VERSION "BodyCAN"

NS_ :

BS_:

BU_: CCM CEM DDM ETC ILCM PDM POT RLDM RRDM SMD SMP TRM Vector_XXX

BO_ 150 CEMBodyFr16: 8 CEM
 SG_ FirstRowLeDefdMassgProgCfg_UB : 5|1@0+ (1,0) [0|1] ""  SMD
 SG_ FirstRowLeDefdMassgProgCfgMassgB : 15|1@0+ (1,0) [0|1] ""  SMD
 SG_ FirstRowLeDefdMassgProgCfgM_0000 : 14|1@0+ (1,0) [0|1] ""  SMD
 SG_ FirstRowLeDefdMassgProgCfgM_0001 : 13|1@0+ (1,0) [0|1] ""  SMD
 SG_ FirstRowLeDefdMassgProgCfgM_0002 : 12|1@0+ (1,0) [0|1] ""  SMD
 SG_ FirstRowLeDefdMassgProgCfgM_0003 : 11|1@0+ (1,0) [0|1] ""  SMD
 SG_ FirstRowLeDefdMassgProgCfgM_0004 : 10|1@0+ (1,0) [0|1] ""  SMD
 SG_ FirstRowLeDefdMassgProgCfgM_0005 : 9|1@0+ (1,0) [0|1] ""  SMD
 SG_ FirstRowLeDefdMassgProgCfgM_0006 : 8|1@0+ (1,0) [0|1] ""  SMD
 SG_ FirstRowLeDefdMassgProgCfgM_0007 : 23|1@0+ (1,0) [0|1] ""  SMD
 SG_ FirstRowLeDefdMassgProgCfgM_0008 : 22|1@0+ (1,0) [0|1] ""  SMD
 SG_ FirstRowLeDefdMassgProgCfgM_0009 : 21|1@0+ (1,0) [0|1] ""  SMD
 SG_ FirstRowLeDefdMassgProgCfgM_0010 : 20|1@0+ (1,0) [0|1] ""  SMD
 SG_ FirstRowLeDefdMassgProgCfgM_0011 : 19|1@0+ (1,0) [0|1] ""  SMD
 SG_ FirstRowLeDefdMassgProgCfgM_0012 : 18|1@0+ (1,0) [0|1] ""  SMD
 SG_ FirstRowLeDefdMassgProgCfgM_0013 : 17|1@0+ (1,0) [0|1] ""  SMD
 SG_ FirstRowLeDefdMassgProgCfgM_0014 : 16|1@0+ (1,0) [0|1] ""  SMD
 SG_ FirstRowLeDefdMassgProgCfgMassgF : 31|2@0+ (1,0) [0|3] ""  SMD
 SG_ FirstRowLeDefdMassgProgCfgMassgI : 29|2@0+ (1,0) [0|3] ""  SMD
 SG_ FirstRowLeDefdMassgProgCfgMassPr : 27|4@0+ (1,0) [0|15] "Unitless"  SMD
 SG_ FirstRowLeDefdMassgProgCfgM_0015 : 1|2@0+ (1,0) [0|3] ""  SMD
 SG_ FirstRowLeDefdMassgProgCfgMassSe : 4|3@0+ (1,0) [0|7] "Unitless"  SMD
 SG_ FirstRowRiDefdMassgProgCfg_UB : 37|1@0+ (1,0) [0|1] ""  SMP
 SG_ FirstRowRiDefdMassgProgCfgMassgB : 47|1@0+ (1,0) [0|1] ""  SMP
 SG_ FirstRowRiDefdMassgProgCfgM_0000 : 46|1@0+ (1,0) [0|1] ""  SMP
 SG_ FirstRowRiDefdMassgProgCfgM_0001 : 45|1@0+ (1,0) [0|1] ""  SMP
 SG_ FirstRowRiDefdMassgProgCfgM_0002 : 44|1@0+ (1,0) [0|1] ""  SMP
 SG_ FirstRowRiDefdMassgProgCfgM_0003 : 43|1@0+ (1,0) [0|1] ""  SMP
 SG_ FirstRowRiDefdMassgProgCfgM_0004 : 42|1@0+ (1,0) [0|1] ""  SMP
 SG_ FirstRowRiDefdMassgProgCfgM_0005 : 41|1@0+ (1,0) [0|1] ""  SMP
 SG_ FirstRowRiDefdMassgProgCfgM_0006 : 40|1@0+ (1,0) [0|1] ""  SMP
 SG_ FirstRowRiDefdMassgProgCfgM_0007 : 55|1@0+ (1,0) [0|1] ""  SMP
 SG_ FirstRowRiDefdMassgProgCfgM_0008 : 54|1@0+ (1,0) [0|1] ""  SMP
 SG_ FirstRowRiDefdMassgProgCfgM_0009 : 53|1@0+ (1,0) [0|1] ""  SMP
 SG_ FirstRowRiDefdMassgProgCfgM_0010 : 52|1@0+ (1,0) [0|1] ""  SMP
 SG_ FirstRowRiDefdMassgProgCfgM_0011 : 51|1@0+ (1,0) [0|1] ""  SMP
 SG_ FirstRowRiDefdMassgProgCfgM_0012 : 50|1@0+ (1,0) [0|1] ""  SMP
 SG_ FirstRowRiDefdMassgProgCfgM_0013 : 49|1@0+ (1,0) [0|1] ""  SMP
 SG_ FirstRowRiDefdMassgProgCfgM_0014 : 48|1@0+ (1,0) [0|1] ""  SMP
 SG_ FirstRowRiDefdMassgProgCfgMassgF : 63|2@0+ (1,0) [0|3] ""  SMP
 SG_ FirstRowRiDefdMassgProgCfgMassgI : 61|2@0+ (1,0) [0|3] ""  SMP
 SG_ FirstRowRiDefdMassgProgCfgMassPr : 59|4@0+ (1,0) [0|15] "Unitless"  SMP
 SG_ FirstRowRiDefdMassgProgCfgM_0015 : 33|2@0+ (1,0) [0|3] ""  SMP
 SG_ FirstRowRiDefdMassgProgCfgMassSe : 36|3@0+ (1,0) [0|7] "Unitless"  SMP

BO_ 528 CEMBodyFr19: 8 CEM
 SG_ CoolgLoadGroup_UB : 24|1@0+ (1,0) [0|1] ""  CCM
 SG_ CoolgLoadGroupCoolgLimd : 39|1@0+ (1,0) [0|1] ""  CCM
 SG_ CoolgLoadGroupCoolgLoad2 : 38|7@0+ (1,0) [0|100] "%"  CCM
 SG_ EngT_UB : 10|1@0+ (1,0) [0|1] ""  CCM
 SG_ EngTEngT : 23|8@0+ (1,-50) [-50|200] "degC"  CCM
 SG_ EngTQf : 9|2@0+ (1,0) [0|3] ""  CCM
 SG_ HvPwrEgyPrio : 42|3@0+ (1,0) [0|7] ""  CCM
 SG_ HvPwrEgyPrio_UB : 43|1@0+ (1,0) [0|1] ""  CCM
 SG_ MirrDefrstAtDrvrCmd : 59|1@0+ (1,0) [0|1] ""  DDM
 SG_ MirrDefrstAtDrvrCmd_UB : 58|1@0+ (1,0) [0|1] ""  DDM
 SG_ MirrDefrstAtPassCmd : 57|1@0+ (1,0) [0|1] ""  PDM
 SG_ MirrDefrstAtPassCmd_UB : 56|1@0+ (1,0) [0|1] ""  PDM
 SG_ PassSeatSts : 55|2@0+ (1,0) [0|3] ""  CCM
 SG_ PassSeatSts_UB : 63|1@0+ (1,0) [0|1] ""  CCM
 SG_ SeatDispBtnPsd_UB : 60|1@0+ (1,0) [0|1] ""  SMD,SMP
 SG_ SeatDispBtnPsdDrvrSeatDispBtnPsd : 61|1@0+ (1,0) [0|1] ""  SMD,SMP
 SG_ SeatDispBtnPsdPassSeatDispBtnPsd : 62|1@0+ (1,0) [0|1] ""  SMD,SMP
 SG_ SeatOccptAtRowSecLe : 27|2@0+ (1,0) [0|3] ""  CCM
 SG_ SeatOccptAtRowSecLe_UB : 28|1@0+ (1,0) [0|1] ""  CCM
 SG_ SeatOccptAtRowSecRi : 30|2@0+ (1,0) [0|3] ""  CCM
 SG_ SeatOccptAtRowSecRi_UB : 31|1@0+ (1,0) [0|1] ""  CCM

BO_ 298 CEMBodyFr20: 8 CEM
 SG_ DoorsOpenerReq_UB : 38|1@0+ (1,0) [0|1] ""  DDM,PDM,RLDM,RRDM
 SG_ DoorsOpenerReqChks : 7|8@0+ (1,0) [0|255] "Unitless"  DDM,PDM,RLDM,RRDM
 SG_ DoorsOpenerReqCntr : 15|4@0+ (1,0) [0|15] "Unitless"  DDM,PDM,RLDM,RRDM
 SG_ DoorsOpenerReqDrvr : 11|2@0+ (1,0) [0|3] ""  DDM,PDM,RLDM,RRDM
 SG_ DoorsOpenerReqLeRe : 9|2@0+ (1,0) [0|3] ""  DDM,PDM,RLDM,RRDM
 SG_ DoorsOpenerReqPass : 23|2@0+ (1,0) [0|3] ""  DDM,PDM,RLDM,RRDM
 SG_ DoorsOpenerReqRiRe : 31|2@0+ (1,0) [0|3] ""  DDM,PDM,RLDM,RRDM
 SG_ DoorsOpenerReqTrigSrcDrvr : 21|3@0+ (1,0) [0|7] ""  DDM,PDM,RLDM,RRDM
 SG_ DoorsOpenerReqTrigSrcLeRe : 18|3@0+ (1,0) [0|7] ""  DDM,PDM,RLDM,RRDM
 SG_ DoorsOpenerReqTrigSrcPass : 29|3@0+ (1,0) [0|7] ""  DDM,PDM,RLDM,RRDM
 SG_ DoorsOpenerReqTrigSrcRiRe : 26|3@0+ (1,0) [0|7] ""  DDM,PDM,RLDM,RRDM
 SG_ DoorsOpenerReqVehMtnSts : 39|1@0+ (1,0) [0|1] ""  DDM,PDM,RLDM,RRDM
 SG_ SecRowRiDefdMassgProgCfg_UB : 37|1@0+ (1,0) [0|1] ""  Vector_XXX
 SG_ SecRowRiDefdMassgProgCfgMassgBag : 47|1@0+ (1,0) [0|1] ""  Vector_XXX
 SG_ SecRowRiDefdMassgProgCfgMas_0000 : 46|1@0+ (1,0) [0|1] ""  Vector_XXX
 SG_ SecRowRiDefdMassgProgCfgMas_0001 : 45|1@0+ (1,0) [0|1] ""  Vector_XXX
 SG_ SecRowRiDefdMassgProgCfgMas_0002 : 44|1@0+ (1,0) [0|1] ""  Vector_XXX
 SG_ SecRowRiDefdMassgProgCfgMas_0003 : 43|1@0+ (1,0) [0|1] ""  Vector_XXX
 SG_ SecRowRiDefdMassgProgCfgMas_0004 : 42|1@0+ (1,0) [0|1] ""  Vector_XXX
 SG_ SecRowRiDefdMassgProgCfgMas_0005 : 41|1@0+ (1,0) [0|1] ""  Vector_XXX
 SG_ SecRowRiDefdMassgProgCfgMas_0006 : 40|1@0+ (1,0) [0|1] ""  Vector_XXX
 SG_ SecRowRiDefdMassgProgCfgMas_0007 : 55|1@0+ (1,0) [0|1] ""  Vector_XXX
 SG_ SecRowRiDefdMassgProgCfgMas_0008 : 54|1@0+ (1,0) [0|1] ""  Vector_XXX
 SG_ SecRowRiDefdMassgProgCfgMas_0009 : 53|1@0+ (1,0) [0|1] ""  Vector_XXX
 SG_ SecRowRiDefdMassgProgCfgMas_0010 : 52|1@0+ (1,0) [0|1] ""  Vector_XXX
 SG_ SecRowRiDefdMassgProgCfgMas_0011 : 51|1@0+ (1,0) [0|1] ""  Vector_XXX
 SG_ SecRowRiDefdMassgProgCfgMas_0012 : 50|1@0+ (1,0) [0|1] ""  Vector_XXX
 SG_ SecRowRiDefdMassgProgCfgMas_0013 : 49|1@0+ (1,0) [0|1] ""  Vector_XXX
 SG_ SecRowRiDefdMassgProgCfgMas_0014 : 48|1@0+ (1,0) [0|1] ""  Vector_XXX
 SG_ SecRowRiDefdMassgProgCfgMassgFrq : 63|2@0+ (1,0) [0|3] ""  Vector_XXX
 SG_ SecRowRiDefdMassgProgCfgMassgInt : 61|2@0+ (1,0) [0|3] ""  Vector_XXX
 SG_ SecRowRiDefdMassgProgCfgMassProg : 59|4@0+ (1,0) [0|15] "Unitless"  Vector_XXX
 SG_ SecRowRiDefdMassgProgCfgMas_0015 : 33|2@0+ (1,0) [0|3] ""  Vector_XXX
 SG_ SecRowRiDefdMassgProgCfgMassSeqC : 36|3@0+ (1,0) [0|7] "Unitless"  Vector_XXX

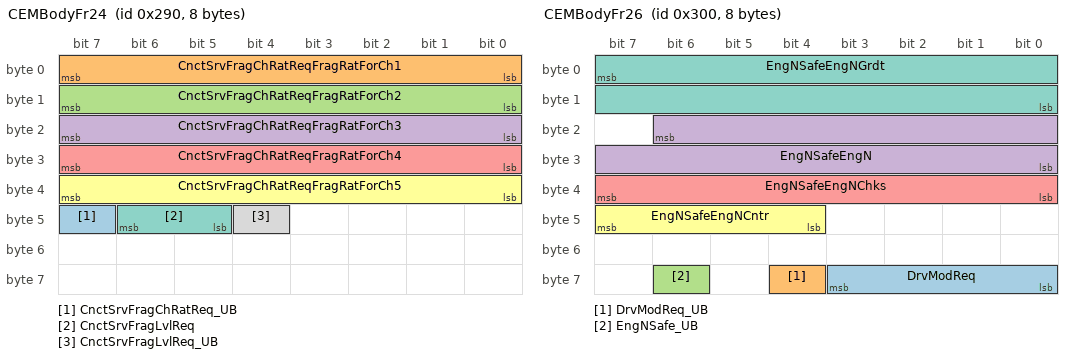
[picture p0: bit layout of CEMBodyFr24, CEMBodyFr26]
BO_ 656 CEMBodyFr24: 8 CEM
 SG_ CnctSrvFragChRatReq_UB : 47|1@0+ (1,0) [0|1] ""  CCM
 SG_ CnctSrvFragChRatReqFragRatForCh1 : 7|8@0+ (1,0) [0|100] "%"  CCM
 SG_ CnctSrvFragChRatReqFragRatForCh2 : 15|8@0+ (1,0) [0|100] "%"  CCM
 SG_ CnctSrvFragChRatReqFragRatForCh3 : 23|8@0+ (1,0) [0|100] "%"  CCM
 SG_ CnctSrvFragChRatReqFragRatForCh4 : 31|8@0+ (1,0) [0|100] "%"  CCM
 SG_ CnctSrvFragChRatReqFragRatForCh5 : 39|8@0+ (1,0) [0|100] "%"  CCM
 SG_ CnctSrvFragLvlReq : 46|2@0+ (1,0) [0|3] ""  CCM
 SG_ CnctSrvFragLvlReq_UB : 44|1@0+ (1,0) [0|1] ""  CCM

BO_ 768 CEMBodyFr26: 8 CEM
 SG_ DrvModReq : 59|4@0+ (1,0) [0|15] ""  CCM,ILCM,SMD
 SG_ DrvModReq_UB : 60|1@0+ (1,0) [0|1] ""  CCM,ILCM,SMD
 SG_ EngNSafe_UB : 62|1@0+ (1,0) [0|1] ""  CCM
 SG_ EngNSafeEngN : 22|15@0+ (0.5,0) [0|16383.5] "rpm"  CCM
 SG_ EngNSafeEngNChks : 39|8@0+ (1,0) [0|255] "Unitless"  CCM
 SG_ EngNSafeEngNCntr : 47|4@0+ (1,0) [0|15] "Unitless"  CCM
 SG_ EngNSafeEngNGrdt : 7|16@0- (1,0) [-30000|32767] "RpmPerSec"  CCM

BO_ 784 CEMBodyFr27: 8 CEM
 SG_ BkpOfDstTrvld : 4|21@0+ (1,0) [0|2000000] "km"  CCM,DDM,ILCM,PDM,POT,RLDM,RRDM,SMD,SMP,TRM
 SG_ BkpOfDstTrvld_UB : 5|1@0+ (1,0) [0|1] ""  CCM,DDM,ILCM,PDM,POT,RLDM,RRDM,SMD,SMP,TRM
 SG_ CamSts_UB : 57|1@0+ (1,0) [0|1] ""  CCM
 SG_ CamStsCamCamFrntCalNotCmpl : 35|1@0+ (1,0) [0|1] ""  CCM
 SG_ CamStsCamCamHeatrActv : 34|1@0+ (1,0) [0|1] ""  CCM
 SG_ CamStsCamFrntBlkd1 : 33|1@0+ (1,0) [0|1] ""  CCM
 SG_ CamStsCamFrntBlkd2 : 32|1@0+ (1,0) [0|1] ""  CCM
 SG_ CamStsCamFrntBlkd3 : 47|1@0+ (1,0) [0|1] ""  CCM
 SG_ CamStsCamFrntBlkd4 : 46|1@0+ (1,0) [0|1] ""  CCM
 SG_ CamStsCamFrntBlkd5 : 45|1@0+ (1,0) [0|1] ""  CCM
 SG_ CamStsCamFrntBlkd6 : 44|1@0+ (1,0) [0|1] ""  CCM
 SG_ CamStsCamFrntBlkd7 : 43|1@0+ (1,0) [0|1] ""  CCM
 SG_ CamStsCamFrntBlkd8 : 42|1@0+ (1,0) [0|1] ""  CCM
 SG_ CamStsCamFrntCalNotStrtd : 41|1@0+ (1,0) [0|1] ""  CCM
 SG_ CamStsCamFrntFaulty : 53|12@0+ (1,0) [0|4095] "Unitless"  CCM
 SG_ CamStsCamFrontEna : 55|1@0+ (1,0) [0|1] ""  CCM
 SG_ CamStsCamMissCom : 54|1@0+ (1,0) [0|1] ""  CCM
 SG_ CamStsChks : 31|8@0+ (1,0) [0|255] "Unitless"  CCM
 SG_ CamStsCntr : 39|4@0+ (1,0) [0|15] "Unitless"  CCM

BO_ 464 CEMBodyFr28: 8 CEM
 SG_ AirTFromHeatgEstimd : 52|13@0- (0.1,0) [-256|255.9] "degC"  CCM
 SG_ AirTFromHeatgEstimd_UB : 53|1@0+ (1,0) [0|1] ""  CCM
 SG_ EcmRoilgCntr : 47|8@0+ (1,0) [0|255] "Unitless"  CCM
 SG_ EcmRoilgCntr_UB : 55|1@0+ (1,0) [0|1] ""  CCM
 SG_ RoadIncln_UB : 29|1@0+ (1,0) [0|1] ""  CCM
 SG_ RoadInclnQly : 31|2@0+ (1,0) [0|3] ""  CCM
 SG_ RoadInclnRoadIncln : 15|16@0- (3.0518E-005,0) [-0.999983306|0.999983306] "rad"  CCM
 SG_ SeatOccptAtRowSecMid : 1|2@0+ (1,0) [0|3] ""  CCM
 SG_ SeatOccptAtRowSecMid_UB : 2|1@0+ (1,0) [0|1] ""  CCM
 SG_ SunCurtPosnSts : 28|5@0+ (1,0) [0|31] ""  CCM
 SG_ SunCurtPosnSts_UB : 54|1@0+ (1,0) [0|1] ""  CCM
 SG_ SunRoofPosnSts : 7|5@0+ (1,0) [0|31] ""  CCM
 SG_ SunRoofPosnSts_UB : 38|1@0+ (1,0) [0|1] ""  CCM
 SG_ WipgInfo_UB : 37|1@0+ (1,0) [0|1] ""  CCM
 SG_ WipgInfoWipgSpdInfo : 34|3@0+ (1,0) [0|7] ""  CCM
 SG_ WipgInfoWiprActv : 35|1@0+ (1,0) [0|1] ""  CCM
 SG_ WipgInfoWiprInWipgAr : 36|1@0+ (1,0) [0|1] ""  CCM

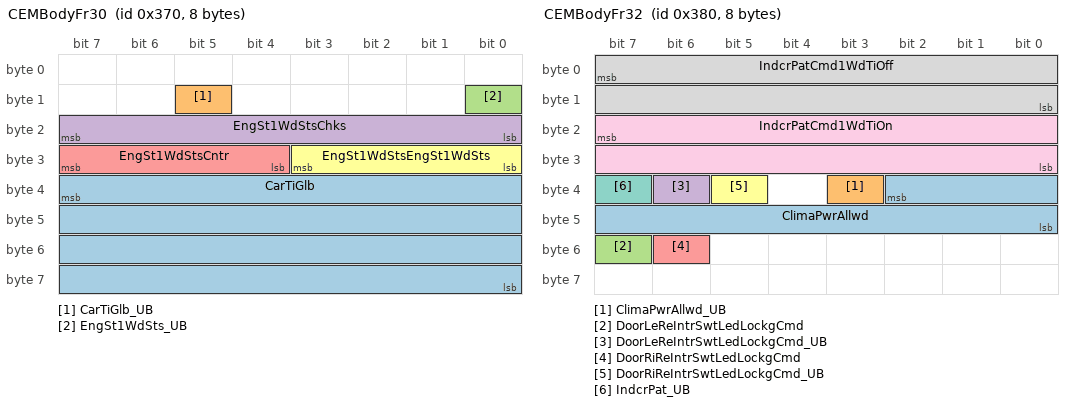
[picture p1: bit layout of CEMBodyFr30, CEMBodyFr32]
BO_ 880 CEMBodyFr30: 8 CEM
 SG_ CarTiGlb : 39|32@0+ (0.1,0) [0|429496729.5] "s"  CCM,DDM,ILCM,PDM,POT,RLDM,RRDM,SMD,SMP,TRM
 SG_ CarTiGlb_UB : 13|1@0+ (1,0) [0|1] ""  CCM,DDM,ILCM,PDM,POT,RLDM,RRDM,SMD,SMP,TRM
 SG_ EngSt1WdSts_UB : 8|1@0+ (1,0) [0|1] ""  CCM,SMD,SMP
 SG_ EngSt1WdStsChks : 23|8@0+ (1,0) [0|255] "Unitless"  CCM,SMD,SMP
 SG_ EngSt1WdStsCntr : 31|4@0+ (1,0) [0|15] "Unitless"  CCM,SMD,SMP
 SG_ EngSt1WdStsEngSt1WdSts : 27|4@0+ (1,0) [0|15] ""  CCM,SMD,SMP

BO_ 896 CEMBodyFr32: 8 CEM
 SG_ ClimaPwrAllwd : 34|11@0+ (1,0) [0|2047] "W"  CCM
 SG_ ClimaPwrAllwd_UB : 35|1@0+ (1,0) [0|1] ""  CCM
 SG_ DoorLeReIntrSwtLedLockgCmd : 55|1@0+ (1,0) [0|1] ""  RLDM
 SG_ DoorLeReIntrSwtLedLockgCmd_UB : 38|1@0+ (1,0) [0|1] ""  RLDM
 SG_ DoorRiReIntrSwtLedLockgCmd : 54|1@0+ (1,0) [0|1] ""  RRDM
 SG_ DoorRiReIntrSwtLedLockgCmd_UB : 37|1@0+ (1,0) [0|1] ""  RRDM
 SG_ IndcrPat_UB : 39|1@0+ (1,0) [0|1] ""  DDM,PDM,TRM
 SG_ IndcrPatCmd1WdTiOff : 7|16@0+ (0.001,0) [0|65.535] "s"  DDM,PDM,TRM
 SG_ IndcrPatCmd1WdTiOn : 23|16@0+ (0.001,0) [0|65.535] "s"  DDM,PDM,TRM

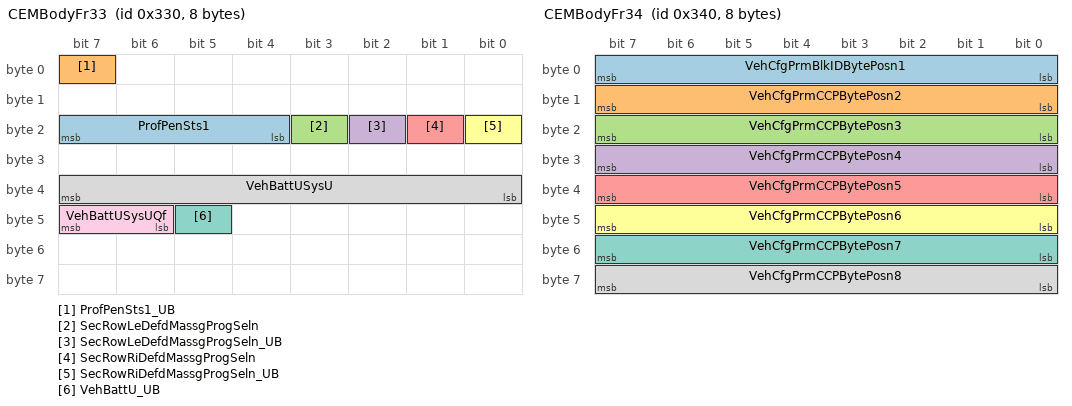
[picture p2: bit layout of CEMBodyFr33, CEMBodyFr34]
BO_ 816 CEMBodyFr33: 8 CEM
 SG_ ProfPenSts1 : 23|4@0+ (1,0) [0|15] ""  DDM,ILCM
 SG_ ProfPenSts1_UB : 7|1@0+ (1,0) [0|1] ""  DDM,ILCM
 SG_ SecRowLeDefdMassgProgSeln : 19|1@0+ (1,0) [0|1] ""  Vector_XXX
 SG_ SecRowLeDefdMassgProgSeln_UB : 18|1@0+ (1,0) [0|1] ""  Vector_XXX
 SG_ SecRowRiDefdMassgProgSeln : 17|1@0+ (1,0) [0|1] ""  Vector_XXX
 SG_ SecRowRiDefdMassgProgSeln_UB : 16|1@0+ (1,0) [0|1] ""  Vector_XXX
 SG_ VehBattU_UB : 45|1@0+ (1,0) [0|1] ""  CCM,DDM,ILCM,PDM,POT,RLDM,RRDM,SMD,SMP,TRM
 SG_ VehBattUSysU : 39|8@0+ (0.1,0) [0|25] "Volt"  CCM,DDM,ILCM,PDM,POT,RLDM,RRDM,SMD,SMP,TRM
 SG_ VehBattUSysUQf : 47|2@0+ (1,0) [0|3] ""  CCM,DDM,ILCM,PDM,POT,RLDM,RRDM,SMD,SMP,TRM

BO_ 832 CEMBodyFr34: 8 CEM
 SG_ VehCfgPrmBlkIDBytePosn1 : 7|8@0+ (1,0) [0|255] "Unitless"  CCM,DDM,ILCM,PDM,POT,RLDM,RRDM,SMD,SMP,TRM
 SG_ VehCfgPrmCCPBytePosn2 : 15|8@0+ (1,0) [0|255] "Unitless"  CCM,DDM,ILCM,PDM,POT,RLDM,RRDM,SMD,SMP,TRM
 SG_ VehCfgPrmCCPBytePosn3 : 23|8@0+ (1,0) [0|255] "Unitless"  CCM,DDM,ILCM,PDM,POT,RLDM,RRDM,SMD,SMP,TRM
 SG_ VehCfgPrmCCPBytePosn4 : 31|8@0+ (1,0) [0|255] "Unitless"  CCM,DDM,ILCM,PDM,POT,RLDM,RRDM,SMD,SMP,TRM
 SG_ VehCfgPrmCCPBytePosn5 : 39|8@0+ (1,0) [0|255] "Unitless"  CCM,DDM,ILCM,PDM,POT,RLDM,RRDM,SMD,SMP,TRM
 SG_ VehCfgPrmCCPBytePosn6 : 47|8@0+ (1,0) [0|255] "Unitless"  CCM,DDM,ILCM,PDM,POT,RLDM,RRDM,SMD,SMP,TRM
 SG_ VehCfgPrmCCPBytePosn7 : 55|8@0+ (1,0) [0|255] "Unitless"  CCM,DDM,ILCM,PDM,POT,RLDM,RRDM,SMD,SMP,TRM
 SG_ VehCfgPrmCCPBytePosn8 : 63|8@0+ (1,0) [0|255] "Unitless"  CCM,DDM,ILCM,PDM,POT,RLDM,RRDM,SMD,SMP,TRM

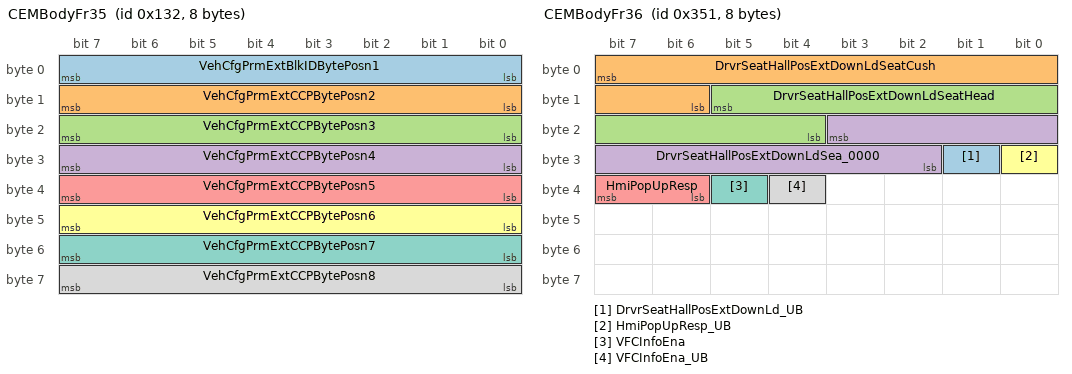
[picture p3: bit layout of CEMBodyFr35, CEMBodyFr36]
BO_ 306 CEMBodyFr35: 8 CEM
 SG_ VehCfgPrmExtBlkIDBytePosn1 : 7|8@0+ (1,0) [0|255] "Unitless"  CCM,DDM,ILCM,PDM,POT,RLDM,RRDM,SMD,SMP,TRM
 SG_ VehCfgPrmExtCCPBytePosn2 : 15|8@0+ (1,0) [0|255] "Unitless"  CCM,DDM,ILCM,PDM,POT,RLDM,RRDM,SMD,SMP,TRM
 SG_ VehCfgPrmExtCCPBytePosn3 : 23|8@0+ (1,0) [0|255] "Unitless"  CCM,DDM,ILCM,PDM,POT,RLDM,RRDM,SMD,SMP,TRM
 SG_ VehCfgPrmExtCCPBytePosn4 : 31|8@0+ (1,0) [0|255] "Unitless"  CCM,DDM,ILCM,PDM,POT,RLDM,RRDM,SMD,SMP,TRM
 SG_ VehCfgPrmExtCCPBytePosn5 : 39|8@0+ (1,0) [0|255] "Unitless"  CCM,DDM,ILCM,PDM,POT,RLDM,RRDM,SMD,SMP,TRM
 SG_ VehCfgPrmExtCCPBytePosn6 : 47|8@0+ (1,0) [0|255] "Unitless"  CCM,DDM,ILCM,PDM,POT,RLDM,RRDM,SMD,SMP,TRM
 SG_ VehCfgPrmExtCCPBytePosn7 : 55|8@0+ (1,0) [0|255] "Unitless"  CCM,DDM,ILCM,PDM,POT,RLDM,RRDM,SMD,SMP,TRM
 SG_ VehCfgPrmExtCCPBytePosn8 : 63|8@0+ (1,0) [0|255] "Unitless"  CCM,DDM,ILCM,PDM,POT,RLDM,RRDM,SMD,SMP,TRM

BO_ 849 CEMBodyFr36: 8 CEM
 SG_ DrvrSeatHallPosExtDownLd_UB : 25|1@0+ (1,0) [0|1] ""  SMD
 SG_ DrvrSeatHallPosExtDownLdSeatCush : 7|10@0+ (1,0) [0|1023] "Unitless"  SMD
 SG_ DrvrSeatHallPosExtDownLdSeatHead : 13|10@0+ (1,0) [0|1023] "Unitless"  SMD
 SG_ DrvrSeatHallPosExtDownLdSea_0000 : 19|10@0+ (1,0) [0|1023] "Unitless"  SMD
 SG_ HmiPopUpResp : 39|2@0+ (1,0) [0|3] ""  CCM
 SG_ HmiPopUpResp_UB : 24|1@0+ (1,0) [0|1] ""  CCM
 SG_ VFCInfoEna : 37|1@0+ (1,0) [0|1] ""  CCM,DDM,PDM,POT,RLDM,RRDM,SMD,SMP,TRM
 SG_ VFCInfoEna_UB : 36|1@0+ (1,0) [0|1] ""  CCM,DDM,PDM,POT,RLDM,RRDM,SMD,SMP,TRM

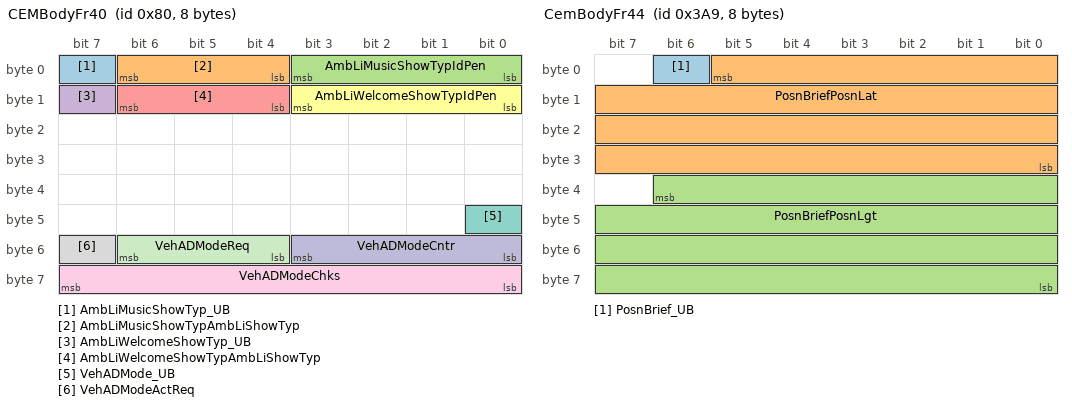
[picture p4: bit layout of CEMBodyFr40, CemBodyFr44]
BO_ 128 CEMBodyFr40: 8 CEM
 SG_ AmbLiMusicShowTyp_UB : 7|1@0+ (1,0) [0|1] ""  ILCM
 SG_ AmbLiMusicShowTypAmbLiShowTyp : 6|3@0+ (1,0) [0|7] ""  ILCM
 SG_ AmbLiMusicShowTypIdPen : 3|4@0+ (1,0) [0|15] ""  ILCM
 SG_ AmbLiWelcomeShowTyp_UB : 15|1@0+ (1,0) [0|1] ""  ILCM
 SG_ AmbLiWelcomeShowTypAmbLiShowTyp : 14|3@0+ (1,0) [0|7] ""  ILCM
 SG_ AmbLiWelcomeShowTypIdPen : 11|4@0+ (1,0) [0|15] ""  ILCM
 SG_ VehADMode_UB : 40|1@0+ (1,0) [0|1] ""  DDM,ILCM
 SG_ VehADModeActReq : 55|1@0+ (1,0) [0|1] ""  DDM,ILCM
 SG_ VehADModeChks : 63|8@0+ (1,0) [0|255] "Unitless"  DDM,ILCM
 SG_ VehADModeCntr : 51|4@0+ (1,0) [0|15] "Unitless"  DDM,ILCM
 SG_ VehADModeReq : 54|3@0+ (1,0) [0|7] ""  DDM,ILCM

BO_ 937 CemBodyFr44: 8 CEM
 SG_ PosnBrief_UB : 6|1@0+ (1,0) [0|1] ""  CCM
 SG_ PosnBriefPosnLat : 5|30@0- (2.77778E-007,0) [-90.000072|90.000072] "Deg"  CCM
 SG_ PosnBriefPosnLgt : 38|31@0- (2.77778E-007,0) [-180.000144|180.000144] "Deg"  CCM

BO_ 928 CemBodyFr46: 8 CEM
 SG_ CmprSpdAct : 55|8@0+ (50,0) [0|12700] "rpm"  CCM
 SG_ CmprSpdAct_UB : 24|1@0+ (1,0) [0|1] ""  CCM
 SG_ HmiAutDefrstEna : 20|1@0+ (1,0) [0|1] ""  CCM
 SG_ HmiAutDefrstEna_UB : 31|1@0+ (1,0) [0|1] ""  CCM
 SG_ HmiAutDefrstReq : 19|1@0+ (1,0) [0|1] ""  CCM
 SG_ HmiAutDefrstReq_UB : 30|1@0+ (1,0) [0|1] ""  CCM
 SG_ HmiClimaFrntAutReq : 18|1@0+ (1,0) [0|1] ""  CCM
 SG_ HmiClimaFrntAutReq_UB : 29|1@0+ (1,0) [0|1] ""  CCM
 SG_ HmiClimaReAutReq : 17|1@0+ (1,0) [0|1] ""  CCM
 SG_ HmiClimaReAutReq_UB : 28|1@0+ (1,0) [0|1] ""  CCM
 SG_ HmiCmptmtAirDistbnFrntLe : 15|3@0+ (1,0) [0|7] ""  CCM
 SG_ HmiCmptmtAirDistbnFrntLe_UB : 27|1@0+ (1,0) [0|1] ""  CCM
 SG_ HmiCmptmtAirDistbnFrntRi : 12|3@0+ (1,0) [0|7] ""  CCM
 SG_ HmiCmptmtAirDistbnFrntRi_UB : 26|1@0+ (1,0) [0|1] ""  CCM
 SG_ HmiCmptmtAirDistbnRe : 23|3@0+ (1,0) [0|7] ""  CCM
 SG_ HmiCmptmtAirDistbnRe_UB : 25|1@0+ (1,0) [0|1] ""  CCM
 SG_ HmiElecAirDirModReq_UB : 40|1@0+ (1,0) [0|1] ""  CCM
 SG_ HmiElecAirDirModReqDrvrMod : 35|2@0+ (1,0) [0|3] ""  CCM
 SG_ HmiElecAirDirModReqPassMod : 33|2@0+ (1,0) [0|3] ""  CCM
 SG_ HmiElecAirSwngReq_UB : 41|1@0+ (1,0) [0|1] ""  CCM
 SG_ HmiElecAirSwngReqDrvrLeRiSwng : 39|1@0+ (1,0) [0|1] ""  CCM
 SG_ HmiElecAirSwngReqDrvrUpOnSwng : 38|1@0+ (1,0) [0|1] ""  CCM
 SG_ HmiElecAirSwngReqPassLeRiSwng : 37|1@0+ (1,0) [0|1] ""  CCM
 SG_ HmiElecAirSwngReqPassUpOnSwng : 36|1@0+ (1,0) [0|1] ""  CCM
 SG_ HmiFragraLvlReq : 47|2@0+ (1,0) [0|3] ""  CCM
 SG_ HmiFragraLvlReq_UB : 42|1@0+ (1,0) [0|1] ""  CCM
 SG_ HmiFragraModReq : 45|2@0+ (1,0) [0|3] ""  CCM
 SG_ HmiFragraModReq_UB : 43|1@0+ (1,0) [0|1] ""  CCM
 SG_ HmiHumCtrlEna : 61|1@0+ (1,0) [0|1] ""  CCM
 SG_ HmiHumCtrlEna_UB : 60|1@0+ (1,0) [0|1] ""  CCM
 SG_ IncomingCO2CtrlFromHmi : 63|1@0+ (1,0) [0|1] ""  CCM
 SG_ IncomingCO2CtrlFromHmi_UB : 62|1@0+ (1,0) [0|1] ""  CCM
 SG_ SecRowLeSeatDispMassgFct_UB : 1|1@0+ (1,0) [0|1] ""  Vector_XXX
 SG_ SecRowLeSeatDispMassgFctMassgInt : 7|2@0+ (1,0) [0|3] ""  Vector_XXX
 SG_ SecRowLeSeatDispMassgFctMassgPro : 5|3@0+ (1,0) [0|7] ""  Vector_XXX
 SG_ SecRowLeSeatDispMassgFctOnOff : 2|1@0+ (1,0) [0|1] ""  Vector_XXX

BO_ 645 CemBodyFr47: 8 CEM
 SG_ BookTrvlClimaActvReq : 15|2@0+ (1,0) [0|3] ""  CCM
 SG_ BookTrvlClimaActvReq_UB : 47|1@0+ (1,0) [0|1] ""  CCM
 SG_ ClimaTmrStsTelmRqrd : 4|1@0+ (1,0) [0|1] ""  CCM
 SG_ ClimaTmrStsTelmRqrd_UB : 46|1@0+ (1,0) [0|1] ""  CCM
 SG_ IntelliClimaReq : 42|3@0+ (1,0) [0|7] ""  CCM
 SG_ IntelliClimaReq_UB : 43|1@0+ (1,0) [0|1] ""  CCM
 SG_ RemVentReq : 7|2@0+ (1,0) [0|3] ""  CCM
 SG_ RemVentReq_UB : 5|1@0+ (1,0) [0|1] ""  CCM
 SG_ SeatHeatDurgClimaEnadFromTelm : 2|3@0+ (1,0) [0|7] ""  CCM
 SG_ SeatHeatDurgClimaEnadFromTelm_UB : 3|1@0+ (1,0) [0|1] ""  CCM
 SG_ SteerWhlHeatgDurgClimaEnadFromTe : 8|1@0+ (1,0) [0|1] ""  CCM
 SG_ SteerWhlHeatgDurgClimaEnadF_0000 : 9|1@0+ (1,0) [0|1] ""  CCM
 SG_ TelmClimaReq : 13|2@0+ (1,0) [0|3] ""  CCM
 SG_ TelmClimaReq_UB : 10|1@0+ (1,0) [0|1] ""  CCM
 SG_ TelmClimaTmr : 23|16@0+ (1,0) [0|65535] "s"  CCM
 SG_ TelmClimaTmr_UB : 11|1@0+ (1,0) [0|1] ""  CCM
 SG_ TelmClimaTSet_UB : 39|1@0+ (1,0) [0|1] ""  CCM
 SG_ TelmClimaTSetHmiCmptmtTSpSpcl : 38|2@0+ (1,0) [0|3] ""  CCM
 SG_ TelmClimaTSetTempRange : 36|5@0+ (0.5,15.5) [15.5|28.5] "degC"  CCM
 SG_ TelmSeatPassVentnClimaLvl : 49|2@0+ (1,0) [0|3] ""  CCM
 SG_ TelmSeatPassVentnClimaLvl_UB : 62|1@0+ (1,0) [0|1] ""  CCM
 SG_ TelmSeatSecLeHeatClimaLvl : 51|2@0+ (1,0) [0|3] ""  CCM
 SG_ TelmSeatSecLeHeatClimaLvl_UB : 61|1@0+ (1,0) [0|1] ""  CCM
 SG_ TelmSeatSecLeVentnClimaLvl : 53|2@0+ (1,0) [0|3] ""  CCM
 SG_ TelmSeatSecLeVentnClimaLvl_UB : 60|1@0+ (1,0) [0|1] ""  CCM
 SG_ TelmSeatSecRiHeatClimaLvl : 55|2@0+ (1,0) [0|3] ""  CCM
 SG_ TelmSeatSecRiHeatClimaLvl_UB : 59|1@0+ (1,0) [0|1] ""  CCM
 SG_ TelmSeatSecRiVentnClimaLvl : 57|2@0+ (1,0) [0|3] ""  CCM
 SG_ TelmSeatSecRiVentnClimaLvl_UB : 58|1@0+ (1,0) [0|1] ""  CCM

BO_ 855 CemBodyFr48: 8 CEM
 SG_ ClimaRqrd1 : 41|2@0+ (1,0) [0|3] ""  CCM
 SG_ ClimaRqrd1_UB : 55|1@0+ (1,0) [0|1] ""  CCM
 SG_ HMIClimaEgySaveReq : 57|2@0+ (1,0) [0|3] ""  CCM
 SG_ HMIClimaEgySaveReq_UB : 52|1@0+ (1,0) [0|1] ""  CCM
 SG_ HmiEcoClimaSetg_UB : 58|1@0+ (1,0) [0|1] ""  CCM
 SG_ HmiEcoClimaSetgIdPen : 62|4@0+ (1,0) [0|15] ""  CCM
 SG_ HmiEcoClimaSetgOnOff1 : 63|1@0+ (1,0) [0|1] ""  CCM
 SG_ MirrPosnFromCldAtDrvr_UB : 45|1@0+ (1,0) [0|1] ""  DDM
 SG_ MirrPosnFromCldAtDrvrMirrPosnAdj : 7|8@0+ (1,0) [0|180] "Deg"  DDM
 SG_ MirrPosnFromCldAtDrvrMirrPo_0000 : 15|8@0+ (1,0) [0|180] "Deg"  DDM
 SG_ MirrPosnFromCldAtPass_UB : 46|1@0+ (1,0) [0|1] ""  DDM
 SG_ MirrPosnFromCldAtPassMirrPosnAdj : 23|8@0+ (1,0) [0|180] "Deg"  DDM
 SG_ MirrPosnFromCldAtPassMirrPo_0000 : 31|8@0+ (1,0) [0|180] "Deg"  DDM
 SG_ ReqFragLvlTelm : 43|2@0+ (1,0) [0|3] ""  CCM
 SG_ ReqFragLvlTelm_UB : 54|1@0+ (1,0) [0|1] ""  CCM
 SG_ TelmAirFragTasteReq : 50|3@0+ (1,0) [0|7] ""  CCM
 SG_ TelmAirFragTasteReq_UB : 51|1@0+ (1,0) [0|1] ""  CCM
 SG_ TelmPM25Req : 44|1@0+ (1,0) [0|1] ""  CCM
 SG_ TelmPM25Req_UB : 53|1@0+ (1,0) [0|1] ""  CCM
 SG_ TelmSeatDrvHeatClimaLvl : 33|2@0+ (1,0) [0|3] ""  CCM
 SG_ TelmSeatDrvHeatClimaLvl_UB : 47|1@0+ (1,0) [0|1] ""  CCM
 SG_ TelmSeatDrvVentnClimaLvl : 35|2@0+ (1,0) [0|3] ""  CCM
 SG_ TelmSeatDrvVentnClimaLvl_UB : 39|1@0+ (1,0) [0|1] ""  CCM
 SG_ TelmSeatPassHeatClimaLvl : 37|2@0+ (1,0) [0|3] ""  CCM
 SG_ TelmSeatPassHeatClimaLvl_UB : 38|1@0+ (1,0) [0|1] ""  CCM

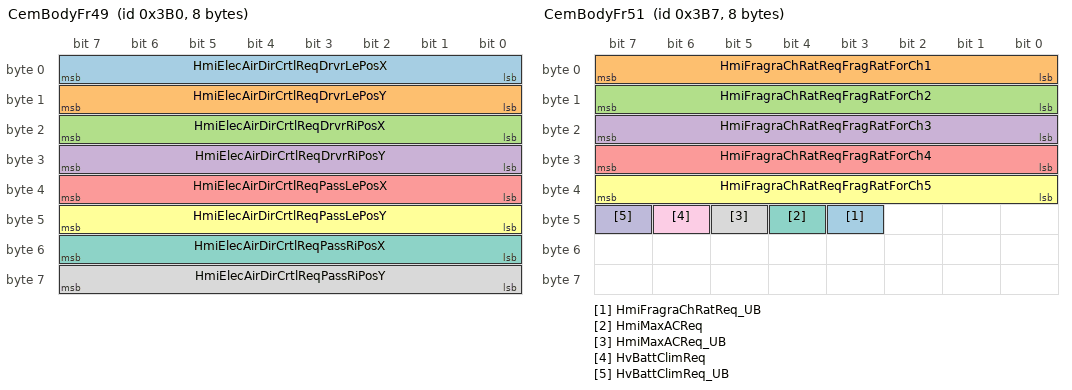
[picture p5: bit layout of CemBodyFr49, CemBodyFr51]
BO_ 944 CemBodyFr49: 8 CEM
 SG_ HmiElecAirDirCrtlReqDrvrLePosX : 7|8@0+ (1,0) [0|255] "Unitless"  CCM
 SG_ HmiElecAirDirCrtlReqDrvrLePosY : 15|8@0+ (1,0) [0|255] "Unitless"  CCM
 SG_ HmiElecAirDirCrtlReqDrvrRiPosX : 23|8@0+ (1,0) [0|255] "Unitless"  CCM
 SG_ HmiElecAirDirCrtlReqDrvrRiPosY : 31|8@0+ (1,0) [0|255] "Unitless"  CCM
 SG_ HmiElecAirDirCrtlReqPassLePosX : 39|8@0+ (1,0) [0|255] "Unitless"  CCM
 SG_ HmiElecAirDirCrtlReqPassLePosY : 47|8@0+ (1,0) [0|255] "Unitless"  CCM
 SG_ HmiElecAirDirCrtlReqPassRiPosX : 55|8@0+ (1,0) [0|255] "Unitless"  CCM
 SG_ HmiElecAirDirCrtlReqPassRiPosY : 63|8@0+ (1,0) [0|255] "Unitless"  CCM

BO_ 951 CemBodyFr51: 8 CEM
 SG_ HmiFragraChRatReq_UB : 43|1@0+ (1,0) [0|1] ""  CCM
 SG_ HmiFragraChRatReqFragRatForCh1 : 7|8@0+ (1,0) [0|100] "%"  CCM
 SG_ HmiFragraChRatReqFragRatForCh2 : 15|8@0+ (1,0) [0|100] "%"  CCM
 SG_ HmiFragraChRatReqFragRatForCh3 : 23|8@0+ (1,0) [0|100] "%"  CCM
 SG_ HmiFragraChRatReqFragRatForCh4 : 31|8@0+ (1,0) [0|100] "%"  CCM
 SG_ HmiFragraChRatReqFragRatForCh5 : 39|8@0+ (1,0) [0|100] "%"  CCM
 SG_ HmiMaxACReq : 44|1@0+ (1,0) [0|1] ""  CCM
 SG_ HmiMaxACReq_UB : 45|1@0+ (1,0) [0|1] ""  CCM
 SG_ HvBattClimReq : 46|1@0+ (1,0) [0|1] ""  CCM
 SG_ HvBattClimReq_UB : 47|1@0+ (1,0) [0|1] ""  CCM

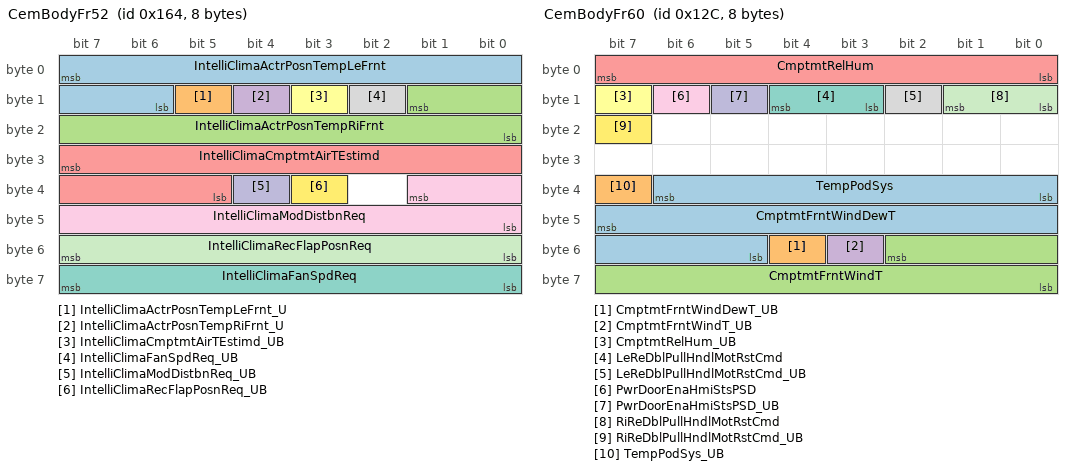
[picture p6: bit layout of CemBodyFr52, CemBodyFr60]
BO_ 356 CemBodyFr52: 8 CEM
 SG_ IntelliClimaActrPosnTempLeFrnt : 7|10@0+ (0.1,0) [0|100] "%"  CCM
 SG_ IntelliClimaActrPosnTempLeFrnt_U : 13|1@0+ (1,0) [0|1] ""  CCM
 SG_ IntelliClimaActrPosnTempRiFrnt : 9|10@0+ (0.1,0) [0|100] "%"  CCM
 SG_ IntelliClimaActrPosnTempRiFrnt_U : 12|1@0+ (1,0) [0|1] ""  CCM
 SG_ IntelliClimaCmptmtAirTEstimd : 31|11@0+ (0.1,-60) [-60|125] "degC"  CCM
 SG_ IntelliClimaCmptmtAirTEstimd_UB : 11|1@0+ (1,0) [0|1] ""  CCM
 SG_ IntelliClimaFanSpdReq : 63|8@0+ (20,300) [300|5400] "rpm"  CCM
 SG_ IntelliClimaFanSpdReq_UB : 10|1@0+ (1,0) [0|1] ""  CCM
 SG_ IntelliClimaModDistbnReq : 33|10@0+ (0.1,0) [0|100] "%"  CCM
 SG_ IntelliClimaModDistbnReq_UB : 36|1@0+ (1,0) [0|1] ""  CCM
 SG_ IntelliClimaRecFlapPosnReq : 55|8@0+ (1,0) [0|100] "%"  CCM
 SG_ IntelliClimaRecFlapPosnReq_UB : 35|1@0+ (1,0) [0|1] ""  CCM

BO_ 151 CemBodyFr54: 8 CEM
 SG_ BackRestSideSpprtAdjmtRowFirstDr : 31|2@0+ (1,0) [0|3] ""  SMD
 SG_ BackRestSideSpprtAdjmtRowFi_0000 : 23|1@0+ (1,0) [0|1] ""  SMD
 SG_ BackRestSideSpprtAdjmtRowFirstPa : 29|2@0+ (1,0) [0|3] ""  SMP
 SG_ BackRestSideSpprtAdjmtRowFi_0001 : 22|1@0+ (1,0) [0|1] ""  SMP
 SG_ EasyInOutSecRowLeActv : 27|1@0+ (1,0) [0|1] ""  Vector_XXX
 SG_ EasyInOutSecRowLeActv_UB : 21|1@0+ (1,0) [0|1] ""  Vector_XXX
 SG_ EasyInOutSecRowLeReq : 26|1@0+ (1,0) [0|1] ""  Vector_XXX
 SG_ EasyInOutSecRowLeReq_UB : 63|1@0+ (1,0) [0|1] ""  Vector_XXX
 SG_ EasyInOutSecRowRiActv : 25|1@0+ (1,0) [0|1] ""  Vector_XXX
 SG_ EasyInOutSecRowRiActv_UB : 62|1@0+ (1,0) [0|1] ""  Vector_XXX
 SG_ EasyInOutSecRowRiReq : 24|1@0+ (1,0) [0|1] ""  Vector_XXX
 SG_ EasyInOutSecRowRiReq_UB : 61|1@0+ (1,0) [0|1] ""  Vector_XXX
 SG_ LumHeiAdjmtRowFirstDrvr : 47|2@0+ (1,0) [0|3] ""  SMD
 SG_ LumHeiAdjmtRowFirstDrvr_UB : 60|1@0+ (1,0) [0|1] ""  SMD
 SG_ LumHeiAdjmtRowFirstPass : 45|2@0+ (1,0) [0|3] ""  SMP
 SG_ LumHeiAdjmtRowFirstPass_UB : 59|1@0+ (1,0) [0|1] ""  SMP
 SG_ LumLenAdjmtRowFirstDrvr : 43|2@0+ (1,0) [0|3] ""  SMD
 SG_ LumLenAdjmtRowFirstDrvr_UB : 58|1@0+ (1,0) [0|1] ""  SMD
 SG_ LumLenAdjmtRowFirstPass : 41|2@0+ (1,0) [0|3] ""  SMP
 SG_ LumLenAdjmtRowFirstPass_UB : 57|1@0+ (1,0) [0|1] ""  SMP

BO_ 153 CemBodyFr55: 8 CEM
 SG_ CushExtnFirstDrvr : 27|2@0+ (1,0) [0|3] ""  SMD
 SG_ CushExtnFirstDrvr_UB : 54|1@0+ (1,0) [0|1] ""  SMD
 SG_ CushExtnFirstPass : 25|2@0+ (1,0) [0|3] ""  SMP
 SG_ CushExtnFirstPass_UB : 55|1@0+ (1,0) [0|1] ""  SMP
 SG_ CushSideSpprtAdjmtRowFirstDrvr : 39|2@0+ (1,0) [0|3] ""  SMD
 SG_ CushSideSpprtAdjmtRowFirstDrvr_U : 40|1@0+ (1,0) [0|1] ""  SMD
 SG_ CushSideSpprtAdjmtRowFirstPass : 37|2@0+ (1,0) [0|3] ""  SMP
 SG_ CushSideSpprtAdjmtRowFirstPass_U : 41|1@0+ (1,0) [0|1] ""  SMP
 SG_ HdRestAdjmtRowFirstDrvr : 19|2@0+ (1,0) [0|3] ""  SMD
 SG_ HdRestAdjmtRowFirstDrvr_UB : 50|1@0+ (1,0) [0|1] ""  SMD
 SG_ HdRestAdjmtRowFirstPass : 17|2@0+ (1,0) [0|3] ""  SMP
 SG_ HdRestAdjmtRowFirstPass_UB : 51|1@0+ (1,0) [0|1] ""  SMP
 SG_ HdRestHeiAdjmtRowFirstDrvr : 31|2@0+ (1,0) [0|3] ""  SMD
 SG_ HdRestHeiAdjmtRowFirstDrvr_UB : 52|1@0+ (1,0) [0|1] ""  SMD
 SG_ HdRestHeiAdjmtRowFirstPass : 29|2@0+ (1,0) [0|3] ""  SMP
 SG_ HdRestHeiAdjmtRowFirstPass_UB : 53|1@0+ (1,0) [0|1] ""  SMP
 SG_ HvahFltIndcnReq : 46|1@0+ (1,0) [0|1] ""  CCM
 SG_ HvahFltIndcnReq_UB : 45|1@0+ (1,0) [0|1] ""  CCM
 SG_ LumHeiAdjmtSecRowLe : 23|2@0+ (1,0) [0|3] ""  Vector_XXX
 SG_ LumHeiAdjmtSecRowLe_UB : 43|1@0+ (1,0) [0|1] ""  Vector_XXX
 SG_ LumHeiAdjmtSecRowRi : 21|2@0+ (1,0) [0|3] ""  Vector_XXX
 SG_ LumHeiAdjmtSecRowRi_UB : 42|1@0+ (1,0) [0|1] ""  Vector_XXX
 SG_ LumLenAdjmtSecRowLe : 35|2@0+ (1,0) [0|3] ""  Vector_XXX
 SG_ LumLenAdjmtSecRowLe_UB : 49|1@0+ (1,0) [0|1] ""  Vector_XXX
 SG_ LumLenAdjmtSecRowRi : 33|2@0+ (1,0) [0|3] ""  Vector_XXX
 SG_ LumLenAdjmtSecRowRi_UB : 48|1@0+ (1,0) [0|1] ""  Vector_XXX
 SG_ PassAirbSts : 47|1@0+ (1,0) [0|1] ""  SMP
 SG_ PassAirbSts_UB : 44|1@0+ (1,0) [0|1] ""  SMP

BO_ 300 CemBodyFr60: 8 CEM
 SG_ CmptmtFrntWindDewT : 47|11@0+ (0.1,-40) [-40|164.7] "degC"  CCM
 SG_ CmptmtFrntWindDewT_UB : 52|1@0+ (1,0) [0|1] ""  CCM
 SG_ CmptmtFrntWindT : 50|11@0+ (0.1,-40) [-40|164.7] "degC"  CCM
 SG_ CmptmtFrntWindT_UB : 51|1@0+ (1,0) [0|1] ""  CCM
 SG_ CmptmtRelHum : 7|8@0+ (0.5,0) [0|100] "%"  CCM
 SG_ CmptmtRelHum_UB : 15|1@0+ (1,0) [0|1] ""  CCM
 SG_ LeReDblPullHndlMotRstCmd : 12|2@0+ (1,0) [0|3] ""  RLDM
 SG_ LeReDblPullHndlMotRstCmd_UB : 10|1@0+ (1,0) [0|1] ""  RLDM
 SG_ PwrDoorEnaHmiStsPSD : 14|1@0+ (1,0) [0|1] ""  Vector_XXX
 SG_ PwrDoorEnaHmiStsPSD_UB : 13|1@0+ (1,0) [0|1] ""  Vector_XXX
 SG_ RiReDblPullHndlMotRstCmd : 9|2@0+ (1,0) [0|3] ""  RRDM
 SG_ RiReDblPullHndlMotRstCmd_UB : 23|1@0+ (1,0) [0|1] ""  RRDM
 SG_ TempPodSys : 38|7@0+ (1,-40) [-40|85] "degC"  DDM,PDM,RLDM,RRDM
 SG_ TempPodSys_UB : 39|1@0+ (1,0) [0|1] ""  DDM,PDM,RLDM,RRDM

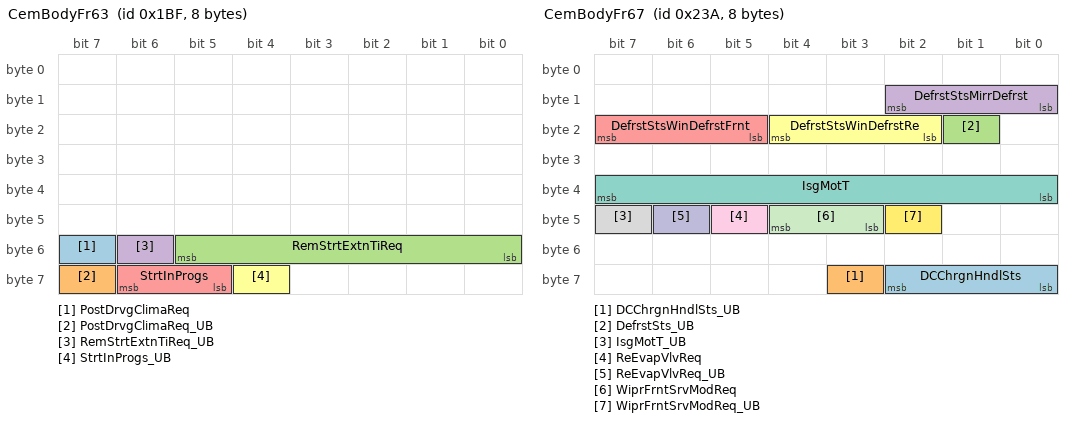
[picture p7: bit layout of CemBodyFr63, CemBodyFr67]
BO_ 447 CemBodyFr63: 8 CEM
 SG_ PostDrvgClimaReq : 55|1@0+ (1,0) [0|1] ""  CCM
 SG_ PostDrvgClimaReq_UB : 63|1@0+ (1,0) [0|1] ""  CCM
 SG_ RemStrtExtnTiReq : 53|6@0+ (1,0) [0|59] "Mins"  CCM
 SG_ RemStrtExtnTiReq_UB : 54|1@0+ (1,0) [0|1] ""  CCM
 SG_ StrtInProgs : 62|2@0+ (1,0) [0|3] ""  CCM
 SG_ StrtInProgs_UB : 60|1@0+ (1,0) [0|1] ""  CCM

BO_ 570 CemBodyFr67: 8 CEM
 SG_ DCChrgnHndlSts : 58|3@0+ (1,0) [0|7] ""  CCM
 SG_ DCChrgnHndlSts_UB : 59|1@0+ (1,0) [0|1] ""  CCM
 SG_ DefrstSts_UB : 17|1@0+ (1,0) [0|1] ""  CCM
 SG_ DefrstStsMirrDefrst : 10|3@0+ (1,0) [0|7] ""  CCM
 SG_ DefrstStsWinDefrstFrnt : 23|3@0+ (1,0) [0|7] ""  CCM
 SG_ DefrstStsWinDefrstRe : 20|3@0+ (1,0) [0|7] ""  CCM
 SG_ IsgMotT : 39|8@0+ (1,-50) [-50|200] "degC"  CCM
 SG_ IsgMotT_UB : 47|1@0+ (1,0) [0|1] ""  CCM
 SG_ ReEvapVlvReq : 45|1@0+ (1,0) [0|1] ""  CCM
 SG_ ReEvapVlvReq_UB : 46|1@0+ (1,0) [0|1] ""  CCM
 SG_ WiprFrntSrvModReq : 44|2@0+ (1,0) [0|3] ""  CCM
 SG_ WiprFrntSrvModReq_UB : 42|1@0+ (1,0) [0|1] ""  CCM

BO_ 178 CemBodyFr68: 8 CEM
 SG_ BootFoldSwtActv2 : 48|1@0+ (1,0) [0|1] ""  Vector_XXX
 SG_ BootFoldSwtActv2_UB : 49|1@0+ (1,0) [0|1] ""  Vector_XXX
 SG_ BootFoldSwtActv3 : 56|1@0+ (1,0) [0|1] ""  Vector_XXX
 SG_ BootFoldSwtActv3_UB : 57|1@0+ (1,0) [0|1] ""  Vector_XXX
 SG_ ClimaRqrdFromHmi : 18|2@0+ (1,0) [0|3] ""  CCM
 SG_ ClimaRqrdFromHmi_UB : 26|1@0+ (1,0) [0|1] ""  CCM
 SG_ LVPwrSplyErrSts : 23|4@0+ (1,0) [0|15] ""  CCM
 SG_ LVPwrSplyErrSts_UB : 19|1@0+ (1,0) [0|1] ""  CCM
 SG_ SecRowLeCmftSet : 33|2@0+ (1,0) [0|3] ""  Vector_XXX
 SG_ SecRowLeCmftSet_UB : 34|1@0+ (1,0) [0|1] ""  Vector_XXX
 SG_ TiDrvgCycOff : 7|16@0+ (1,0) [0|65535] "Unitless"  CCM
 SG_ TiDrvgCycOff_UB : 40|1@0+ (1,0) [0|1] ""  CCM
 SG_ WinOpenDrvrReq : 39|5@0+ (1,0) [0|31] ""  DDM
 SG_ WinOpenDrvrReq_UB : 41|1@0+ (1,0) [0|1] ""  DDM
 SG_ WinOpenPassReq : 47|5@0+ (1,0) [0|31] ""  PDM
 SG_ WinOpenPassReq_UB : 42|1@0+ (1,0) [0|1] ""  PDM
 SG_ WinOpenReLeReq : 55|5@0+ (1,0) [0|31] ""  RLDM
 SG_ WinOpenReLeReq_UB : 50|1@0+ (1,0) [0|1] ""  RLDM
 SG_ WinOpenReRiReq : 63|5@0+ (1,0) [0|31] ""  RRDM
 SG_ WinOpenReRiReq_UB : 58|1@0+ (1,0) [0|1] ""  RRDM
 SG_ WinVentnOpenReq : 16|1@0+ (1,0) [0|1] ""  DDM,PDM,RLDM,RRDM
 SG_ WinVentnOpenReq_UB : 24|1@0+ (1,0) [0|1] ""  DDM,PDM,RLDM,RRDM

BO_ 196 CemBodyFr69: 8 CEM
 SG_ DoorOpenwarnLeIndcn : 55|2@0+ (1,0) [0|3] ""  DDM,ILCM,PDM
 SG_ DoorOpenwarnLeIndcn_UB : 43|1@0+ (1,0) [0|1] ""  DDM,ILCM,PDM
 SG_ DoorOpenwarnRiIndcn : 53|2@0+ (1,0) [0|3] ""  DDM,ILCM,PDM
 SG_ DoorOpenwarnRiIndcn_UB : 42|1@0+ (1,0) [0|1] ""  DDM,ILCM,PDM
 SG_ LoadAndStoreReq_UB : 18|1@0+ (1,0) [0|1] ""  DDM,PDM,SMD
 SG_ LoadAndStoreReqErgoPosn : 17|2@0+ (1,0) [0|3] ""  DDM,PDM,SMD
 SG_ LoadAndStoreReqErgoSetgEve : 31|3@0+ (1,0) [0|7] ""  DDM,PDM,SMD
 SG_ LoadAndStoreReqIdPen : 27|4@0+ (1,0) [0|15] ""  DDM,PDM,SMD
 SG_ LoadAndStoreReqInOutEasy : 28|1@0+ (1,0) [0|1] ""  DDM,PDM,SMD
 SG_ PwrAvlDelta : 7|16@0- (1,0) [-32768|32767] "W"  CCM
 SG_ PwrAvlDelta_UB : 38|1@0+ (1,0) [0|1] ""  CCM
 SG_ RctaIndcnLe : 51|2@0+ (1,0) [0|3] ""  DDM,PDM
 SG_ RctaIndcnLe_UB : 41|1@0+ (1,0) [0|1] ""  DDM,PDM
 SG_ RctaIndcnRi : 49|2@0+ (1,0) [0|3] ""  DDM,PDM
 SG_ RctaIndcnRi_UB : 40|1@0+ (1,0) [0|1] ""  DDM,PDM
 SG_ VehWinSunRoofClsReq : 23|2@0+ (1,0) [0|3] ""  DDM,PDM,RLDM,RRDM
 SG_ VehWinSunRoofClsReq_UB : 21|1@0+ (1,0) [0|1] ""  DDM,PDM,RLDM,RRDM

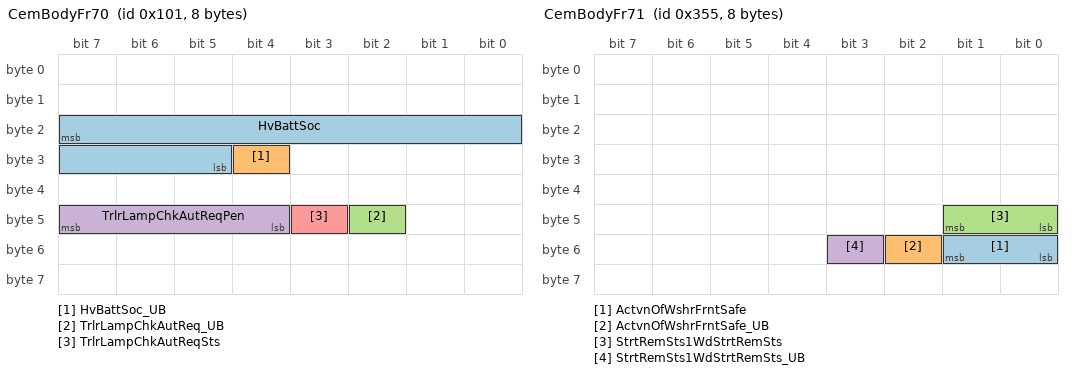
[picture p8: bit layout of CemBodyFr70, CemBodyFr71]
BO_ 257 CemBodyFr70: 8 CEM
 SG_ HvBattSoc : 23|11@0+ (0.05,0) [0|100] "%"  CCM
 SG_ HvBattSoc_UB : 28|1@0+ (1,0) [0|1] ""  CCM
 SG_ TrlrLampChkAutReq_UB : 42|1@0+ (1,0) [0|1] ""  TRM
 SG_ TrlrLampChkAutReqPen : 47|4@0+ (1,0) [0|15] ""  TRM
 SG_ TrlrLampChkAutReqSts : 43|1@0+ (1,0) [0|1] ""  TRM

BO_ 853 CemBodyFr71: 8 CEM
 SG_ ActvnOfWshrFrntSafe : 49|2@0+ (1,0) [0|3] ""  CCM
 SG_ ActvnOfWshrFrntSafe_UB : 50|1@0+ (1,0) [0|1] ""  CCM
 SG_ StrtRemSts1WdStrtRemSts : 41|2@0+ (1,0) [0|3] ""  CCM
 SG_ StrtRemSts1WdStrtRemSts_UB : 51|1@0+ (1,0) [0|1] ""  CCM

BO_ 152 CemBodyFr73: 8 CEM
 SG_ CbnOverHeatProtnEnaFromTelm : 63|1@0+ (1,0) [0|1] ""  CCM
 SG_ CbnOverHeatProtnEnaFromTelm_UB : 62|1@0+ (1,0) [0|1] ""  CCM
 SG_ DrvrDesDir_UB : 48|1@0+ (1,0) [0|1] ""  DDM
 SG_ DrvrDesDirChks : 47|8@0+ (1,0) [0|255] "Unitless"  DDM
 SG_ DrvrDesDirCntr : 55|4@0+ (1,0) [0|15] "Unitless"  DDM
 SG_ DrvrDesDirDrvrDesDir : 51|3@0+ (1,0) [0|7] ""  DDM
 SG_ HvEgyCnsAllwdForClima : 39|8@0+ (50,0) [0|12750] "Wh"  CCM
 SG_ HvEgyCnsAllwdForClima_UB : 61|1@0+ (1,0) [0|1] ""  CCM
 SG_ OnBdChrgrSt : 27|4@0+ (1,0) [0|15] ""  CCM,ILCM
 SG_ OnBdChrgrSt_UB : 59|1@0+ (1,0) [0|1] ""  CCM,ILCM
 SG_ PassSceneModSeld : 7|4@0+ (1,0) [0|15] ""  ILCM
 SG_ PassSceneModSeld_UB : 58|1@0+ (1,0) [0|1] ""  ILCM
 SG_ SecRowLeSceneModSeld : 3|4@0+ (1,0) [0|15] ""  ILCM
 SG_ SecRowLeSceneModSeld_UB : 57|1@0+ (1,0) [0|1] ""  ILCM
 SG_ SecRowRiSceneModSeld : 15|4@0+ (1,0) [0|15] ""  ILCM
 SG_ SecRowRiSceneModSeld_UB : 56|1@0+ (1,0) [0|1] ""  ILCM
 SG_ SpeechSts : 11|2@0+ (1,0) [0|3] ""  ILCM
 SG_ SpeechSts_UB : 28|1@0+ (1,0) [0|1] ""  ILCM
 SG_ TrRelsReq : 9|2@0+ (1,0) [0|3] ""  POT
 SG_ TrRelsReq_UB : 29|1@0+ (1,0) [0|1] ""  POT

BO_ 309 CemBodyFr74: 8 CEM
 SG_ BackRestAdjmtRowFirstDrvr : 7|2@0+ (1,0) [0|3] ""  SMD
 SG_ BackRestAdjmtRowFirstDrvr_UB : 23|1@0+ (1,0) [0|1] ""  SMD
 SG_ BackRestAdjmtRowFirstPass : 5|2@0+ (1,0) [0|3] ""  SMP
 SG_ BackRestAdjmtRowFirstPass_UB : 22|1@0+ (1,0) [0|1] ""  SMP
 SG_ ClimaBoostAutSet_UB : 30|1@0+ (1,0) [0|1] ""  Vector_XXX
 SG_ ClimaBoostAutSetColdAutoOnOff : 44|1@0+ (1,0) [0|1] ""  Vector_XXX
 SG_ ClimaBoostAutSetColdDeltaTemp : 47|2@0+ (5,0) [0|10] "degC"  Vector_XXX
 SG_ ClimaBoostAutSetDurOfFunction : 39|6@0+ (1,0) [0|60] "Mins"  Vector_XXX
 SG_ ClimaBoostAutSetHotAutoOnOff : 45|1@0+ (1,0) [0|1] ""  Vector_XXX
 SG_ ClimaBoostAutSetHotDeltaTemp : 33|2@0+ (5,0) [0|10] "degC"  Vector_XXX
 SG_ ClimaRefreshAutSet_UB : 48|1@0+ (1,0) [0|1] ""  Vector_XXX
 SG_ ClimaRefreshAutSetActvtOnExit : 49|1@0+ (1,0) [0|1] ""  Vector_XXX
 SG_ ClimaRefreshAutSetAutoOnOff : 41|2@0+ (1,0) [0|3] ""  Vector_XXX
 SG_ ClimaRefreshAutSetDurOfFunction : 55|6@0+ (1,0) [0|60] "Mins"  Vector_XXX
 SG_ ClimaRefreshCmd : 43|2@0+ (1,0) [0|3] ""  Vector_XXX
 SG_ ClimaRefreshCmd_UB : 31|1@0+ (1,0) [0|1] ""  Vector_XXX
 SG_ ClimateBoostCmd : 59|2@0+ (1,0) [0|3] ""  Vector_XXX
 SG_ ClimateBoostCmd_UB : 63|1@0+ (1,0) [0|1] ""  Vector_XXX
 SG_ EmgyBrkLiIndcrTurn : 25|2@0+ (1,0) [0|3] ""  TRM
 SG_ EmgyBrkLiIndcrTurn_UB : 26|1@0+ (1,0) [0|1] ""  TRM
 SG_ SeatCushTiltAdjmtRowFirstDrvr : 3|2@0+ (1,0) [0|3] ""  SMD
 SG_ SeatCushTiltAdjmtRowFirstDrvr_UB : 21|1@0+ (1,0) [0|1] ""  SMD
 SG_ SeatCushTiltAdjmtRowFirstPass : 1|2@0+ (1,0) [0|3] ""  SMP
 SG_ SeatCushTiltAdjmtRowFirstPass_UB : 20|1@0+ (1,0) [0|1] ""  SMP
 SG_ SeatHeiAdjmtRowFirstDrvr : 15|2@0+ (1,0) [0|3] ""  SMD
 SG_ SeatHeiAdjmtRowFirstDrvr_UB : 19|1@0+ (1,0) [0|1] ""  SMD
 SG_ SeatHeiAdjmtRowFirstPass : 13|2@0+ (1,0) [0|3] ""  SMP
 SG_ SeatHeiAdjmtRowFirstPass_UB : 18|1@0+ (1,0) [0|1] ""  SMP
 SG_ SeatLenAdjmtRowFirstDrvr : 11|2@0+ (1,0) [0|3] ""  SMD
 SG_ SeatLenAdjmtRowFirstDrvr_UB : 17|1@0+ (1,0) [0|1] ""  SMD
 SG_ SeatLenAdjmtRowFirstPass : 9|2@0+ (1,0) [0|3] ""  SMP
 SG_ SeatLenAdjmtRowFirstPass_UB : 16|1@0+ (1,0) [0|1] ""  SMP

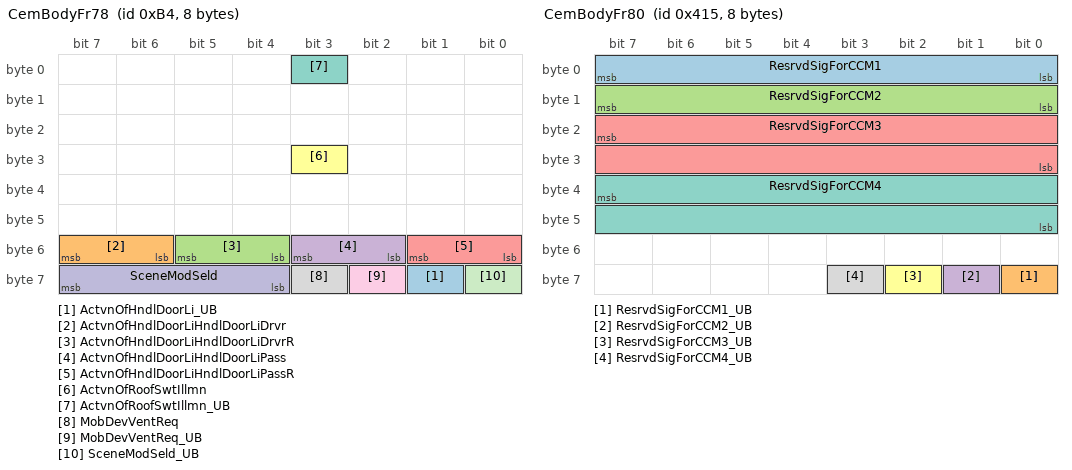
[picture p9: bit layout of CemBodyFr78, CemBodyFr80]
BO_ 180 CemBodyFr78: 8 CEM
 SG_ ActvnOfHndlDoorLi_UB : 57|1@0+ (1,0) [0|1] ""  DDM,PDM,RLDM,RRDM
 SG_ ActvnOfHndlDoorLiHndlDoorLiDrvr : 55|2@0+ (1,0) [0|3] ""  DDM,PDM,RLDM,RRDM
 SG_ ActvnOfHndlDoorLiHndlDoorLiDrvrR : 53|2@0+ (1,0) [0|3] ""  DDM,PDM,RLDM,RRDM
 SG_ ActvnOfHndlDoorLiHndlDoorLiPass : 51|2@0+ (1,0) [0|3] ""  DDM,PDM,RLDM,RRDM
 SG_ ActvnOfHndlDoorLiHndlDoorLiPassR : 49|2@0+ (1,0) [0|3] ""  DDM,PDM,RLDM,RRDM
 SG_ ActvnOfRoofSwtIllmn : 27|1@0+ (1,0) [0|1] ""  Vector_XXX
 SG_ ActvnOfRoofSwtIllmn_UB : 3|1@0+ (1,0) [0|1] ""  Vector_XXX
 SG_ MobDevVentReq : 59|1@0+ (1,0) [0|1] ""  DDM,PDM,RLDM,RRDM
 SG_ MobDevVentReq_UB : 58|1@0+ (1,0) [0|1] ""  DDM,PDM,RLDM,RRDM
 SG_ SceneModSeld : 63|4@0+ (1,0) [0|15] ""  CCM,ILCM
 SG_ SceneModSeld_UB : 56|1@0+ (1,0) [0|1] ""  CCM,ILCM

BO_ 1045 CemBodyFr80: 8 CEM
 SG_ ResrvdSigForCCM1 : 7|8@0+ (1,0) [0|255] "Unitless"  CCM
 SG_ ResrvdSigForCCM1_UB : 56|1@0+ (1,0) [0|1] ""  CCM
 SG_ ResrvdSigForCCM2 : 15|8@0+ (1,0) [0|255] "Unitless"  CCM
 SG_ ResrvdSigForCCM2_UB : 57|1@0+ (1,0) [0|1] ""  CCM
 SG_ ResrvdSigForCCM3 : 23|16@0+ (1,0) [0|65535] "Unitless"  CCM
 SG_ ResrvdSigForCCM3_UB : 58|1@0+ (1,0) [0|1] ""  CCM
 SG_ ResrvdSigForCCM4 : 39|16@0+ (1,0) [0|65535] "Unitless"  CCM
 SG_ ResrvdSigForCCM4_UB : 59|1@0+ (1,0) [0|1] ""  CCM

BO_ 468 CemBodyFr84: 8 CEM
 SG_ ActiveZoneIinfo_UB : 47|1@0+ (1,0) [0|1] ""  ILCM
 SG_ ActiveZoneIinfoZone1ONOff : 5|1@0+ (1,0) [0|1] ""  ILCM
 SG_ ActiveZoneIinfoZone2ONOff : 6|1@0+ (1,0) [0|1] ""  ILCM
 SG_ ActiveZoneIinfoZone3ONOff : 7|1@0+ (1,0) [0|1] ""  ILCM
 SG_ CrashStsSafe_UB : 45|1@0+ (1,0) [0|1] ""  DDM,PDM,RLDM,RRDM
 SG_ CrashStsSafeChks : 55|8@0+ (1,0) [0|255] "Unitless"  DDM,PDM,RLDM,RRDM
 SG_ CrashStsSafeCntr : 43|4@0+ (1,0) [0|15] "Unitless"  DDM,PDM,RLDM,RRDM
 SG_ CrashStsSafeSts : 44|1@0+ (1,0) [0|1] ""  DDM,PDM,RLDM,RRDM
 SG_ DrvrSeatDispMassgFct_UB : 31|1@0+ (1,0) [0|1] ""  SMD
 SG_ DrvrSeatDispMassgFctMassgInten : 21|2@0+ (1,0) [0|3] ""  SMD
 SG_ DrvrSeatDispMassgFctMassgProg : 19|3@0+ (1,0) [0|7] ""  SMD
 SG_ DrvrSeatDispMassgFctOnOff : 16|1@0+ (1,0) [0|1] ""  SMD
 SG_ DrvrSeatDispSpplFct : 2|3@0+ (1,0) [0|7] ""  SMD
 SG_ DrvrSeatDispSpplFct_UB : 3|1@0+ (1,0) [0|1] ""  SMD
 SG_ PassSeatDispMassgFct_UB : 30|1@0+ (1,0) [0|1] ""  SMP
 SG_ PassSeatDispMassgFctMassgInten : 29|2@0+ (1,0) [0|3] ""  SMP
 SG_ PassSeatDispMassgFctMassgProg : 27|3@0+ (1,0) [0|7] ""  SMP
 SG_ PassSeatDispMassgFctOnOff : 24|1@0+ (1,0) [0|1] ""  SMP
 SG_ PassSeatDispSpplFct : 15|3@0+ (1,0) [0|7] ""  SMP
 SG_ PassSeatDispSpplFct_UB : 4|1@0+ (1,0) [0|1] ""  SMP
 SG_ RemStrtHvCtrlReq_UB : 46|1@0+ (1,0) [0|1] ""  CCM
 SG_ RemStrtHvCtrlReqErsCmd : 63|2@0+ (1,0) [0|3] ""  CCM
 SG_ RemStrtHvCtrlReqErsRunTime : 61|6@0+ (1,0) [0|59] "Mins"  CCM

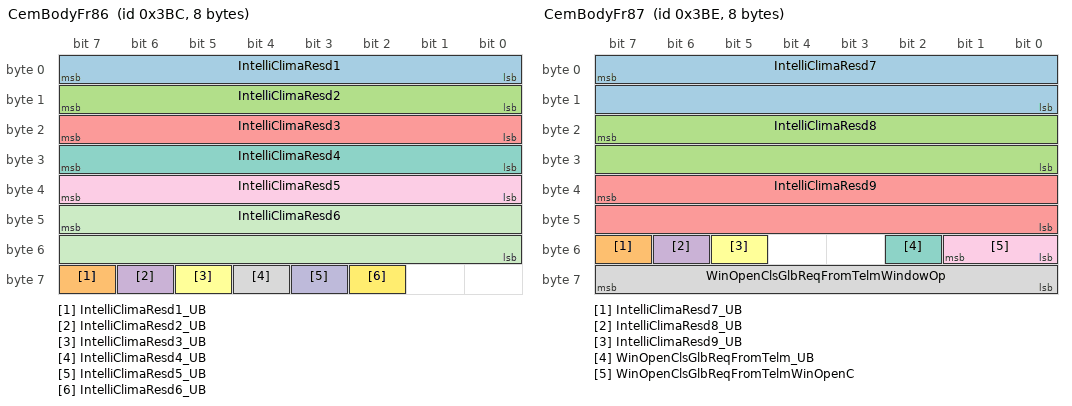
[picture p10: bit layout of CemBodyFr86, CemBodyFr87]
BO_ 956 CemBodyFr86: 8 CEM
 SG_ IntelliClimaResd1 : 7|8@0+ (1,0) [0|255] "Unitless"  CCM
 SG_ IntelliClimaResd1_UB : 63|1@0+ (1,0) [0|1] ""  CCM
 SG_ IntelliClimaResd2 : 15|8@0+ (1,0) [0|255] "Unitless"  CCM
 SG_ IntelliClimaResd2_UB : 62|1@0+ (1,0) [0|1] ""  CCM
 SG_ IntelliClimaResd3 : 23|8@0+ (1,0) [0|255] "Unitless"  CCM
 SG_ IntelliClimaResd3_UB : 61|1@0+ (1,0) [0|1] ""  CCM
 SG_ IntelliClimaResd4 : 31|8@0+ (1,0) [0|255] "Unitless"  CCM
 SG_ IntelliClimaResd4_UB : 60|1@0+ (1,0) [0|1] ""  CCM
 SG_ IntelliClimaResd5 : 39|8@0+ (1,0) [0|255] "Unitless"  CCM
 SG_ IntelliClimaResd5_UB : 59|1@0+ (1,0) [0|1] ""  CCM
 SG_ IntelliClimaResd6 : 47|16@0+ (1,0) [0|65535] "Unitless"  CCM
 SG_ IntelliClimaResd6_UB : 58|1@0+ (1,0) [0|1] ""  CCM

BO_ 958 CemBodyFr87: 8 CEM
 SG_ IntelliClimaResd7 : 7|16@0+ (1,0) [0|65535] "Unitless"  CCM
 SG_ IntelliClimaResd7_UB : 55|1@0+ (1,0) [0|1] ""  CCM
 SG_ IntelliClimaResd8 : 23|16@0+ (1,0) [0|65535] "Unitless"  CCM
 SG_ IntelliClimaResd8_UB : 54|1@0+ (1,0) [0|1] ""  CCM
 SG_ IntelliClimaResd9 : 39|16@0+ (1,0) [0|65535] "Unitless"  CCM
 SG_ IntelliClimaResd9_UB : 53|1@0+ (1,0) [0|1] ""  CCM
 SG_ WinOpenClsGlbReqFromTelm_UB : 50|1@0+ (1,0) [0|1] ""  DDM,PDM,RLDM,RRDM
 SG_ WinOpenClsGlbReqFromTelmWindowOp : 63|8@0+ (1,0) [0|100] "%"  DDM,PDM,RLDM,RRDM
 SG_ WinOpenClsGlbReqFromTelmWinOpenC : 49|2@0+ (1,0) [0|3] ""  DDM,PDM,RLDM,RRDM

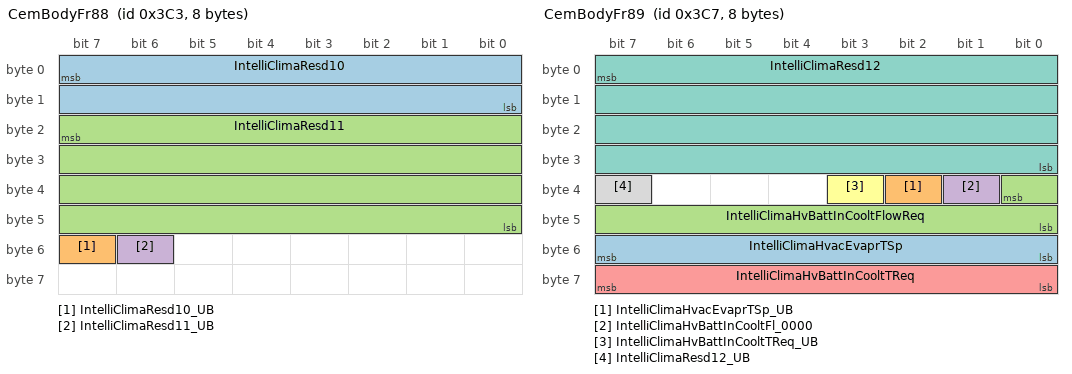
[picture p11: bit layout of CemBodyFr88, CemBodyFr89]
BO_ 963 CemBodyFr88: 8 CEM
 SG_ IntelliClimaResd10 : 7|16@0+ (1,0) [0|65535] "Unitless"  CCM
 SG_ IntelliClimaResd10_UB : 55|1@0+ (1,0) [0|1] ""  CCM
 SG_ IntelliClimaResd11 : 23|32@0+ (1,0) [0|4294967295] "Unitless"  CCM
 SG_ IntelliClimaResd11_UB : 54|1@0+ (1,0) [0|1] ""  CCM

BO_ 967 CemBodyFr89: 8 CEM
 SG_ IntelliClimaHvacEvaprTSp : 55|8@0+ (0.1,-5) [-5|20] "Unitless"  CCM
 SG_ IntelliClimaHvacEvaprTSp_UB : 34|1@0+ (1,0) [0|1] ""  CCM
 SG_ IntelliClimaHvBattInCooltFlowReq : 32|9@0+ (0.1,0) [0|51.1] "L / min"  CCM
 SG_ IntelliClimaHvBattInCooltFl_0000 : 33|1@0+ (1,0) [0|1] ""  CCM
 SG_ IntelliClimaHvBattInCooltTReq : 63|8@0+ (1,-50) [-50|200] "degC"  CCM
 SG_ IntelliClimaHvBattInCooltTReq_UB : 35|1@0+ (1,0) [0|1] ""  CCM
 SG_ IntelliClimaResd12 : 7|32@0+ (1,0) [0|4294967295] "Unitless"  CCM
 SG_ IntelliClimaResd12_UB : 39|1@0+ (1,0) [0|1] ""  CCM

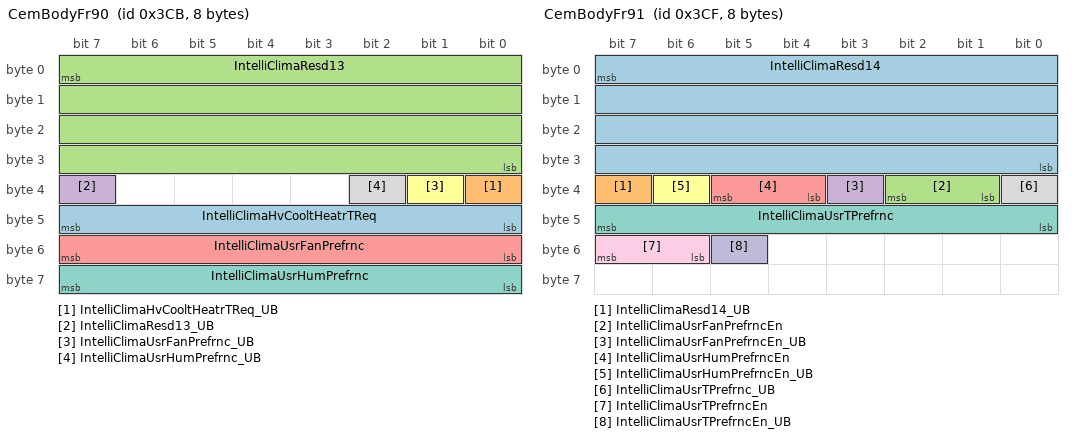
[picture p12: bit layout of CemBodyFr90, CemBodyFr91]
BO_ 971 CemBodyFr90: 8 CEM
 SG_ IntelliClimaHvCooltHeatrTReq : 47|8@0+ (1,-40) [-40|215] "degC"  CCM
 SG_ IntelliClimaHvCooltHeatrTReq_UB : 32|1@0+ (1,0) [0|1] ""  CCM
 SG_ IntelliClimaResd13 : 7|32@0+ (1,0) [0|4294967295] "Unitless"  CCM
 SG_ IntelliClimaResd13_UB : 39|1@0+ (1,0) [0|1] ""  CCM
 SG_ IntelliClimaUsrFanPrefrnc : 55|8@0+ (1,0) [0|255] "Unitless"  CCM
 SG_ IntelliClimaUsrFanPrefrnc_UB : 33|1@0+ (1,0) [0|1] ""  CCM
 SG_ IntelliClimaUsrHumPrefrnc : 63|8@0+ (1,0) [0|255] "Unitless"  CCM
 SG_ IntelliClimaUsrHumPrefrnc_UB : 34|1@0+ (1,0) [0|1] ""  CCM

BO_ 975 CemBodyFr91: 8 CEM
 SG_ IntelliClimaResd14 : 7|32@0+ (1,0) [0|4294967295] "Unitless"  CCM
 SG_ IntelliClimaResd14_UB : 39|1@0+ (1,0) [0|1] ""  CCM
 SG_ IntelliClimaUsrFanPrefrncEn : 34|2@0+ (1,0) [0|3] ""  CCM
 SG_ IntelliClimaUsrFanPrefrncEn_UB : 35|1@0+ (1,0) [0|1] ""  CCM
 SG_ IntelliClimaUsrHumPrefrncEn : 37|2@0+ (1,0) [0|3] ""  CCM
 SG_ IntelliClimaUsrHumPrefrncEn_UB : 38|1@0+ (1,0) [0|1] ""  CCM
 SG_ IntelliClimaUsrTPrefrnc : 47|8@0+ (1,0) [0|255] "Unitless"  CCM
 SG_ IntelliClimaUsrTPrefrnc_UB : 32|1@0+ (1,0) [0|1] ""  CCM
 SG_ IntelliClimaUsrTPrefrncEn : 55|2@0+ (1,0) [0|3] ""  CCM
 SG_ IntelliClimaUsrTPrefrncEn_UB : 53|1@0+ (1,0) [0|1] ""  CCM

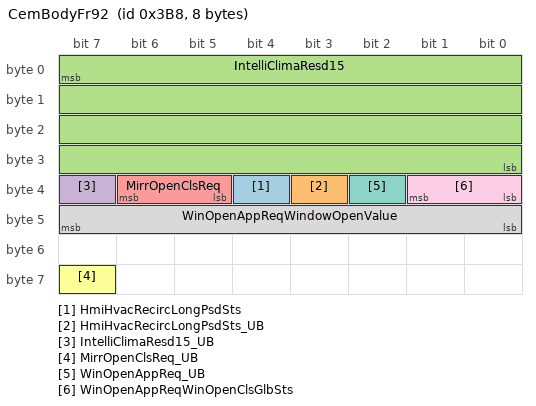
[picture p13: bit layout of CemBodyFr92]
BO_ 952 CemBodyFr92: 8 CEM
 SG_ HmiHvacRecircLongPsdSts : 36|1@0+ (1,0) [0|1] ""  CCM
 SG_ HmiHvacRecircLongPsdSts_UB : 35|1@0+ (1,0) [0|1] ""  CCM
 SG_ IntelliClimaResd15 : 7|32@0+ (1,0) [0|4294967295] "Unitless"  CCM
 SG_ IntelliClimaResd15_UB : 39|1@0+ (1,0) [0|1] ""  CCM
 SG_ MirrOpenClsReq : 38|2@0+ (1,0) [0|3] ""  DDM
 SG_ MirrOpenClsReq_UB : 63|1@0+ (1,0) [0|1] ""  DDM
 SG_ WinOpenAppReq_UB : 34|1@0+ (1,0) [0|1] ""  DDM,PDM,RLDM,RRDM
 SG_ WinOpenAppReqWindowOpenValue : 47|8@0+ (1,0) [0|100] "%"  DDM,PDM,RLDM,RRDM
 SG_ WinOpenAppReqWinOpenClsGlbSts : 33|2@0+ (1,0) [0|3] ""  DDM,PDM,RLDM,RRDM

CM_ SG_ 150 FirstRowLeDefdMassgProgCfgMassgB "to confirm if the pneumatic bags 01 is selected ";
CM_ SG_ 150 FirstRowLeDefdMassgProgCfgM_0000 "to confirm if the pneumatic bags 02 is selected ";
CM_ SG_ 150 FirstRowLeDefdMassgProgCfgM_0001 "to confirm if the pneumatic bags 03 is selected ";
CM_ SG_ 150 FirstRowLeDefdMassgProgCfgM_0002 "to confirm if the pneumatic bags 04 is selected ";
CM_ SG_ 150 FirstRowLeDefdMassgProgCfgM_0003 "to confirm if the pneumatic bags 05 is selected ";
CM_ SG_ 150 FirstRowLeDefdMassgProgCfgM_0004 "to confirm if the pneumatic bags 06 is selected ";
CM_ SG_ 150 FirstRowLeDefdMassgProgCfgM_0005 "to confirm if the pneumatic bags 07 is selected ";
CM_ SG_ 150 FirstRowLeDefdMassgProgCfgM_0006 "to confirm if the pneumatic bags 08 is selected ";
CM_ SG_ 150 FirstRowLeDefdMassgProgCfgM_0007 "to confirm if the pneumatic bags 09 is selected ";
CM_ SG_ 150 FirstRowLeDefdMassgProgCfgM_0008 "to confirm if the pneumatic bags 10 is selected ";
CM_ SG_ 150 FirstRowLeDefdMassgProgCfgM_0009 "to confirm if the pneumatic bags 11 is selected ";
CM_ SG_ 150 FirstRowLeDefdMassgProgCfgM_0010 "to confirm if the pneumatic bags 12 is selected ";
CM_ SG_ 150 FirstRowLeDefdMassgProgCfgM_0011 "to confirm if the pneumatic bags 13 is selected ";
CM_ SG_ 150 FirstRowLeDefdMassgProgCfgM_0012 "to confirm if the pneumatic bags 14 is selected ";
CM_ SG_ 150 FirstRowLeDefdMassgProgCfgM_0013 "to confirm if the pneumatic bags 15 is selected ";
CM_ SG_ 150 FirstRowLeDefdMassgProgCfgM_0014 "to confirm if the pneumatic bags 16 is selected ";
CM_ SG_ 150 FirstRowLeDefdMassgProgCfgMassgF "different levels of frequency could be selected";
CM_ SG_ 150 FirstRowLeDefdMassgProgCfgMassgI "different levels of strength could be selected";
CM_ SG_ 150 FirstRowLeDefdMassgProgCfgMassPr "to store the customized massage Program ID";
CM_ SG_ 150 FirstRowLeDefdMassgProgCfgM_0015 "used for configuring/remove/save functions";
CM_ SG_ 150 FirstRowLeDefdMassgProgCfgMassSe "to store the sequence ID in each customized massage Program";
CM_ SG_ 150 FirstRowRiDefdMassgProgCfgMassgB "to confirm if the pneumatic bags 01 is selected ";
CM_ SG_ 150 FirstRowRiDefdMassgProgCfgM_0000 "to confirm if the pneumatic bags 02 is selected ";
CM_ SG_ 150 FirstRowRiDefdMassgProgCfgM_0001 "to confirm if the pneumatic bags 03 is selected ";
CM_ SG_ 150 FirstRowRiDefdMassgProgCfgM_0002 "to confirm if the pneumatic bags 04 is selected ";
CM_ SG_ 150 FirstRowRiDefdMassgProgCfgM_0003 "to confirm if the pneumatic bags 05 is selected ";
CM_ SG_ 150 FirstRowRiDefdMassgProgCfgM_0004 "to confirm if the pneumatic bags 06 is selected ";
CM_ SG_ 150 FirstRowRiDefdMassgProgCfgM_0005 "to confirm if the pneumatic bags 07 is selected ";
CM_ SG_ 150 FirstRowRiDefdMassgProgCfgM_0006 "to confirm if the pneumatic bags 08 is selected ";
CM_ SG_ 150 FirstRowRiDefdMassgProgCfgM_0007 "to confirm if the pneumatic bags 09 is selected ";
CM_ SG_ 150 FirstRowRiDefdMassgProgCfgM_0008 "to confirm if the pneumatic bags 10 is selected ";
CM_ SG_ 150 FirstRowRiDefdMassgProgCfgM_0009 "to confirm if the pneumatic bags 11 is selected ";
CM_ SG_ 150 FirstRowRiDefdMassgProgCfgM_0010 "to confirm if the pneumatic bags 12 is selected ";
CM_ SG_ 150 FirstRowRiDefdMassgProgCfgM_0011 "to confirm if the pneumatic bags 13 is selected ";
CM_ SG_ 150 FirstRowRiDefdMassgProgCfgM_0012 "to confirm if the pneumatic bags 14 is selected ";
CM_ SG_ 150 FirstRowRiDefdMassgProgCfgM_0013 "to confirm if the pneumatic bags 15 is selected ";
CM_ SG_ 150 FirstRowRiDefdMassgProgCfgM_0014 "to confirm if the pneumatic bags 16 is selected ";
CM_ SG_ 150 FirstRowRiDefdMassgProgCfgMassgF "different levels of frequency could be selected";
CM_ SG_ 150 FirstRowRiDefdMassgProgCfgMassgI "different levels of strength could be selected";
CM_ SG_ 150 FirstRowRiDefdMassgProgCfgMassPr "to store the customized massage Program ID";
CM_ SG_ 150 FirstRowRiDefdMassgProgCfgM_0015 "used for configuring/remove/save functions";
CM_ SG_ 150 FirstRowRiDefdMassgProgCfgMassSe "to store the sequence ID in each customized massage Program";
CM_ SG_ 528 CoolgLoadGroupCoolgLimd "Reduced or limited capacity";
CM_ SG_ 528 CoolgLoadGroupCoolgLoad2 " Present cooling load";
CM_ SG_ 528 EngTEngT "Engine coolant temperature. Resolution 1 degC
";
CM_ SG_ 528 EngTQf "Engine coolant temperature quality factor.Engine coolant temperature";
CM_ SG_ 528 HvPwrEgyPrio "Information about which session is prioritized (charging, cooling, climatization etc).";
CM_ SG_ 528 MirrDefrstAtDrvrCmd "Activation signal exterior rear view mirror electrical defroster driver side.";
CM_ SG_ 528 MirrDefrstAtPassCmd "Activation signal exterior rear view mirror electrical defroster passenger side.";
CM_ SG_ 528 PassSeatSts "Occupation status of the front passenger seat.";
CM_ SG_ 528 SeatDispBtnPsdDrvrSeatDispBtnPsd "Drvr seat display button pressed";
CM_ SG_ 528 SeatDispBtnPsdPassSeatDispBtnPsd "Pass seat display button pressed";
CM_ SG_ 528 SeatOccptAtRowSecLe "Occupant seat status 2nd row, outer left seat";
CM_ SG_ 528 SeatOccptAtRowSecRi "Occupant seat status 2nd row, outer right seat";
CM_ SG_ 298 DoorsOpenerReqChks "Checksum for E2E";
CM_ SG_ 298 DoorsOpenerReqCntr "Counter for E2E";
CM_ SG_ 298 DoorsOpenerReqDrvr "Door Opener Request for Driver Door";
CM_ SG_ 298 DoorsOpenerReqLeRe "Door Opener Request for Left Rear Door";
CM_ SG_ 298 DoorsOpenerReqPass "Door Opener Request for Passenger Door";
CM_ SG_ 298 DoorsOpenerReqRiRe "Door Opener Request for Right Rear Door";
CM_ SG_ 298 DoorsOpenerReqTrigSrcDrvr "Door Opener Request trigger source for Driver door";
CM_ SG_ 298 DoorsOpenerReqTrigSrcLeRe "Door Opener Request trigger source for Left Rear door";
CM_ SG_ 298 DoorsOpenerReqTrigSrcPass "Door Opener Request trigger source for Passenger door";
CM_ SG_ 298 DoorsOpenerReqTrigSrcRiRe "Door Opener Request trigger source for Right Rear door";
CM_ SG_ 298 DoorsOpenerReqVehMtnSts "Door Opener Request Vehicle motion status (Boolean)";
CM_ SG_ 298 SecRowRiDefdMassgProgCfgMassgBag "to confirm if the pneumatic bags 01 is selected ";
CM_ SG_ 298 SecRowRiDefdMassgProgCfgMas_0000 "to confirm if the pneumatic bags 02 is selected ";
CM_ SG_ 298 SecRowRiDefdMassgProgCfgMas_0001 "to confirm if the pneumatic bags 03 is selected ";
CM_ SG_ 298 SecRowRiDefdMassgProgCfgMas_0002 "to confirm if the pneumatic bags 04 is selected ";
CM_ SG_ 298 SecRowRiDefdMassgProgCfgMas_0003 "to confirm if the pneumatic bags 05 is selected ";
CM_ SG_ 298 SecRowRiDefdMassgProgCfgMas_0004 "to confirm if the pneumatic bags 06 is selected ";
CM_ SG_ 298 SecRowRiDefdMassgProgCfgMas_0005 "to confirm if the pneumatic bags 07 is selected ";
CM_ SG_ 298 SecRowRiDefdMassgProgCfgMas_0006 "to confirm if the pneumatic bags 08 is selected ";
CM_ SG_ 298 SecRowRiDefdMassgProgCfgMas_0007 "to confirm if the pneumatic bags 09 is selected ";
CM_ SG_ 298 SecRowRiDefdMassgProgCfgMas_0008 "to confirm if the pneumatic bags 10 is selected ";
CM_ SG_ 298 SecRowRiDefdMassgProgCfgMas_0009 "to confirm if the pneumatic bags 11 is selected ";
CM_ SG_ 298 SecRowRiDefdMassgProgCfgMas_0010 "to confirm if the pneumatic bags 12 is selected ";
CM_ SG_ 298 SecRowRiDefdMassgProgCfgMas_0011 "to confirm if the pneumatic bags 13 is selected ";
CM_ SG_ 298 SecRowRiDefdMassgProgCfgMas_0012 "to confirm if the pneumatic bags 14 is selected ";
CM_ SG_ 298 SecRowRiDefdMassgProgCfgMas_0013 "to confirm if the pneumatic bags 15 is selected ";
CM_ SG_ 298 SecRowRiDefdMassgProgCfgMas_0014 "to confirm if the pneumatic bags 16 is selected ";
CM_ SG_ 298 SecRowRiDefdMassgProgCfgMassgFrq "different levels of frequency could be selected";
CM_ SG_ 298 SecRowRiDefdMassgProgCfgMassgInt "different levels of strength could be selected";
CM_ SG_ 298 SecRowRiDefdMassgProgCfgMassProg "to store the customized massage Program ID";
CM_ SG_ 298 SecRowRiDefdMassgProgCfgMas_0015 "used for configuring/remove/save functions";
CM_ SG_ 298 SecRowRiDefdMassgProgCfgMassSeqC "to store the sequence ID in each customized massage Program";
CM_ SG_ 656 CnctSrvFragChRatReqFragRatForCh1 "Connected Service (APP) requests to active fragrance channel 1 and the ratio.";
CM_ SG_ 656 CnctSrvFragChRatReqFragRatForCh2 "Connected Service (APP) requests to active fragrance channel 2 and the ratio.";
CM_ SG_ 656 CnctSrvFragChRatReqFragRatForCh3 "Connected Service (APP) requests to active fragrance channel 3 and the ratio.";
CM_ SG_ 656 CnctSrvFragChRatReqFragRatForCh4 "Connected Service (APP) requests to active fragrance channel 4 and the ratio.";
CM_ SG_ 656 CnctSrvFragChRatReqFragRatForCh5 "Connected Service (APP) requests to active fragrance channel 5 and the ratio.";
CM_ SG_ 656 CnctSrvFragLvlReq "Connected service (APP) requests fragrance level";
CM_ SG_ 768 DrvModReq "drive mode";
CM_ SG_ 768 EngNSafeEngN "Engine Speed [rpm] and Engine Speed derivative [rpm/s]";
CM_ SG_ 768 EngNSafeEngNChks "Engine Speed [rpm] and Engine Speed derivative [rpm/s]";
CM_ SG_ 768 EngNSafeEngNCntr "Engine Speed [rpm] and Engine Speed derivative [rpm/s]";
CM_ SG_ 768 EngNSafeEngNGrdt "Engine Speed [rpm] and Engine Speed derivative [rpm/s]";
CM_ SG_ 784 BkpOfDstTrvld "total traveled distance.";
CM_ SG_ 784 CamStsCamCamFrntCalNotCmpl "Camera calibration not completed";
CM_ SG_ 784 CamStsCamCamHeatrActv "This signal indicates if the windscreen heater in front of the windscreen camera is active.";
CM_ SG_ 784 CamStsCamFrntBlkd1 "Partial Camera blockage";
CM_ SG_ 784 CamStsCamFrntBlkd2 "Partial Camera blockage";
CM_ SG_ 784 CamStsCamFrntBlkd3 "Partial Camera blockage";
CM_ SG_ 784 CamStsCamFrntBlkd4 "Partial Camera blockage";
CM_ SG_ 784 CamStsCamFrntBlkd5 "Partial Camera blockage";
CM_ SG_ 784 CamStsCamFrntBlkd6 "Partial Camera blockage";
CM_ SG_ 784 CamStsCamFrntBlkd7 "Partial Camera blockage";
CM_ SG_ 784 CamStsCamFrntBlkd8 "Partial Camera blockage";
CM_ SG_ 784 CamStsCamFrntCalNotStrtd "Camera calibration not started";
CM_ SG_ 784 CamStsCamFrntFaulty "Indicate seperate error for faulty , refer to port description.";
CM_ SG_ 784 CamStsCamFrontEna "Camera enable";
CM_ SG_ 784 CamStsCamMissCom "Camera miss communication";
CM_ SG_ 784 CamStsChks "Checksum";
CM_ SG_ 784 CamStsCntr "Counter";
CM_ SG_ 464 AirTFromHeatgEstimd "Estimated air temperature from heater.";
CM_ SG_ 464 EcmRoilgCntr "Reserved roiling counter for ECM.";
CM_ SG_ 464 RoadInclnQly "Road inclination information. The road inclination is negative when the vehicle is facing uphill and positive when the vehicle is facing downhill. Quality information for road inclination";
CM_ SG_ 464 RoadInclnRoadIncln "Road inclination information. The road inclination is negative when the vehicle is facing uphill and positive when the vehicle is facing downhill.";
CM_ SG_ 464 SeatOccptAtRowSecMid "Occupant seat status 2nd row, middle seat";
CM_ SG_ 464 SunCurtPosnSts "Interface Reporting Sun Curtain Position Status.";
CM_ SG_ 464 SunRoofPosnSts "Sun roof position status";
CM_ SG_ 464 WipgInfoWipgSpdInfo "Information regarding how the wipers are run";
CM_ SG_ 464 WipgInfoWiprActv " 0 No wiping, 1 Wiping";
CM_ SG_ 464 WipgInfoWiprInWipgAr " 0 Wiper in lower reversing area or parked, 1 Wiper in wiping area";
CM_ SG_ 880 CarTiGlb "Presents a tiime value that shall be used by all ECUs to time-stamp diagnsotic trouble codes (DTC) according to the requirements for Global DTC snapshot data.";
CM_ SG_ 880 EngSt1WdStsChks "checksum";
CM_ SG_ 880 EngSt1WdStsCntr "counter";
CM_ SG_ 880 EngSt1WdStsEngSt1WdSts "Signaling the state of the powerpack";
CM_ SG_ 896 ClimaPwrAllwd "Tells how much power the climate system is allowed to consume as decided by DPLC.";
CM_ SG_ 896 DoorLeReIntrSwtLedLockgCmd "DoorLeReIntrSwtLedLockgCmd - Right Rear Door Interior Locking Switch LED command.
This is the command signal for the locking LED located in the right rear door interior locking switch. 
On - LED shall be on
Off - LED shall be off";
CM_ SG_ 896 DoorRiReIntrSwtLedLockgCmd "DoorRiReIntrSwtLedLockgCmd - Right Rear Door Interior Locking Switch LED command.
This is the command signal for the locking LED located in the right rear door interior locking switch. 
On - LED shall be on
Off - LED shall be off";
CM_ SG_ 896 IndcrPatCmd1WdTiOff "Used for Hazard Sleep (subfunction to Hazard Warning Light).

This signal holds the pattern of the flashing to use when buses are asleep and TRM/DCUs shall flash synchronized by themselves.

Holds both on and off timing in two separate record items. HWL Off time";
CM_ SG_ 896 IndcrPatCmd1WdTiOn "Used for Hazard Sleep (subfunction to Hazard Warning Light).

This signal holds the pattern of the flashing to use when buses are asleep and TRM/DCUs shall flash synchronized by themselves.

Holds both on and off timing in two separate record items. HWL On time";
CM_ SG_ 816 ProfPenSts1 "Signal communicates which profile that is active in the car
(Personal settings).";
CM_ SG_ 816 SecRowLeDefdMassgProgSeln "The selection for customized-/defaulted Massage function could be differentiated for the seat of second row left";
CM_ SG_ 816 SecRowRiDefdMassgProgSeln "The selection for customized-/defaulted Massage function could be differentiated for the seat of second row right";
CM_ SG_ 816 VehBattUSysU "Vehicle System Voltage At 12V side";
CM_ SG_ 816 VehBattUSysUQf "Present vehicle voltage measured by CEM with QF";
CM_ SG_ 832 VehCfgPrmBlkIDBytePosn1 "signal block counter.";
CM_ SG_ 832 VehCfgPrmCCPBytePosn2 " (BlockID-1)*7 + 1. ";
CM_ SG_ 832 VehCfgPrmCCPBytePosn3 " (BlockID-1)*7 + 2. ";
CM_ SG_ 832 VehCfgPrmCCPBytePosn4 " (BlockID-1)*7 + 3. ";
CM_ SG_ 832 VehCfgPrmCCPBytePosn5 " (BlockID-1)*7 + 4. ";
CM_ SG_ 832 VehCfgPrmCCPBytePosn6 " (BlockID-1)*7 + 5. ";
CM_ SG_ 832 VehCfgPrmCCPBytePosn7 " (BlockID-1)*7 + 6. ";
CM_ SG_ 832 VehCfgPrmCCPBytePosn8 " (BlockID-1)*7 + 7. ";
CM_ SG_ 306 VehCfgPrmExtBlkIDBytePosn1 "CarConfigExtended BlockID";
CM_ SG_ 306 VehCfgPrmExtCCPBytePosn2 "CarConfigExtended BytePos2";
CM_ SG_ 306 VehCfgPrmExtCCPBytePosn3 "CarConfigExtended BytePos3";
CM_ SG_ 306 VehCfgPrmExtCCPBytePosn4 "CarConfigExtended BytePos4";
CM_ SG_ 306 VehCfgPrmExtCCPBytePosn5 "CarConfigExtended BytePos5";
CM_ SG_ 306 VehCfgPrmExtCCPBytePosn6 "CarConfigExtended BytePos6";
CM_ SG_ 306 VehCfgPrmExtCCPBytePosn7 "CarConfigExtended BytePos7";
CM_ SG_ 306 VehCfgPrmExtCCPBytePosn8 "CarConfigExtended BytePos8";
CM_ SG_ 849 DrvrSeatHallPosExtDownLdSeatCush "Seat Cushion Extension Position";
CM_ SG_ 849 DrvrSeatHallPosExtDownLdSeatHead "Seat Headrest Horizontal Position";
CM_ SG_ 849 DrvrSeatHallPosExtDownLdSea_0000 "Seat Headrest Vertical Position";
CM_ SG_ 849 HmiPopUpResp "HMI received pop-up request feedback";
CM_ SG_ 849 VFCInfoEna "VFCVectorFrame enable and disable setting";
CM_ SG_ 128 AmbLiMusicShowTypAmbLiShowTyp "Select the ambient light music show mode";
CM_ SG_ 128 AmbLiMusicShowTypIdPen "Select the ambient light music show mode";
CM_ SG_ 128 AmbLiWelcomeShowTypAmbLiShowTyp "Select the ambient light welcome show mode";
CM_ SG_ 128 AmbLiWelcomeShowTypIdPen "Select the ambient light welcome show mode";
CM_ SG_ 128 VehADModeActReq "Master Lane Request from external system.";
CM_ SG_ 128 VehADModeChks "Checksum";
CM_ SG_ 128 VehADModeCntr "Counter";
CM_ SG_ 128 VehADModeReq "Vehicle AD Mode Request from external system.";
CM_ SG_ 937 PosnBriefPosnLat "Latitude";
CM_ SG_ 937 PosnBriefPosnLgt "Longitude";
CM_ SG_ 928 CmprSpdAct "Electrical compressor actual speed";
CM_ SG_ 928 HmiAutDefrstEna "HMI set to enable/disable automatic defrest demist";
CM_ SG_ 928 HmiAutDefrstReq "HMI allow to turn on/off deforest demist automatically";
CM_ SG_ 928 HmiClimaFrntAutReq "HMI request automatic air condition on/off for front row";
CM_ SG_ 928 HmiClimaReAutReq "HMI request automatic air condition on/off for second row";
CM_ SG_ 928 HmiCmptmtAirDistbnFrntLe "Interpretation: 0 - Flr - Floor 1 - Vent - Vent 2 - Defrst - Defrost 3 - FlrDefrst - Floor / defrost 4 - FlrVent - Floor / vent 5 - VentDefrst - Vent / defrost 6 - FlrVentDefrst - Floor / vent / defrost 7 - Aut - Auto ";
CM_ SG_ 928 HmiCmptmtAirDistbnFrntRi "By user requested air distribution for first row right";
CM_ SG_ 928 HmiCmptmtAirDistbnRe "By user requested air distribution for second row";
CM_ SG_ 928 HmiElecAirDirModReqDrvrMod "HMI request electric air ventilation mode for drive";
CM_ SG_ 928 HmiElecAirDirModReqPassMod "HMI request electric air ventilation mode for passenger";
CM_ SG_ 928 HmiElecAirSwngReqDrvrLeRiSwng "Driver air vent left and right swing";
CM_ SG_ 928 HmiElecAirSwngReqDrvrUpOnSwng "Driver air vent up and down swing";
CM_ SG_ 928 HmiElecAirSwngReqPassLeRiSwng "Passenger air vent left and right swing";
CM_ SG_ 928 HmiElecAirSwngReqPassUpOnSwng "Passenger air vent up and down swing";
CM_ SG_ 928 HmiFragraLvlReq "HMI request release fragrance concentration";
CM_ SG_ 928 HmiFragraModReq "HMI request fragrance release mode";
CM_ SG_ 928 HmiHumCtrlEna "HMI set to enable/disable automatic humidity control";
CM_ SG_ 928 IncomingCO2CtrlFromHmi "CO2 Monitoring function switch control";
CM_ SG_ 928 SecRowLeSeatDispMassgFctMassgInt "Massage program Intensity Level";
CM_ SG_ 928 SecRowLeSeatDispMassgFctMassgPro "Massage Programs Types";
CM_ SG_ 928 SecRowLeSeatDispMassgFctOnOff "Turn on or off seat massage";
CM_ SG_ 645 BookTrvlClimaActvReq "The request to activate air conditioning for the booking travel function with climate control";
CM_ SG_ 645 ClimaTmrStsTelmRqrd "Pre-climatization  Indicate  an active time ";
CM_ SG_ 645 IntelliClimaReq "Intelligent climate request";
CM_ SG_ 645 RemVentReq "remote cockpit ventilate request";
CM_ SG_ 645 SeatHeatDurgClimaEnadFromTelm "Request signal from Telematics to start the seat heater during a pre-climatization.";
CM_ SG_ 645 SteerWhlHeatgDurgClimaEnadFromTe "Request signal from Telematics to start the stearing wheel heater during a pre-climatization.";
CM_ SG_ 645 TelmClimaReq "remote climate start request";
CM_ SG_ 645 TelmClimaTmr "Pre-climatization activated timer from telematics.";
CM_ SG_ 645 TelmClimaTSetHmiCmptmtTSpSpcl "remote climate temperature setting status";
CM_ SG_ 645 TelmClimaTSetTempRange "remote climate temperature setting";
CM_ SG_ 645 TelmSeatPassVentnClimaLvl "remote passer seat ventilate level";
CM_ SG_ 645 TelmSeatSecLeHeatClimaLvl "remote second left seat heating level";
CM_ SG_ 645 TelmSeatSecLeVentnClimaLvl "remote second left seat ventilate level";
CM_ SG_ 645 TelmSeatSecRiHeatClimaLvl "remote second right seat heating level";
CM_ SG_ 645 TelmSeatSecRiVentnClimaLvl "remote second right seat ventilate level";
CM_ SG_ 855 ClimaRqrd1 "Request signal from Telematics to start or stop a remote pre-climatization.";
CM_ SG_ 855 HMIClimaEgySaveReq "Climate energy control active/inactive";
CM_ SG_ 855 HmiEcoClimaSetgIdPen "personal setting ID.";
CM_ SG_ 855 HmiEcoClimaSetgOnOff1 "ECO Climate setting on/off";
CM_ SG_ 855 MirrPosnFromCldAtDrvrMirrPosnAdj "Send driver side mirror positon to WindowMirrorRoofControl";
CM_ SG_ 855 MirrPosnFromCldAtDrvrMirrPo_0000 "Send driver side mirror positon to WindowMirrorRoofControl";
CM_ SG_ 855 MirrPosnFromCldAtPassMirrPosnAdj "Send passenger side mirror positon to WindowMirrorRoofControl";
CM_ SG_ 855 MirrPosnFromCldAtPassMirrPo_0000 "Send passenger side mirror positon to WindowMirrorRoofControl";
CM_ SG_ 855 ReqFragLvlTelm "remote  Fragrance lever request";
CM_ SG_ 855 TelmAirFragTasteReq "remote Fragrance channel Taste request";
CM_ SG_ 855 TelmPM25Req "remote PM2.5request";
CM_ SG_ 855 TelmSeatDrvHeatClimaLvl "remote driver seat heating level";
CM_ SG_ 855 TelmSeatDrvVentnClimaLvl "remote driver seat ventilate level";
CM_ SG_ 855 TelmSeatPassHeatClimaLvl "remote Passer seat heating level";
CM_ SG_ 944 HmiElecAirDirCrtlReqDrvrLePosX "electric air ventilation coordinate X";
CM_ SG_ 944 HmiElecAirDirCrtlReqDrvrLePosY "electric air ventilation coordinate Y";
CM_ SG_ 944 HmiElecAirDirCrtlReqDrvrRiPosX "electric air ventilation coordinate X";
CM_ SG_ 944 HmiElecAirDirCrtlReqDrvrRiPosY "electric air ventilation coordinate Ri Y";
CM_ SG_ 944 HmiElecAirDirCrtlReqPassLePosX "electric air ventilation coordinate Le X";
CM_ SG_ 944 HmiElecAirDirCrtlReqPassLePosY "electric air ventilation coordinate Le Y";
CM_ SG_ 944 HmiElecAirDirCrtlReqPassRiPosX "electric air ventilation coordinate Ri X";
CM_ SG_ 944 HmiElecAirDirCrtlReqPassRiPosY "electric air ventilation coordinate Ri Y";
CM_ SG_ 951 HmiFragraChRatReqFragRatForCh1 "HMI request release fragrance taste and ratio typeA";
CM_ SG_ 951 HmiFragraChRatReqFragRatForCh2 "HMI request release fragrance taste and ratio typeB";
CM_ SG_ 951 HmiFragraChRatReqFragRatForCh3 "HMI request release fragrance taste and ratio typeC";
CM_ SG_ 951 HmiFragraChRatReqFragRatForCh4 "HMI request release fragrance taste and ratio typeD";
CM_ SG_ 951 HmiFragraChRatReqFragRatForCh5 "HMI request release fragrance taste and ratio typeE";
CM_ SG_ 951 HmiMaxACReq "Hmi request MAX AC function on/off";
CM_ SG_ 951 HvBattClimReq "HV battery climatization activation request. Internal to ThermalManagement.";
CM_ SG_ 356 IntelliClimaActrPosnTempLeFrnt "Intelligent climate front left temperature flap position request";
CM_ SG_ 356 IntelliClimaActrPosnTempRiFrnt "Intelligent climate front right temperature flap position request";
CM_ SG_ 356 IntelliClimaCmptmtAirTEstimd "Intelligent climate estimated compartment temperature";
CM_ SG_ 356 IntelliClimaFanSpdReq "Intelligent climate fan speed request";
CM_ SG_ 356 IntelliClimaModDistbnReq "Intelligent climate air mode distribution request";
CM_ SG_ 356 IntelliClimaRecFlapPosnReq "Intelligent climate rec flap position request";
CM_ SG_ 151 BackRestSideSpprtAdjmtRowFirstDr "seat side support adjustment ";
CM_ SG_ 151 BackRestSideSpprtAdjmtRowFirstPa "seat side support adjustment ";
CM_ SG_ 151 EasyInOutSecRowLeActv "easy in out onoff";
CM_ SG_ 151 EasyInOutSecRowLeReq "easy in out onoff";
CM_ SG_ 151 EasyInOutSecRowRiActv "easy in out onoff";
CM_ SG_ 151 EasyInOutSecRowRiReq "easy in out onoff";
CM_ SG_ 151 LumHeiAdjmtRowFirstDrvr "lumbar height adjustment";
CM_ SG_ 151 LumHeiAdjmtRowFirstPass "lumbar height adjustment";
CM_ SG_ 151 LumLenAdjmtRowFirstDrvr "lumbar length adjustment";
CM_ SG_ 151 LumLenAdjmtRowFirstPass "lumbar length adjustment";
CM_ SG_ 153 CushExtnFirstDrvr "cush extend";
CM_ SG_ 153 CushExtnFirstPass "cush extend";
CM_ SG_ 153 CushSideSpprtAdjmtRowFirstDrvr "cush side support";
CM_ SG_ 153 CushSideSpprtAdjmtRowFirstPass "cush side support";
CM_ SG_ 153 HdRestAdjmtRowFirstDrvr "first row driver seat headrest forward and backward adjustment";
CM_ SG_ 153 HdRestAdjmtRowFirstPass "first row pass seat headrest forward and backward adjustment";
CM_ SG_ 153 HdRestHeiAdjmtRowFirstDrvr "first row driver seat headrest height adjustment";
CM_ SG_ 153 HdRestHeiAdjmtRowFirstPass "first row pass seat headrest height adjustment";
CM_ SG_ 153 HvahFltIndcnReq "HVAH high voltage fault indication request.";
CM_ SG_ 153 LumHeiAdjmtSecRowLe "to adjust the height of lumbar support for second row left";
CM_ SG_ 153 LumHeiAdjmtSecRowRi "to adjust the height of lumbar support for second row right";
CM_ SG_ 153 LumLenAdjmtSecRowLe "to adjust the lenght of lumbar support for second row left";
CM_ SG_ 153 LumLenAdjmtSecRowRi "to adjust the lenght of lumbar support for second row right";
CM_ SG_ 153 PassAirbSts "Passenger airbag status, based on PACOS input.";
CM_ SG_ 300 CmptmtFrntWindDewT "compartment front windsreen dew temperature value for climate control.";
CM_ SG_ 300 CmptmtFrntWindT "compartment front windscreen temperature value for climate control.";
CM_ SG_ 300 CmptmtRelHum "compartment relative humidity value for climate control.";
CM_ SG_ 300 LeReDblPullHndlMotRstCmd "The signal to control the Left Rear door double pull handle motor reset.
On - Reset request
Off - No reset request
Invalid1and2 - No release request";
CM_ SG_ 300 PwrDoorEnaHmiStsPSD "Status from CEM to PSD informing if the Power sliding doors has been disabled from HMI
Enabled, user can operate the power doors by button
Disabled, user can not operate the power doors by button";
CM_ SG_ 300 RiReDblPullHndlMotRstCmd "The signal to control the Right Rear door double pull handle motor reset.
On - Reset request
Off - No reset request
Invalid1and2 - No release request";
CM_ SG_ 300 TempPodSys "Indicates the temperature from minus 40 to 80 Celsius. Any value equal or bigger than 81, means undef
";
CM_ SG_ 447 PostDrvgClimaReq "Signal for requesting post conditioning.";
CM_ SG_ 447 RemStrtExtnTiReq "remote start high voltage extend time request";
CM_ SG_ 447 StrtInProgs "Indicating to HMI that a driver start is initiated";
CM_ SG_ 570 DCChrgnHndlSts "Fast charging gun connect state";
CM_ SG_ 570 DefrstStsMirrDefrst "Front windscreen, rear window and exterior rear view mirror electrical defroster status. Includes information regarding how they have been activated and their availability. ";
CM_ SG_ 570 DefrstStsWinDefrstFrnt "Front windscreen, rear window and exterior rear view mirror electrical defroster status. Includes information regarding how they have been activated and their availability. ";
CM_ SG_ 570 DefrstStsWinDefrstRe "Front windscreen, rear window and exterior rear view mirror electrical defroster status. Includes information regarding how they have been activated and their availability. ";
CM_ SG_ 570 IsgMotT "Temperature of the CISG";
CM_ SG_ 570 ReEvapVlvReq "Request to open shut off valve of rear evaporator.";
CM_ SG_ 570 WiprFrntSrvModReq "To make it possible to change the wiper blades there shall be a command for the wiper motor to park the wipers in service position. ";
CM_ SG_ 178 BootFoldSwtActv2 "On the CSD, customer can set up the switch on the luggage panel can/can not activated seatback fold.";
CM_ SG_ 178 BootFoldSwtActv3 "On the CSD, customer can set up the switch on the luggage panel can/can not activated seatback fold.";
CM_ SG_ 178 ClimaRqrdFromHmi "Pre-Climatisation request from HMI.";
CM_ SG_ 178 LVPwrSplyErrSts "Low voltage power supply error status";
CM_ SG_ 178 SecRowLeCmftSet "One-key seat comfort or recover position adjustment control for Second row left customer.";
CM_ SG_ 178 TiDrvgCycOff "Timer since engine was deactivated";
CM_ SG_ 178 WinOpenDrvrReq "driver window open";
CM_ SG_ 178 WinOpenPassReq "passenger window open";
CM_ SG_ 178 WinOpenReLeReq "rear window left open";
CM_ SG_ 178 WinOpenReRiReq "rear window right open";
CM_ SG_ 178 WinVentnOpenReq "Set window ventilat function onoff";
CM_ SG_ 196 DoorOpenwarnLeIndcn "Indicates if a left door open,warning shall be shown to the driver or not.
If the left door open (FL door open or  RL door open or FL and RL both open), the warning signal will send out.";
CM_ SG_ 196 DoorOpenwarnRiIndcn "Indicates if a right door open, warning shall be shown to the driver or not.
If the right door open( FR door open or  RR door open or FR and RR both open), the warning signal will send out.";
CM_ SG_ 196 LoadAndStoreReqErgoPosn "EgroPosn is memory position signal,contain MemPosn.Profposn, MemPosn.MemBnk1
MemPosn.MemBnk2,MemPosn.MemBnk3,
MemPosn.Profposn is for the Easy egress/ ingress function,Profposn means the last position,
MemPosn.MemBnk1 MemPosn.MemBnk2,MemPosn.MemBnk3 are for the memory position function,represent memory position 1 2 3
";
CM_ SG_ 196 LoadAndStoreReqErgoSetgEve "ErgoSetgEve is contains five command signal, EveMemPosn.Idle,EveMemPosn.Store,EveMemPosn.Load, EveMemPosn.Stop, EveMemPosn.AutMovmt";
CM_ SG_ 196 LoadAndStoreReqIdPen "IdPen represents Id information, contains 13 IDs, 14 is reserved.";
CM_ SG_ 196 LoadAndStoreReqInOutEasy "InOutEasy is a switch signal for t is for the Easy egress/ ingress function.";
CM_ SG_ 196 PwrAvlDelta "Avalable delta power";
CM_ SG_ 196 RctaIndcnLe "RCTA left warning signal";
CM_ SG_ 196 RctaIndcnRi "RCTA right warning signal";
CM_ SG_ 196 VehWinSunRoofClsReq "Request close the vehicle windows and sunroof.";
CM_ SG_ 257 HvBattSoc "Actual state of charge of the Hv Battery.";
CM_ SG_ 257 TrlrLampChkAutReqPen "Personal setting";
CM_ SG_ 257 TrlrLampChkAutReqSts "status containing information about if a trailer is connected to the vehicle or not";
CM_ SG_ 853 ActvnOfWshrFrntSafe "Activate front washer";
CM_ SG_ 853 StrtRemSts1WdStrtRemSts "Status signal for EngineRemoteStart send to climate for control of climatization.";
CM_ SG_ 152 CbnOverHeatProtnEnaFromTelm "Users activate or inactivate the cabin overheat protection function through mobile app";
CM_ SG_ 152 DrvrDesDirChks "Desired Driver Direction is an interpretation of driver input. It specifies in which longitudinal direction the driver requests that any accelerating propulsive torque shall be delivered. There are three possible directions: 1. Forward 2. Reverse 3. Neutral. Checksum";
CM_ SG_ 152 DrvrDesDirCntr "Desired Driver Direction is an interpretation of driver input. It specifies in which longitudinal direction the driver requests that any accelerating propulsive torque shall be delivered. There are three possible directions: 1. Forward 2. Reverse 3. Neutral. Counter";
CM_ SG_ 152 DrvrDesDirDrvrDesDir "Desired Driver Direction is an interpretation of driver input. It specifies in which longitudinal direction the driver requests that any accelerating propulsive torque shall be delivered. There are three possible directions: 1. Forward 2. Reverse 3. Neutral";
CM_ SG_ 152 HvEgyCnsAllwdForClima "How much available energy is available for compartment climatisation. Estimated available energy from wall socket or Hv battery.";
CM_ SG_ 152 OnBdChrgrSt "The charging state of OBC";
CM_ SG_ 152 PassSceneModSeld "Passenger Scenario mode setting, for example rest mdoe etc.";
CM_ SG_ 152 SecRowLeSceneModSeld "Second Row Left Scene mode setting";
CM_ SG_ 152 SecRowRiSceneModSeld "Second Row Right Scene mode setting";
CM_ SG_ 152 SpeechSts "The status of speech assistance";
CM_ SG_ 152 TrRelsReq "TrRelsReq - Tailgate or Bootlid Release Request

Request to release the tailgate or bootlid.

On  Release request
Off  No release request
Invalid1and2  No release request";
CM_ SG_ 309 BackRestAdjmtRowFirstDrvr "the backrest adjustment of the first row driver seat";
CM_ SG_ 309 BackRestAdjmtRowFirstPass "the backrest adjustment of the first row passanger seat";
CM_ SG_ 309 ClimaBoostAutSetColdAutoOnOff "Cold Auto Setting On/Off";
CM_ SG_ 309 ClimaBoostAutSetColdDeltaTemp "Delta Temperature in Degcgrd for Cold Boost";
CM_ SG_ 309 ClimaBoostAutSetDurOfFunction "Duration of Function";
CM_ SG_ 309 ClimaBoostAutSetHotAutoOnOff "Hot Auto Setting On/Off";
CM_ SG_ 309 ClimaBoostAutSetHotDeltaTemp "Delta Temperature in Degcgrd for Hot Boost";
CM_ SG_ 309 ClimaRefreshAutSetActvtOnExit "Auto Activation setting ON EXIT";
CM_ SG_ 309 ClimaRefreshAutSetAutoOnOff "Auto Activation setting. (On approach, Door open, Keyfob unlock)";
CM_ SG_ 309 ClimaRefreshAutSetDurOfFunction "Duration of function";
CM_ SG_ 309 ClimaRefreshCmd "Direct start command from HMI";
CM_ SG_ 309 ClimateBoostCmd "Climate Start Command from HMI";
CM_ SG_ 309 EmgyBrkLiIndcrTurn "Activation of both rear direction indicators for EBL.";
CM_ SG_ 309 SeatCushTiltAdjmtRowFirstDrvr "front row seat cushion tilt left adjustment";
CM_ SG_ 309 SeatCushTiltAdjmtRowFirstPass "front row seat cushion tilt left adjustment";
CM_ SG_ 309 SeatHeiAdjmtRowFirstDrvr "seat height adjustment ";
CM_ SG_ 309 SeatHeiAdjmtRowFirstPass "seat height adjustment ";
CM_ SG_ 309 SeatLenAdjmtRowFirstDrvr "seat Length adjustment ";
CM_ SG_ 309 SeatLenAdjmtRowFirstPass "seat Length adjustment ";
CM_ SG_ 180 ActvnOfHndlDoorLiHndlDoorLiDrvr "Controls all door handles exterior lighting on and off. Driver door handle light";
CM_ SG_ 180 ActvnOfHndlDoorLiHndlDoorLiDrvrR "Controls all door handles exterior lighting on and off. Rear driver door handle light";
CM_ SG_ 180 ActvnOfHndlDoorLiHndlDoorLiPass "Controls all door handles exterior lighting on and off. Passenger door handle light";
CM_ SG_ 180 ActvnOfHndlDoorLiHndlDoorLiPassR "Controls all door handles exterior lighting on and off. Rear passenger door handle light";
CM_ SG_ 180 ActvnOfRoofSwtIllmn "Activates or deactivates the switch illumination of the OHx.";
CM_ SG_ 180 MobDevVentReq "Ventilation Request by Mobile Device";
CM_ SG_ 180 SceneModSeld "selected scene mode ";
CM_ SG_ 1045 ResrvdSigForCCM1 "Reserved signal 1 for CCM.";
CM_ SG_ 1045 ResrvdSigForCCM2 "Reserved signal 2 for CCM.";
CM_ SG_ 1045 ResrvdSigForCCM3 "Reserved signal 3 for CCM.";
CM_ SG_ 1045 ResrvdSigForCCM4 "Reserved signal 4 for CCM.";
CM_ SG_ 468 ActiveZoneIinfoZone1ONOff "Zone 1 On or OFF";
CM_ SG_ 468 ActiveZoneIinfoZone2ONOff "Zone2 On or OFF";
CM_ SG_ 468 ActiveZoneIinfoZone3ONOff "Zone3 On or OFF";
CM_ SG_ 468 CrashStsSafeChks "Checksum for E2E";
CM_ SG_ 468 CrashStsSafeCntr "Counter for E2E";
CM_ SG_ 468 CrashStsSafeSts "Information if a crash has been detected by SRS.";
CM_ SG_ 468 DrvrSeatDispMassgFctMassgInten "Massage program Intensity Level";
CM_ SG_ 468 DrvrSeatDispMassgFctMassgProg "Massage Programs Types";
CM_ SG_ 468 DrvrSeatDispMassgFctOnOff "Turn on or off seat massage";
CM_ SG_ 468 DrvrSeatDispSpplFct "Handles the two way communication for driver multi seat control.";
CM_ SG_ 468 PassSeatDispMassgFctMassgInten "Massage program Intensity Level";
CM_ SG_ 468 PassSeatDispMassgFctMassgProg "Massage Programs Types";
CM_ SG_ 468 PassSeatDispMassgFctOnOff "Turn on or off seat massage";
CM_ SG_ 468 PassSeatDispSpplFct "Handles the two way communication for passenger multi seat control.";
CM_ SG_ 468 RemStrtHvCtrlReqErsCmd "remote start high voltage control request";
CM_ SG_ 468 RemStrtHvCtrlReqErsRunTime "remote start high voltage control time";
CM_ SG_ 956 IntelliClimaResd1 "Intelligent climate request reserved signal";
CM_ SG_ 956 IntelliClimaResd2 "Intelligent climate request reserved signal";
CM_ SG_ 956 IntelliClimaResd3 "Intelligent climate request reserved signal";
CM_ SG_ 956 IntelliClimaResd4 "Intelligent climate request reserved signal";
CM_ SG_ 956 IntelliClimaResd5 "Intelligent climate request reserved signal";
CM_ SG_ 956 IntelliClimaResd6 "Intelligent climate request reserved signal";
CM_ SG_ 958 IntelliClimaResd7 "Intelligent climate request reserved signal";
CM_ SG_ 958 IntelliClimaResd8 "Intelligent climate request reserved signal";
CM_ SG_ 958 IntelliClimaResd9 "Intelligent climate request reserved signal";
CM_ SG_ 958 WinOpenClsGlbReqFromTelmWindowOp "Windows open value pec open 1-100";
CM_ SG_ 958 WinOpenClsGlbReqFromTelmWinOpenC "remote global windows open and closed command request from telematics";
CM_ SG_ 963 IntelliClimaResd10 "Intelligent climate request reserved signal";
CM_ SG_ 963 IntelliClimaResd11 "Intelligent climate request reserved signal";
CM_ SG_ 967 IntelliClimaHvacEvaprTSp "Intelligent climate target evaporator temperature";
CM_ SG_ 967 IntelliClimaHvBattInCooltFlowReq "Intelligent climate HV battery target inlet coolant flow";
CM_ SG_ 967 IntelliClimaHvBattInCooltTReq "Intelligent climate HV battery target inlet coolant temperature";
CM_ SG_ 967 IntelliClimaResd12 "Intelligent climate request reserved signal";
CM_ SG_ 971 IntelliClimaHvCooltHeatrTReq "Intelligent climate HV coolant heater temperature request";
CM_ SG_ 971 IntelliClimaResd13 "Intelligent climate request reserved signal";
CM_ SG_ 971 IntelliClimaUsrFanPrefrnc "Intelligent climate user s blower flow preference request";
CM_ SG_ 971 IntelliClimaUsrHumPrefrnc "Intelligent climate user s humidity preference request";
CM_ SG_ 975 IntelliClimaResd14 "Intelligent climate request reserved signal";
CM_ SG_ 975 IntelliClimaUsrFanPrefrncEn "Intelligent climate user s humidity preference enable";
CM_ SG_ 975 IntelliClimaUsrHumPrefrncEn "Intelligent climate user s humidity preference enable";
CM_ SG_ 975 IntelliClimaUsrTPrefrnc "Intelligent climate user s temperature preference request";
CM_ SG_ 975 IntelliClimaUsrTPrefrncEn "Intelligent climate user s temperature preference enable";
CM_ SG_ 952 HmiHvacRecircLongPsdSts "Hmi send Recirculation long Pressed status";
CM_ SG_ 952 IntelliClimaResd15 "Intelligent climate request reserved signal";
CM_ SG_ 952 MirrOpenClsReq "Send request to DCU to fold/unfold outside mirror.";
CM_ SG_ 952 WinOpenAppReqWindowOpenValue "Windows open value pec open 1-100";
CM_ SG_ 952 WinOpenAppReqWinOpenClsGlbSts "Remote global windows open and closed command request from Connected Service Sub-system";
BA_DEF_ BO_  "GenMsgSendType" ENUM  "cyclic","spontaneous","not-used","not-used","not-used","cyclicAndSpontaneous","not-used","cyclicIfActive","NoMsgSendType";
BA_DEF_ BO_  "GenMsgCycleTime" INT 0 65536;
BA_DEF_ BO_  "GenMsgStartDelayTime" INT 0 65536;
BA_DEF_ BO_  "GenMsgDelayTime" INT 0 65536;
BA_DEF_ SG_  "GenSigSendType" ENUM  "Cyclic","OnWrite","OnWriteWithRepetition","OnChange","OnChangeWithRepetition","IfActive","IfActiveWithRepetition","NoSigSendType";
BA_DEF_ SG_  "GenSigStartValue" HEX 0 80000000;
BA_DEF_ BO_  "GenMsgILSupport" ENUM  "No","Yes";
BA_DEF_ BO_  "NmAsrMessage" ENUM  "No","Yes";
BA_DEF_ SG_  "GenSigFuncType" ENUM  "NoFunction","n/a","n/a","n/a","n/a","n/a","n/a","n/a","n/a","n/a","n/a","n/a","n/a","n/a","n/a","CHK","CNTR","n/a","n/a","n/a","CNTR_AR_01","CRC_AR_01_BOTH","CRC_AR_01_ALT","CRC_AR_01_LOW","CRC_AR_01_NIBBLE","CNTR_AR_04","CRC_AR_04A","CNTR_AR_05","CRC_AR_05";
BA_DEF_ SG_  "GenSigDataID" STRING ;
BA_DEF_ SG_  "SystemSignalLongSymbol" STRING ;
BA_DEF_DEF_  "GenMsgSendType" "NoMsgSendType";
BA_DEF_DEF_  "GenMsgCycleTime" 0;
BA_DEF_DEF_  "GenMsgStartDelayTime" 0;
BA_DEF_DEF_  "GenMsgDelayTime" 0;
BA_DEF_DEF_  "GenSigSendType" "NoSigSendType";
BA_DEF_DEF_  "GenSigStartValue" 0;
BA_DEF_DEF_  "GenMsgILSupport" "Yes";
BA_DEF_DEF_  "NmAsrMessage" "No";
BA_DEF_DEF_  "GenSigFuncType" "NoFunction";
BA_DEF_DEF_  "GenSigDataID" "";
BA_DEF_DEF_  "SystemSignalLongSymbol" "";
BA_ "GenMsgSendType" BO_ 150 0;
BA_ "GenMsgCycleTime" BO_ 150 40;
BA_ "GenMsgSendType" BO_ 528 0;
BA_ "GenMsgCycleTime" BO_ 528 390;
BA_ "GenMsgSendType" BO_ 298 0;
BA_ "GenMsgCycleTime" BO_ 298 80;
BA_ "GenMsgSendType" BO_ 656 1;
BA_ "GenMsgDelayTime" BO_ 656 250;
BA_ "GenMsgSendType" BO_ 768 0;
BA_ "GenMsgCycleTime" BO_ 768 210;
BA_ "GenMsgSendType" BO_ 784 0;
BA_ "GenMsgCycleTime" BO_ 784 175;
BA_ "GenMsgSendType" BO_ 464 0;
BA_ "GenMsgCycleTime" BO_ 464 400;
BA_ "GenMsgSendType" BO_ 880 0;
BA_ "GenMsgCycleTime" BO_ 880 620;
BA_ "GenMsgSendType" BO_ 896 0;
BA_ "GenMsgCycleTime" BO_ 896 45;
BA_ "GenMsgSendType" BO_ 816 0;
BA_ "GenMsgCycleTime" BO_ 816 215;
BA_ "GenMsgSendType" BO_ 832 1;
BA_ "GenMsgDelayTime" BO_ 832 120;
BA_ "GenMsgSendType" BO_ 306 1;
BA_ "GenMsgDelayTime" BO_ 306 120;
BA_ "GenMsgSendType" BO_ 849 1;
BA_ "GenMsgDelayTime" BO_ 849 190;
BA_ "GenMsgSendType" BO_ 128 0;
BA_ "GenMsgCycleTime" BO_ 128 20;
BA_ "GenMsgSendType" BO_ 937 0;
BA_ "GenMsgCycleTime" BO_ 937 1300;
BA_ "GenMsgSendType" BO_ 928 0;
BA_ "GenMsgCycleTime" BO_ 928 175;
BA_ "GenMsgSendType" BO_ 645 1;
BA_ "GenMsgDelayTime" BO_ 645 100;
BA_ "GenMsgSendType" BO_ 855 1;
BA_ "GenMsgDelayTime" BO_ 855 60;
BA_ "GenMsgSendType" BO_ 944 0;
BA_ "GenMsgCycleTime" BO_ 944 180;
BA_ "GenMsgSendType" BO_ 951 0;
BA_ "GenMsgCycleTime" BO_ 951 140;
BA_ "GenMsgSendType" BO_ 356 1;
BA_ "GenMsgDelayTime" BO_ 356 100;
BA_ "GenMsgSendType" BO_ 151 0;
BA_ "GenMsgCycleTime" BO_ 151 300;
BA_ "GenMsgSendType" BO_ 153 0;
BA_ "GenMsgCycleTime" BO_ 153 300;
BA_ "GenMsgSendType" BO_ 300 0;
BA_ "GenMsgCycleTime" BO_ 300 80;
BA_ "GenMsgSendType" BO_ 447 0;
BA_ "GenMsgCycleTime" BO_ 447 125;
BA_ "GenMsgSendType" BO_ 570 0;
BA_ "GenMsgCycleTime" BO_ 570 300;
BA_ "GenMsgSendType" BO_ 178 0;
BA_ "GenMsgCycleTime" BO_ 178 40;
BA_ "GenMsgSendType" BO_ 196 0;
BA_ "GenMsgCycleTime" BO_ 196 20;
BA_ "GenMsgSendType" BO_ 257 0;
BA_ "GenMsgCycleTime" BO_ 257 100;
BA_ "GenMsgSendType" BO_ 853 0;
BA_ "GenMsgCycleTime" BO_ 853 300;
BA_ "GenMsgSendType" BO_ 152 0;
BA_ "GenMsgCycleTime" BO_ 152 65;
BA_ "GenMsgSendType" BO_ 309 0;
BA_ "GenMsgCycleTime" BO_ 309 70;
BA_ "GenMsgSendType" BO_ 180 0;
BA_ "GenMsgCycleTime" BO_ 180 50;
BA_ "GenMsgSendType" BO_ 1045 0;
BA_ "GenMsgCycleTime" BO_ 1045 600;
BA_ "GenMsgSendType" BO_ 468 0;
BA_ "GenMsgCycleTime" BO_ 468 150;
BA_ "GenMsgSendType" BO_ 956 1;
BA_ "GenMsgDelayTime" BO_ 956 100;
BA_ "GenMsgSendType" BO_ 958 1;
BA_ "GenMsgDelayTime" BO_ 958 175;
BA_ "GenMsgSendType" BO_ 963 1;
BA_ "GenMsgDelayTime" BO_ 963 175;
BA_ "GenMsgSendType" BO_ 967 1;
BA_ "GenMsgDelayTime" BO_ 967 100;
BA_ "GenMsgSendType" BO_ 971 1;
BA_ "GenMsgDelayTime" BO_ 971 100;
BA_ "GenMsgSendType" BO_ 975 1;
BA_ "GenMsgDelayTime" BO_ 975 175;
BA_ "GenMsgSendType" BO_ 952 1;
BA_ "GenMsgDelayTime" BO_ 952 15;
BA_ "GenSigSendType" SG_ 150 FirstRowLeDefdMassgProgCfgMassgB 0;
BA_ "SystemSignalLongSymbol" SG_ 150 FirstRowLeDefdMassgProgCfgMassgB "FirstRowLeDefdMassgProgCfgMassgBag01Select";
BA_ "GenSigSendType" SG_ 150 FirstRowLeDefdMassgProgCfgM_0000 0;
BA_ "SystemSignalLongSymbol" SG_ 150 FirstRowLeDefdMassgProgCfgM_0000 "FirstRowLeDefdMassgProgCfgMassgBag02Select";
BA_ "GenSigSendType" SG_ 150 FirstRowLeDefdMassgProgCfgM_0001 0;
BA_ "SystemSignalLongSymbol" SG_ 150 FirstRowLeDefdMassgProgCfgM_0001 "FirstRowLeDefdMassgProgCfgMassgBag03Select";
BA_ "GenSigSendType" SG_ 150 FirstRowLeDefdMassgProgCfgM_0002 0;
BA_ "SystemSignalLongSymbol" SG_ 150 FirstRowLeDefdMassgProgCfgM_0002 "FirstRowLeDefdMassgProgCfgMassgBag04Select";
BA_ "GenSigSendType" SG_ 150 FirstRowLeDefdMassgProgCfgM_0003 0;
BA_ "SystemSignalLongSymbol" SG_ 150 FirstRowLeDefdMassgProgCfgM_0003 "FirstRowLeDefdMassgProgCfgMassgBag05Select";
BA_ "GenSigSendType" SG_ 150 FirstRowLeDefdMassgProgCfgM_0004 0;
BA_ "SystemSignalLongSymbol" SG_ 150 FirstRowLeDefdMassgProgCfgM_0004 "FirstRowLeDefdMassgProgCfgMassgBag06Select";
BA_ "GenSigSendType" SG_ 150 FirstRowLeDefdMassgProgCfgM_0005 0;
BA_ "SystemSignalLongSymbol" SG_ 150 FirstRowLeDefdMassgProgCfgM_0005 "FirstRowLeDefdMassgProgCfgMassgBag07Select";
BA_ "GenSigSendType" SG_ 150 FirstRowLeDefdMassgProgCfgM_0006 0;
BA_ "SystemSignalLongSymbol" SG_ 150 FirstRowLeDefdMassgProgCfgM_0006 "FirstRowLeDefdMassgProgCfgMassgBag08Select";
BA_ "GenSigSendType" SG_ 150 FirstRowLeDefdMassgProgCfgM_0007 0;
BA_ "SystemSignalLongSymbol" SG_ 150 FirstRowLeDefdMassgProgCfgM_0007 "FirstRowLeDefdMassgProgCfgMassgBag09Select";
BA_ "GenSigSendType" SG_ 150 FirstRowLeDefdMassgProgCfgM_0008 0;
BA_ "SystemSignalLongSymbol" SG_ 150 FirstRowLeDefdMassgProgCfgM_0008 "FirstRowLeDefdMassgProgCfgMassgBag10Select";
BA_ "GenSigSendType" SG_ 150 FirstRowLeDefdMassgProgCfgM_0009 0;
BA_ "SystemSignalLongSymbol" SG_ 150 FirstRowLeDefdMassgProgCfgM_0009 "FirstRowLeDefdMassgProgCfgMassgBag11Select";
BA_ "GenSigSendType" SG_ 150 FirstRowLeDefdMassgProgCfgM_0010 0;
BA_ "SystemSignalLongSymbol" SG_ 150 FirstRowLeDefdMassgProgCfgM_0010 "FirstRowLeDefdMassgProgCfgMassgBag12Select";
BA_ "GenSigSendType" SG_ 150 FirstRowLeDefdMassgProgCfgM_0011 0;
BA_ "SystemSignalLongSymbol" SG_ 150 FirstRowLeDefdMassgProgCfgM_0011 "FirstRowLeDefdMassgProgCfgMassgBag13Select";
BA_ "GenSigSendType" SG_ 150 FirstRowLeDefdMassgProgCfgM_0012 0;
BA_ "SystemSignalLongSymbol" SG_ 150 FirstRowLeDefdMassgProgCfgM_0012 "FirstRowLeDefdMassgProgCfgMassgBag14Select";
BA_ "GenSigSendType" SG_ 150 FirstRowLeDefdMassgProgCfgM_0013 0;
BA_ "SystemSignalLongSymbol" SG_ 150 FirstRowLeDefdMassgProgCfgM_0013 "FirstRowLeDefdMassgProgCfgMassgBag15Select";
BA_ "GenSigSendType" SG_ 150 FirstRowLeDefdMassgProgCfgM_0014 0;
BA_ "SystemSignalLongSymbol" SG_ 150 FirstRowLeDefdMassgProgCfgM_0014 "FirstRowLeDefdMassgProgCfgMassgBag16Select";
BA_ "GenSigSendType" SG_ 150 FirstRowLeDefdMassgProgCfgMassgF 0;
BA_ "SystemSignalLongSymbol" SG_ 150 FirstRowLeDefdMassgProgCfgMassgF "FirstRowLeDefdMassgProgCfgMassgFrqSelect";
BA_ "GenSigSendType" SG_ 150 FirstRowLeDefdMassgProgCfgMassgI 0;
BA_ "SystemSignalLongSymbol" SG_ 150 FirstRowLeDefdMassgProgCfgMassgI "FirstRowLeDefdMassgProgCfgMassgIntenSelect";
BA_ "GenSigStartValue" SG_ 150 FirstRowLeDefdMassgProgCfgMassPr 1;
BA_ "GenSigSendType" SG_ 150 FirstRowLeDefdMassgProgCfgMassPr 0;
BA_ "SystemSignalLongSymbol" SG_ 150 FirstRowLeDefdMassgProgCfgMassPr "FirstRowLeDefdMassgProgCfgMassProgCntr";
BA_ "GenSigSendType" SG_ 150 FirstRowLeDefdMassgProgCfgM_0015 0;
BA_ "SystemSignalLongSymbol" SG_ 150 FirstRowLeDefdMassgProgCfgM_0015 "FirstRowLeDefdMassgProgCfgMassProgEdit";
BA_ "GenSigStartValue" SG_ 150 FirstRowLeDefdMassgProgCfgMassSe 1;
BA_ "GenSigSendType" SG_ 150 FirstRowLeDefdMassgProgCfgMassSe 0;
BA_ "SystemSignalLongSymbol" SG_ 150 FirstRowLeDefdMassgProgCfgMassSe "FirstRowLeDefdMassgProgCfgMassSeqCntr";
BA_ "GenSigSendType" SG_ 150 FirstRowRiDefdMassgProgCfgMassgB 0;
BA_ "SystemSignalLongSymbol" SG_ 150 FirstRowRiDefdMassgProgCfgMassgB "FirstRowRiDefdMassgProgCfgMassgBag01Select";
BA_ "GenSigSendType" SG_ 150 FirstRowRiDefdMassgProgCfgM_0000 0;
BA_ "SystemSignalLongSymbol" SG_ 150 FirstRowRiDefdMassgProgCfgM_0000 "FirstRowRiDefdMassgProgCfgMassgBag02Select";
BA_ "GenSigSendType" SG_ 150 FirstRowRiDefdMassgProgCfgM_0001 0;
BA_ "SystemSignalLongSymbol" SG_ 150 FirstRowRiDefdMassgProgCfgM_0001 "FirstRowRiDefdMassgProgCfgMassgBag03Select";
BA_ "GenSigSendType" SG_ 150 FirstRowRiDefdMassgProgCfgM_0002 0;
BA_ "SystemSignalLongSymbol" SG_ 150 FirstRowRiDefdMassgProgCfgM_0002 "FirstRowRiDefdMassgProgCfgMassgBag04Select";
BA_ "GenSigSendType" SG_ 150 FirstRowRiDefdMassgProgCfgM_0003 0;
BA_ "SystemSignalLongSymbol" SG_ 150 FirstRowRiDefdMassgProgCfgM_0003 "FirstRowRiDefdMassgProgCfgMassgBag05Select";
BA_ "GenSigSendType" SG_ 150 FirstRowRiDefdMassgProgCfgM_0004 0;
BA_ "SystemSignalLongSymbol" SG_ 150 FirstRowRiDefdMassgProgCfgM_0004 "FirstRowRiDefdMassgProgCfgMassgBag06Select";
BA_ "GenSigSendType" SG_ 150 FirstRowRiDefdMassgProgCfgM_0005 0;
BA_ "SystemSignalLongSymbol" SG_ 150 FirstRowRiDefdMassgProgCfgM_0005 "FirstRowRiDefdMassgProgCfgMassgBag07Select";
BA_ "GenSigSendType" SG_ 150 FirstRowRiDefdMassgProgCfgM_0006 0;
BA_ "SystemSignalLongSymbol" SG_ 150 FirstRowRiDefdMassgProgCfgM_0006 "FirstRowRiDefdMassgProgCfgMassgBag08Select";
BA_ "GenSigSendType" SG_ 150 FirstRowRiDefdMassgProgCfgM_0007 0;
BA_ "SystemSignalLongSymbol" SG_ 150 FirstRowRiDefdMassgProgCfgM_0007 "FirstRowRiDefdMassgProgCfgMassgBag09Select";
BA_ "GenSigSendType" SG_ 150 FirstRowRiDefdMassgProgCfgM_0008 0;
BA_ "SystemSignalLongSymbol" SG_ 150 FirstRowRiDefdMassgProgCfgM_0008 "FirstRowRiDefdMassgProgCfgMassgBag10Select";
BA_ "GenSigSendType" SG_ 150 FirstRowRiDefdMassgProgCfgM_0009 0;
BA_ "SystemSignalLongSymbol" SG_ 150 FirstRowRiDefdMassgProgCfgM_0009 "FirstRowRiDefdMassgProgCfgMassgBag11Select";
BA_ "GenSigSendType" SG_ 150 FirstRowRiDefdMassgProgCfgM_0010 0;
BA_ "SystemSignalLongSymbol" SG_ 150 FirstRowRiDefdMassgProgCfgM_0010 "FirstRowRiDefdMassgProgCfgMassgBag12Select";
BA_ "GenSigSendType" SG_ 150 FirstRowRiDefdMassgProgCfgM_0011 0;
BA_ "SystemSignalLongSymbol" SG_ 150 FirstRowRiDefdMassgProgCfgM_0011 "FirstRowRiDefdMassgProgCfgMassgBag13Select";
BA_ "GenSigSendType" SG_ 150 FirstRowRiDefdMassgProgCfgM_0012 0;
BA_ "SystemSignalLongSymbol" SG_ 150 FirstRowRiDefdMassgProgCfgM_0012 "FirstRowRiDefdMassgProgCfgMassgBag14Select";
BA_ "GenSigSendType" SG_ 150 FirstRowRiDefdMassgProgCfgM_0013 0;
BA_ "SystemSignalLongSymbol" SG_ 150 FirstRowRiDefdMassgProgCfgM_0013 "FirstRowRiDefdMassgProgCfgMassgBag15Select";
BA_ "GenSigSendType" SG_ 150 FirstRowRiDefdMassgProgCfgM_0014 0;
BA_ "SystemSignalLongSymbol" SG_ 150 FirstRowRiDefdMassgProgCfgM_0014 "FirstRowRiDefdMassgProgCfgMassgBag16Select";
BA_ "GenSigSendType" SG_ 150 FirstRowRiDefdMassgProgCfgMassgF 0;
BA_ "SystemSignalLongSymbol" SG_ 150 FirstRowRiDefdMassgProgCfgMassgF "FirstRowRiDefdMassgProgCfgMassgFrqSelect";
BA_ "GenSigSendType" SG_ 150 FirstRowRiDefdMassgProgCfgMassgI 0;
BA_ "SystemSignalLongSymbol" SG_ 150 FirstRowRiDefdMassgProgCfgMassgI "FirstRowRiDefdMassgProgCfgMassgIntenSelect";
BA_ "GenSigStartValue" SG_ 150 FirstRowRiDefdMassgProgCfgMassPr 1;
BA_ "GenSigSendType" SG_ 150 FirstRowRiDefdMassgProgCfgMassPr 0;
BA_ "SystemSignalLongSymbol" SG_ 150 FirstRowRiDefdMassgProgCfgMassPr "FirstRowRiDefdMassgProgCfgMassProgCntr";
BA_ "GenSigSendType" SG_ 150 FirstRowRiDefdMassgProgCfgM_0015 0;
BA_ "SystemSignalLongSymbol" SG_ 150 FirstRowRiDefdMassgProgCfgM_0015 "FirstRowRiDefdMassgProgCfgMassProgEdit";
BA_ "GenSigStartValue" SG_ 150 FirstRowRiDefdMassgProgCfgMassSe 1;
BA_ "GenSigSendType" SG_ 150 FirstRowRiDefdMassgProgCfgMassSe 0;
BA_ "SystemSignalLongSymbol" SG_ 150 FirstRowRiDefdMassgProgCfgMassSe "FirstRowRiDefdMassgProgCfgMassSeqCntr";
BA_ "GenSigSendType" SG_ 528 CoolgLoadGroupCoolgLimd 0;
BA_ "GenSigSendType" SG_ 528 CoolgLoadGroupCoolgLoad2 0;
BA_ "GenSigStartValue" SG_ 528 EngTEngT 50;
BA_ "GenSigSendType" SG_ 528 HvPwrEgyPrio 0;
BA_ "GenSigSendType" SG_ 528 MirrDefrstAtDrvrCmd 0;
BA_ "GenSigSendType" SG_ 528 MirrDefrstAtPassCmd 0;
BA_ "GenSigSendType" SG_ 528 PassSeatSts 0;
BA_ "GenSigSendType" SG_ 528 SeatDispBtnPsdDrvrSeatDispBtnPsd 0;
BA_ "GenSigSendType" SG_ 528 SeatDispBtnPsdPassSeatDispBtnPsd 0;
BA_ "GenSigSendType" SG_ 528 SeatOccptAtRowSecLe 0;
BA_ "GenSigSendType" SG_ 528 SeatOccptAtRowSecRi 0;
BA_ "GenSigStartValue" SG_ 298 DoorsOpenerReqChks 255;
BA_ "GenSigSendType" SG_ 298 DoorsOpenerReqChks 0;
BA_ "GenSigFuncType" SG_ 298 DoorsOpenerReqChks 15;
BA_ "GenSigDataID" SG_ 298 DoorsOpenerReqChks "0x460";
BA_ "GenSigSendType" SG_ 298 DoorsOpenerReqCntr 0;
BA_ "GenSigFuncType" SG_ 298 DoorsOpenerReqCntr 16;
BA_ "GenSigSendType" SG_ 298 DoorsOpenerReqDrvr 0;
BA_ "GenSigSendType" SG_ 298 DoorsOpenerReqLeRe 0;
BA_ "GenSigSendType" SG_ 298 DoorsOpenerReqPass 0;
BA_ "GenSigSendType" SG_ 298 DoorsOpenerReqRiRe 0;
BA_ "GenSigSendType" SG_ 298 DoorsOpenerReqTrigSrcDrvr 0;
BA_ "GenSigSendType" SG_ 298 DoorsOpenerReqTrigSrcLeRe 0;
BA_ "GenSigSendType" SG_ 298 DoorsOpenerReqTrigSrcPass 0;
BA_ "GenSigSendType" SG_ 298 DoorsOpenerReqTrigSrcRiRe 0;
BA_ "GenSigSendType" SG_ 298 DoorsOpenerReqVehMtnSts 0;
BA_ "GenSigSendType" SG_ 298 SecRowRiDefdMassgProgCfgMassgBag 0;
BA_ "SystemSignalLongSymbol" SG_ 298 SecRowRiDefdMassgProgCfgMassgBag "SecRowRiDefdMassgProgCfgMassgBag01Select";
BA_ "GenSigSendType" SG_ 298 SecRowRiDefdMassgProgCfgMas_0000 0;
BA_ "SystemSignalLongSymbol" SG_ 298 SecRowRiDefdMassgProgCfgMas_0000 "SecRowRiDefdMassgProgCfgMassgBag02Select";
BA_ "GenSigSendType" SG_ 298 SecRowRiDefdMassgProgCfgMas_0001 0;
BA_ "SystemSignalLongSymbol" SG_ 298 SecRowRiDefdMassgProgCfgMas_0001 "SecRowRiDefdMassgProgCfgMassgBag03Select";
BA_ "GenSigSendType" SG_ 298 SecRowRiDefdMassgProgCfgMas_0002 0;
BA_ "SystemSignalLongSymbol" SG_ 298 SecRowRiDefdMassgProgCfgMas_0002 "SecRowRiDefdMassgProgCfgMassgBag04Select";
BA_ "GenSigSendType" SG_ 298 SecRowRiDefdMassgProgCfgMas_0003 0;
BA_ "SystemSignalLongSymbol" SG_ 298 SecRowRiDefdMassgProgCfgMas_0003 "SecRowRiDefdMassgProgCfgMassgBag05Select";
BA_ "GenSigSendType" SG_ 298 SecRowRiDefdMassgProgCfgMas_0004 0;
BA_ "SystemSignalLongSymbol" SG_ 298 SecRowRiDefdMassgProgCfgMas_0004 "SecRowRiDefdMassgProgCfgMassgBag06Select";
BA_ "GenSigSendType" SG_ 298 SecRowRiDefdMassgProgCfgMas_0005 0;
BA_ "SystemSignalLongSymbol" SG_ 298 SecRowRiDefdMassgProgCfgMas_0005 "SecRowRiDefdMassgProgCfgMassgBag07Select";
BA_ "GenSigSendType" SG_ 298 SecRowRiDefdMassgProgCfgMas_0006 0;
BA_ "SystemSignalLongSymbol" SG_ 298 SecRowRiDefdMassgProgCfgMas_0006 "SecRowRiDefdMassgProgCfgMassgBag08Select";
BA_ "GenSigSendType" SG_ 298 SecRowRiDefdMassgProgCfgMas_0007 0;
BA_ "SystemSignalLongSymbol" SG_ 298 SecRowRiDefdMassgProgCfgMas_0007 "SecRowRiDefdMassgProgCfgMassgBag09Select";
BA_ "GenSigSendType" SG_ 298 SecRowRiDefdMassgProgCfgMas_0008 0;
BA_ "SystemSignalLongSymbol" SG_ 298 SecRowRiDefdMassgProgCfgMas_0008 "SecRowRiDefdMassgProgCfgMassgBag10Select";
BA_ "GenSigSendType" SG_ 298 SecRowRiDefdMassgProgCfgMas_0009 0;
BA_ "SystemSignalLongSymbol" SG_ 298 SecRowRiDefdMassgProgCfgMas_0009 "SecRowRiDefdMassgProgCfgMassgBag11Select";
BA_ "GenSigSendType" SG_ 298 SecRowRiDefdMassgProgCfgMas_0010 0;
BA_ "SystemSignalLongSymbol" SG_ 298 SecRowRiDefdMassgProgCfgMas_0010 "SecRowRiDefdMassgProgCfgMassgBag12Select";
BA_ "GenSigSendType" SG_ 298 SecRowRiDefdMassgProgCfgMas_0011 0;
BA_ "SystemSignalLongSymbol" SG_ 298 SecRowRiDefdMassgProgCfgMas_0011 "SecRowRiDefdMassgProgCfgMassgBag13Select";
BA_ "GenSigSendType" SG_ 298 SecRowRiDefdMassgProgCfgMas_0012 0;
BA_ "SystemSignalLongSymbol" SG_ 298 SecRowRiDefdMassgProgCfgMas_0012 "SecRowRiDefdMassgProgCfgMassgBag14Select";
BA_ "GenSigSendType" SG_ 298 SecRowRiDefdMassgProgCfgMas_0013 0;
BA_ "SystemSignalLongSymbol" SG_ 298 SecRowRiDefdMassgProgCfgMas_0013 "SecRowRiDefdMassgProgCfgMassgBag15Select";
BA_ "GenSigSendType" SG_ 298 SecRowRiDefdMassgProgCfgMas_0014 0;
BA_ "SystemSignalLongSymbol" SG_ 298 SecRowRiDefdMassgProgCfgMas_0014 "SecRowRiDefdMassgProgCfgMassgBag16Select";
BA_ "GenSigSendType" SG_ 298 SecRowRiDefdMassgProgCfgMassgFrq 0;
BA_ "SystemSignalLongSymbol" SG_ 298 SecRowRiDefdMassgProgCfgMassgFrq "SecRowRiDefdMassgProgCfgMassgFrqSelect";
BA_ "GenSigSendType" SG_ 298 SecRowRiDefdMassgProgCfgMassgInt 0;
BA_ "SystemSignalLongSymbol" SG_ 298 SecRowRiDefdMassgProgCfgMassgInt "SecRowRiDefdMassgProgCfgMassgIntenSelect";
BA_ "GenSigStartValue" SG_ 298 SecRowRiDefdMassgProgCfgMassProg 1;
BA_ "GenSigSendType" SG_ 298 SecRowRiDefdMassgProgCfgMassProg 0;
BA_ "SystemSignalLongSymbol" SG_ 298 SecRowRiDefdMassgProgCfgMassProg "SecRowRiDefdMassgProgCfgMassProgCntr";
BA_ "GenSigSendType" SG_ 298 SecRowRiDefdMassgProgCfgMas_0015 0;
BA_ "SystemSignalLongSymbol" SG_ 298 SecRowRiDefdMassgProgCfgMas_0015 "SecRowRiDefdMassgProgCfgMassProgEdit";
BA_ "GenSigStartValue" SG_ 298 SecRowRiDefdMassgProgCfgMassSeqC 1;
BA_ "GenSigSendType" SG_ 298 SecRowRiDefdMassgProgCfgMassSeqC 0;
BA_ "SystemSignalLongSymbol" SG_ 298 SecRowRiDefdMassgProgCfgMassSeqC "SecRowRiDefdMassgProgCfgMassSeqCntr";
BA_ "GenSigSendType" SG_ 656 CnctSrvFragChRatReqFragRatForCh1 1;
BA_ "GenSigSendType" SG_ 656 CnctSrvFragChRatReqFragRatForCh2 1;
BA_ "GenSigSendType" SG_ 656 CnctSrvFragChRatReqFragRatForCh3 1;
BA_ "GenSigSendType" SG_ 656 CnctSrvFragChRatReqFragRatForCh4 1;
BA_ "GenSigSendType" SG_ 656 CnctSrvFragChRatReqFragRatForCh5 1;
BA_ "GenSigSendType" SG_ 656 CnctSrvFragLvlReq 1;
BA_ "GenSigSendType" SG_ 768 DrvModReq 0;
BA_ "GenSigSendType" SG_ 784 BkpOfDstTrvld 0;
BA_ "GenSigSendType" SG_ 784 CamStsCamCamFrntCalNotCmpl 0;
BA_ "GenSigSendType" SG_ 784 CamStsCamCamHeatrActv 0;
BA_ "GenSigSendType" SG_ 784 CamStsCamFrntBlkd1 0;
BA_ "GenSigSendType" SG_ 784 CamStsCamFrntBlkd2 0;
BA_ "GenSigSendType" SG_ 784 CamStsCamFrntBlkd3 0;
BA_ "GenSigSendType" SG_ 784 CamStsCamFrntBlkd4 0;
BA_ "GenSigSendType" SG_ 784 CamStsCamFrntBlkd5 0;
BA_ "GenSigSendType" SG_ 784 CamStsCamFrntBlkd6 0;
BA_ "GenSigSendType" SG_ 784 CamStsCamFrntBlkd7 0;
BA_ "GenSigSendType" SG_ 784 CamStsCamFrntBlkd8 0;
BA_ "GenSigSendType" SG_ 784 CamStsCamFrntCalNotStrtd 0;
BA_ "GenSigSendType" SG_ 784 CamStsCamFrntFaulty 0;
BA_ "GenSigSendType" SG_ 784 CamStsCamFrontEna 0;
BA_ "GenSigSendType" SG_ 784 CamStsCamMissCom 0;
BA_ "GenSigSendType" SG_ 784 CamStsChks 0;
BA_ "GenSigFuncType" SG_ 784 CamStsChks 15;
BA_ "GenSigDataID" SG_ 784 CamStsChks "0x5E9";
BA_ "GenSigSendType" SG_ 784 CamStsCntr 0;
BA_ "GenSigFuncType" SG_ 784 CamStsCntr 16;
BA_ "GenSigSendType" SG_ 464 AirTFromHeatgEstimd 0;
BA_ "GenSigSendType" SG_ 464 EcmRoilgCntr 0;
BA_ "GenSigStartValue" SG_ 464 RoadInclnQly 1;
BA_ "GenSigSendType" SG_ 464 RoadInclnQly 0;
BA_ "GenSigSendType" SG_ 464 RoadInclnRoadIncln 0;
BA_ "GenSigSendType" SG_ 464 SeatOccptAtRowSecMid 0;
BA_ "GenSigSendType" SG_ 464 SunCurtPosnSts 0;
BA_ "GenSigSendType" SG_ 464 SunRoofPosnSts 0;
BA_ "GenSigSendType" SG_ 464 WipgInfoWipgSpdInfo 0;
BA_ "GenSigSendType" SG_ 464 WipgInfoWiprActv 0;
BA_ "GenSigSendType" SG_ 464 WipgInfoWiprInWipgAr 0;
BA_ "GenSigSendType" SG_ 880 CarTiGlb 0;
BA_ "GenSigSendType" SG_ 880 EngSt1WdStsChks 0;
BA_ "GenSigFuncType" SG_ 880 EngSt1WdStsChks 15;
BA_ "GenSigDataID" SG_ 880 EngSt1WdStsChks "0x89";
BA_ "GenSigSendType" SG_ 880 EngSt1WdStsCntr 0;
BA_ "GenSigFuncType" SG_ 880 EngSt1WdStsCntr 16;
BA_ "GenSigSendType" SG_ 880 EngSt1WdStsEngSt1WdSts 0;
BA_ "GenSigSendType" SG_ 896 ClimaPwrAllwd 0;
BA_ "GenSigSendType" SG_ 896 DoorLeReIntrSwtLedLockgCmd 0;
BA_ "GenSigSendType" SG_ 896 DoorRiReIntrSwtLedLockgCmd 0;
BA_ "GenSigSendType" SG_ 896 IndcrPatCmd1WdTiOff 0;
BA_ "GenSigSendType" SG_ 896 IndcrPatCmd1WdTiOn 0;
BA_ "GenSigSendType" SG_ 816 ProfPenSts1 0;
BA_ "GenSigSendType" SG_ 816 SecRowLeDefdMassgProgSeln 0;
BA_ "GenSigSendType" SG_ 816 SecRowRiDefdMassgProgSeln 0;
BA_ "GenSigSendType" SG_ 816 VehBattUSysU 0;
BA_ "GenSigStartValue" SG_ 816 VehBattUSysUQf 1;
BA_ "GenSigSendType" SG_ 816 VehBattUSysUQf 0;
BA_ "GenSigSendType" SG_ 832 VehCfgPrmBlkIDBytePosn1 1;
BA_ "GenSigSendType" SG_ 832 VehCfgPrmCCPBytePosn2 1;
BA_ "GenSigSendType" SG_ 832 VehCfgPrmCCPBytePosn3 1;
BA_ "GenSigSendType" SG_ 832 VehCfgPrmCCPBytePosn4 1;
BA_ "GenSigSendType" SG_ 832 VehCfgPrmCCPBytePosn5 1;
BA_ "GenSigSendType" SG_ 832 VehCfgPrmCCPBytePosn6 1;
BA_ "GenSigSendType" SG_ 832 VehCfgPrmCCPBytePosn7 1;
BA_ "GenSigSendType" SG_ 832 VehCfgPrmCCPBytePosn8 1;
BA_ "GenSigSendType" SG_ 306 VehCfgPrmExtBlkIDBytePosn1 1;
BA_ "GenSigSendType" SG_ 306 VehCfgPrmExtCCPBytePosn2 1;
BA_ "GenSigSendType" SG_ 306 VehCfgPrmExtCCPBytePosn3 1;
BA_ "GenSigSendType" SG_ 306 VehCfgPrmExtCCPBytePosn4 1;
BA_ "GenSigSendType" SG_ 306 VehCfgPrmExtCCPBytePosn5 1;
BA_ "GenSigSendType" SG_ 306 VehCfgPrmExtCCPBytePosn6 1;
BA_ "GenSigSendType" SG_ 306 VehCfgPrmExtCCPBytePosn7 1;
BA_ "GenSigSendType" SG_ 306 VehCfgPrmExtCCPBytePosn8 1;
BA_ "GenSigSendType" SG_ 849 DrvrSeatHallPosExtDownLdSeatCush 1;
BA_ "SystemSignalLongSymbol" SG_ 849 DrvrSeatHallPosExtDownLdSeatCush "DrvrSeatHallPosExtDownLdSeatCushExtPos";
BA_ "GenSigSendType" SG_ 849 DrvrSeatHallPosExtDownLdSeatHead 1;
BA_ "SystemSignalLongSymbol" SG_ 849 DrvrSeatHallPosExtDownLdSeatHead "DrvrSeatHallPosExtDownLdSeatHeadrHozlPos";
BA_ "GenSigSendType" SG_ 849 DrvrSeatHallPosExtDownLdSea_0000 1;
BA_ "SystemSignalLongSymbol" SG_ 849 DrvrSeatHallPosExtDownLdSea_0000 "DrvrSeatHallPosExtDownLdSeatHeadrVertPos";
BA_ "GenSigStartValue" SG_ 849 HmiPopUpResp 3;
BA_ "GenSigSendType" SG_ 849 HmiPopUpResp 1;
BA_ "GenSigSendType" SG_ 849 VFCInfoEna 1;
BA_ "GenSigSendType" SG_ 128 AmbLiMusicShowTypAmbLiShowTyp 0;
BA_ "GenSigSendType" SG_ 128 AmbLiMusicShowTypIdPen 0;
BA_ "GenSigSendType" SG_ 128 AmbLiWelcomeShowTypAmbLiShowTyp 0;
BA_ "GenSigSendType" SG_ 128 AmbLiWelcomeShowTypIdPen 0;
BA_ "GenSigStartValue" SG_ 128 VehADModeReq 1;
BA_ "GenSigStartValue" SG_ 937 PosnBriefPosnLat 323999740.800207;
BA_ "GenSigSendType" SG_ 937 PosnBriefPosnLat 0;
BA_ "GenSigStartValue" SG_ 937 PosnBriefPosnLgt 647999481.600415;
BA_ "GenSigSendType" SG_ 937 PosnBriefPosnLgt 0;
BA_ "GenSigSendType" SG_ 928 CmprSpdAct 0;
BA_ "GenSigStartValue" SG_ 928 HmiAutDefrstEna 1;
BA_ "GenSigSendType" SG_ 928 HmiAutDefrstEna 0;
BA_ "GenSigSendType" SG_ 928 HmiAutDefrstReq 0;
BA_ "GenSigSendType" SG_ 928 HmiClimaFrntAutReq 0;
BA_ "GenSigSendType" SG_ 928 HmiClimaReAutReq 0;
BA_ "GenSigSendType" SG_ 928 HmiCmptmtAirDistbnFrntLe 0;
BA_ "GenSigSendType" SG_ 928 HmiCmptmtAirDistbnFrntRi 0;
BA_ "GenSigSendType" SG_ 928 HmiCmptmtAirDistbnRe 0;
BA_ "GenSigSendType" SG_ 928 HmiElecAirDirModReqDrvrMod 0;
BA_ "GenSigSendType" SG_ 928 HmiElecAirDirModReqPassMod 0;
BA_ "GenSigSendType" SG_ 928 HmiElecAirSwngReqDrvrLeRiSwng 0;
BA_ "GenSigSendType" SG_ 928 HmiElecAirSwngReqDrvrUpOnSwng 0;
BA_ "GenSigSendType" SG_ 928 HmiElecAirSwngReqPassLeRiSwng 0;
BA_ "GenSigSendType" SG_ 928 HmiElecAirSwngReqPassUpOnSwng 0;
BA_ "GenSigSendType" SG_ 928 HmiFragraLvlReq 0;
BA_ "GenSigSendType" SG_ 928 HmiFragraModReq 0;
BA_ "GenSigStartValue" SG_ 928 HmiHumCtrlEna 1;
BA_ "GenSigSendType" SG_ 928 HmiHumCtrlEna 0;
BA_ "GenSigStartValue" SG_ 928 IncomingCO2CtrlFromHmi 1;
BA_ "GenSigSendType" SG_ 928 IncomingCO2CtrlFromHmi 0;
BA_ "GenSigSendType" SG_ 928 SecRowLeSeatDispMassgFctMassgInt 0;
BA_ "SystemSignalLongSymbol" SG_ 928 SecRowLeSeatDispMassgFctMassgInt "SecRowLeSeatDispMassgFctMassgInten";
BA_ "GenSigSendType" SG_ 928 SecRowLeSeatDispMassgFctMassgPro 0;
BA_ "SystemSignalLongSymbol" SG_ 928 SecRowLeSeatDispMassgFctMassgPro "SecRowLeSeatDispMassgFctMassgProg";
BA_ "GenSigSendType" SG_ 928 SecRowLeSeatDispMassgFctOnOff 0;
BA_ "GenSigSendType" SG_ 645 BookTrvlClimaActvReq 1;
BA_ "GenSigSendType" SG_ 645 ClimaTmrStsTelmRqrd 1;
BA_ "GenSigSendType" SG_ 645 IntelliClimaReq 1;
BA_ "GenSigSendType" SG_ 645 RemVentReq 1;
BA_ "GenSigSendType" SG_ 645 SeatHeatDurgClimaEnadFromTelm 1;
BA_ "GenSigSendType" SG_ 645 SteerWhlHeatgDurgClimaEnadFromTe 1;
BA_ "SystemSignalLongSymbol" SG_ 645 SteerWhlHeatgDurgClimaEnadFromTe "SteerWhlHeatgDurgClimaEnadFromTelm";
BA_ "SystemSignalLongSymbol" SG_ 645 SteerWhlHeatgDurgClimaEnadF_0000 "SteerWhlHeatgDurgClimaEnadFromTelm_UB";
BA_ "GenSigSendType" SG_ 645 TelmClimaReq 1;
BA_ "GenSigSendType" SG_ 645 TelmClimaTmr 1;
BA_ "GenSigSendType" SG_ 645 TelmClimaTSetHmiCmptmtTSpSpcl 1;
BA_ "GenSigSendType" SG_ 645 TelmClimaTSetTempRange 1;
BA_ "GenSigSendType" SG_ 645 TelmSeatPassVentnClimaLvl 1;
BA_ "GenSigSendType" SG_ 645 TelmSeatSecLeHeatClimaLvl 1;
BA_ "GenSigSendType" SG_ 645 TelmSeatSecLeVentnClimaLvl 1;
BA_ "GenSigSendType" SG_ 645 TelmSeatSecRiHeatClimaLvl 1;
BA_ "GenSigSendType" SG_ 645 TelmSeatSecRiVentnClimaLvl 1;
BA_ "GenSigSendType" SG_ 855 ClimaRqrd1 1;
BA_ "GenSigSendType" SG_ 855 HMIClimaEgySaveReq 1;
BA_ "GenSigSendType" SG_ 855 HmiEcoClimaSetgIdPen 1;
BA_ "GenSigSendType" SG_ 855 HmiEcoClimaSetgOnOff1 1;
BA_ "GenSigSendType" SG_ 855 MirrPosnFromCldAtDrvrMirrPosnAdj 1;
BA_ "SystemSignalLongSymbol" SG_ 855 MirrPosnFromCldAtDrvrMirrPosnAdj "MirrPosnFromCldAtDrvrMirrPosnAdjCldLeRi";
BA_ "GenSigSendType" SG_ 855 MirrPosnFromCldAtDrvrMirrPo_0000 1;
BA_ "SystemSignalLongSymbol" SG_ 855 MirrPosnFromCldAtDrvrMirrPo_0000 "MirrPosnFromCldAtDrvrMirrPosnAdjCldUpDwn";
BA_ "GenSigSendType" SG_ 855 MirrPosnFromCldAtPassMirrPosnAdj 1;
BA_ "SystemSignalLongSymbol" SG_ 855 MirrPosnFromCldAtPassMirrPosnAdj "MirrPosnFromCldAtPassMirrPosnAdjCldLeRi";
BA_ "GenSigSendType" SG_ 855 MirrPosnFromCldAtPassMirrPo_0000 1;
BA_ "SystemSignalLongSymbol" SG_ 855 MirrPosnFromCldAtPassMirrPo_0000 "MirrPosnFromCldAtPassMirrPosnAdjCldUpDwn";
BA_ "GenSigSendType" SG_ 855 ReqFragLvlTelm 1;
BA_ "GenSigSendType" SG_ 855 TelmAirFragTasteReq 1;
BA_ "GenSigSendType" SG_ 855 TelmPM25Req 1;
BA_ "GenSigSendType" SG_ 855 TelmSeatDrvHeatClimaLvl 1;
BA_ "GenSigSendType" SG_ 855 TelmSeatDrvVentnClimaLvl 1;
BA_ "GenSigSendType" SG_ 855 TelmSeatPassHeatClimaLvl 1;
BA_ "GenSigSendType" SG_ 944 HmiElecAirDirCrtlReqDrvrLePosX 0;
BA_ "GenSigSendType" SG_ 944 HmiElecAirDirCrtlReqDrvrLePosY 0;
BA_ "GenSigSendType" SG_ 944 HmiElecAirDirCrtlReqDrvrRiPosX 0;
BA_ "GenSigSendType" SG_ 944 HmiElecAirDirCrtlReqDrvrRiPosY 0;
BA_ "GenSigSendType" SG_ 944 HmiElecAirDirCrtlReqPassLePosX 0;
BA_ "GenSigSendType" SG_ 944 HmiElecAirDirCrtlReqPassLePosY 0;
BA_ "GenSigSendType" SG_ 944 HmiElecAirDirCrtlReqPassRiPosX 0;
BA_ "GenSigSendType" SG_ 944 HmiElecAirDirCrtlReqPassRiPosY 0;
BA_ "GenSigStartValue" SG_ 951 HmiFragraChRatReqFragRatForCh1 100;
BA_ "GenSigSendType" SG_ 951 HmiFragraChRatReqFragRatForCh1 0;
BA_ "GenSigStartValue" SG_ 951 HmiFragraChRatReqFragRatForCh2 100;
BA_ "GenSigSendType" SG_ 951 HmiFragraChRatReqFragRatForCh2 0;
BA_ "GenSigStartValue" SG_ 951 HmiFragraChRatReqFragRatForCh3 100;
BA_ "GenSigSendType" SG_ 951 HmiFragraChRatReqFragRatForCh3 0;
BA_ "GenSigStartValue" SG_ 951 HmiFragraChRatReqFragRatForCh4 100;
BA_ "GenSigSendType" SG_ 951 HmiFragraChRatReqFragRatForCh4 0;
BA_ "GenSigStartValue" SG_ 951 HmiFragraChRatReqFragRatForCh5 100;
BA_ "GenSigSendType" SG_ 951 HmiFragraChRatReqFragRatForCh5 0;
BA_ "GenSigSendType" SG_ 951 HmiMaxACReq 0;
BA_ "GenSigSendType" SG_ 356 IntelliClimaActrPosnTempLeFrnt 1;
BA_ "SystemSignalLongSymbol" SG_ 356 IntelliClimaActrPosnTempLeFrnt_U "IntelliClimaActrPosnTempLeFrnt_UB";
BA_ "GenSigSendType" SG_ 356 IntelliClimaActrPosnTempRiFrnt 1;
BA_ "SystemSignalLongSymbol" SG_ 356 IntelliClimaActrPosnTempRiFrnt_U "IntelliClimaActrPosnTempRiFrnt_UB";
BA_ "GenSigStartValue" SG_ 356 IntelliClimaCmptmtAirTEstimd 600;
BA_ "GenSigSendType" SG_ 356 IntelliClimaCmptmtAirTEstimd 1;
BA_ "GenSigSendType" SG_ 356 IntelliClimaFanSpdReq 1;
BA_ "GenSigSendType" SG_ 356 IntelliClimaModDistbnReq 1;
BA_ "GenSigSendType" SG_ 356 IntelliClimaRecFlapPosnReq 1;
BA_ "GenSigSendType" SG_ 151 BackRestSideSpprtAdjmtRowFirstDr 0;
BA_ "SystemSignalLongSymbol" SG_ 151 BackRestSideSpprtAdjmtRowFirstDr "BackRestSideSpprtAdjmtRowFirstDrvr";
BA_ "SystemSignalLongSymbol" SG_ 151 BackRestSideSpprtAdjmtRowFi_0000 "BackRestSideSpprtAdjmtRowFirstDrvr_UB";
BA_ "GenSigSendType" SG_ 151 BackRestSideSpprtAdjmtRowFirstPa 0;
BA_ "SystemSignalLongSymbol" SG_ 151 BackRestSideSpprtAdjmtRowFirstPa "BackRestSideSpprtAdjmtRowFirstPass";
BA_ "SystemSignalLongSymbol" SG_ 151 BackRestSideSpprtAdjmtRowFi_0001 "BackRestSideSpprtAdjmtRowFirstPass_UB";
BA_ "GenSigSendType" SG_ 151 EasyInOutSecRowLeActv 0;
BA_ "GenSigSendType" SG_ 151 EasyInOutSecRowLeReq 0;
BA_ "GenSigSendType" SG_ 151 EasyInOutSecRowRiActv 0;
BA_ "GenSigSendType" SG_ 151 EasyInOutSecRowRiReq 0;
BA_ "GenSigSendType" SG_ 151 LumHeiAdjmtRowFirstDrvr 0;
BA_ "GenSigSendType" SG_ 151 LumHeiAdjmtRowFirstPass 0;
BA_ "GenSigSendType" SG_ 151 LumLenAdjmtRowFirstDrvr 0;
BA_ "GenSigSendType" SG_ 151 LumLenAdjmtRowFirstPass 0;
BA_ "GenSigSendType" SG_ 153 CushExtnFirstDrvr 0;
BA_ "GenSigSendType" SG_ 153 CushExtnFirstPass 0;
BA_ "GenSigSendType" SG_ 153 CushSideSpprtAdjmtRowFirstDrvr 0;
BA_ "SystemSignalLongSymbol" SG_ 153 CushSideSpprtAdjmtRowFirstDrvr_U "CushSideSpprtAdjmtRowFirstDrvr_UB";
BA_ "GenSigSendType" SG_ 153 CushSideSpprtAdjmtRowFirstPass 0;
BA_ "SystemSignalLongSymbol" SG_ 153 CushSideSpprtAdjmtRowFirstPass_U "CushSideSpprtAdjmtRowFirstPass_UB";
BA_ "GenSigSendType" SG_ 153 HdRestAdjmtRowFirstDrvr 0;
BA_ "GenSigSendType" SG_ 153 HdRestAdjmtRowFirstPass 0;
BA_ "GenSigSendType" SG_ 153 HdRestHeiAdjmtRowFirstDrvr 0;
BA_ "GenSigSendType" SG_ 153 HdRestHeiAdjmtRowFirstPass 0;
BA_ "GenSigSendType" SG_ 153 HvahFltIndcnReq 0;
BA_ "GenSigSendType" SG_ 153 LumHeiAdjmtSecRowLe 0;
BA_ "GenSigSendType" SG_ 153 LumHeiAdjmtSecRowRi 0;
BA_ "GenSigSendType" SG_ 153 LumLenAdjmtSecRowLe 0;
BA_ "GenSigSendType" SG_ 153 LumLenAdjmtSecRowRi 0;
BA_ "GenSigStartValue" SG_ 153 PassAirbSts 1;
BA_ "GenSigSendType" SG_ 153 PassAirbSts 0;
BA_ "GenSigStartValue" SG_ 300 CmptmtFrntWindDewT 600;
BA_ "GenSigSendType" SG_ 300 CmptmtFrntWindDewT 0;
BA_ "GenSigStartValue" SG_ 300 CmptmtFrntWindT 650;
BA_ "GenSigSendType" SG_ 300 CmptmtFrntWindT 0;
BA_ "GenSigStartValue" SG_ 300 CmptmtRelHum 80;
BA_ "GenSigSendType" SG_ 300 CmptmtRelHum 0;
BA_ "GenSigStartValue" SG_ 300 LeReDblPullHndlMotRstCmd 2;
BA_ "GenSigSendType" SG_ 300 LeReDblPullHndlMotRstCmd 0;
BA_ "GenSigSendType" SG_ 300 PwrDoorEnaHmiStsPSD 0;
BA_ "GenSigStartValue" SG_ 300 RiReDblPullHndlMotRstCmd 2;
BA_ "GenSigSendType" SG_ 300 RiReDblPullHndlMotRstCmd 0;
BA_ "GenSigStartValue" SG_ 300 TempPodSys 121;
BA_ "GenSigSendType" SG_ 300 TempPodSys 0;
BA_ "GenSigSendType" SG_ 447 PostDrvgClimaReq 0;
BA_ "GenSigSendType" SG_ 447 RemStrtExtnTiReq 1;
BA_ "GenSigSendType" SG_ 447 StrtInProgs 0;
BA_ "GenSigSendType" SG_ 570 DCChrgnHndlSts 0;
BA_ "GenSigSendType" SG_ 570 DefrstStsMirrDefrst 0;
BA_ "GenSigSendType" SG_ 570 DefrstStsWinDefrstFrnt 0;
BA_ "GenSigSendType" SG_ 570 DefrstStsWinDefrstRe 0;
BA_ "GenSigStartValue" SG_ 570 IsgMotT 50;
BA_ "GenSigSendType" SG_ 570 IsgMotT 0;
BA_ "GenSigSendType" SG_ 570 WiprFrntSrvModReq 0;
BA_ "GenSigSendType" SG_ 178 BootFoldSwtActv2 0;
BA_ "GenSigSendType" SG_ 178 BootFoldSwtActv3 0;
BA_ "GenSigSendType" SG_ 178 ClimaRqrdFromHmi 0;
BA_ "GenSigSendType" SG_ 178 LVPwrSplyErrSts 0;
BA_ "GenSigSendType" SG_ 178 SecRowLeCmftSet 0;
BA_ "GenSigSendType" SG_ 178 TiDrvgCycOff 0;
BA_ "GenSigSendType" SG_ 178 WinOpenDrvrReq 0;
BA_ "GenSigSendType" SG_ 178 WinOpenPassReq 0;
BA_ "GenSigSendType" SG_ 178 WinOpenReLeReq 0;
BA_ "GenSigSendType" SG_ 178 WinOpenReRiReq 0;
BA_ "GenSigSendType" SG_ 178 WinVentnOpenReq 0;
BA_ "GenSigSendType" SG_ 196 DoorOpenwarnLeIndcn 0;
BA_ "GenSigSendType" SG_ 196 DoorOpenwarnRiIndcn 0;
BA_ "GenSigSendType" SG_ 196 LoadAndStoreReqErgoPosn 0;
BA_ "GenSigSendType" SG_ 196 LoadAndStoreReqErgoSetgEve 0;
BA_ "GenSigSendType" SG_ 196 LoadAndStoreReqIdPen 0;
BA_ "GenSigSendType" SG_ 196 LoadAndStoreReqInOutEasy 0;
BA_ "GenSigSendType" SG_ 196 PwrAvlDelta 0;
BA_ "GenSigSendType" SG_ 196 RctaIndcnLe 0;
BA_ "GenSigSendType" SG_ 196 RctaIndcnRi 0;
BA_ "GenSigSendType" SG_ 196 VehWinSunRoofClsReq 0;
BA_ "GenSigSendType" SG_ 257 HvBattSoc 0;
BA_ "GenSigSendType" SG_ 257 TrlrLampChkAutReqPen 0;
BA_ "GenSigSendType" SG_ 257 TrlrLampChkAutReqSts 0;
BA_ "GenSigSendType" SG_ 853 ActvnOfWshrFrntSafe 0;
BA_ "GenSigSendType" SG_ 853 StrtRemSts1WdStrtRemSts 0;
BA_ "GenSigSendType" SG_ 152 CbnOverHeatProtnEnaFromTelm 1;
BA_ "GenSigSendType" SG_ 152 DrvrDesDirChks 0;
BA_ "GenSigSendType" SG_ 152 DrvrDesDirCntr 0;
BA_ "GenSigSendType" SG_ 152 DrvrDesDirDrvrDesDir 0;
BA_ "GenSigSendType" SG_ 152 HvEgyCnsAllwdForClima 0;
BA_ "GenSigSendType" SG_ 152 OnBdChrgrSt 0;
BA_ "GenSigSendType" SG_ 152 PassSceneModSeld 0;
BA_ "GenSigSendType" SG_ 152 SecRowLeSceneModSeld 0;
BA_ "GenSigSendType" SG_ 152 SecRowRiSceneModSeld 0;
BA_ "GenSigSendType" SG_ 152 SpeechSts 0;
BA_ "GenSigSendType" SG_ 152 TrRelsReq 0;
BA_ "GenSigSendType" SG_ 309 BackRestAdjmtRowFirstDrvr 0;
BA_ "GenSigSendType" SG_ 309 BackRestAdjmtRowFirstPass 0;
BA_ "GenSigStartValue" SG_ 309 EmgyBrkLiIndcrTurn 1;
BA_ "GenSigSendType" SG_ 309 EmgyBrkLiIndcrTurn 0;
BA_ "GenSigSendType" SG_ 309 SeatCushTiltAdjmtRowFirstDrvr 0;
BA_ "GenSigSendType" SG_ 309 SeatCushTiltAdjmtRowFirstPass 0;
BA_ "GenSigSendType" SG_ 309 SeatHeiAdjmtRowFirstDrvr 0;
BA_ "GenSigSendType" SG_ 309 SeatHeiAdjmtRowFirstPass 0;
BA_ "GenSigSendType" SG_ 309 SeatLenAdjmtRowFirstDrvr 0;
BA_ "GenSigSendType" SG_ 309 SeatLenAdjmtRowFirstPass 0;
BA_ "GenSigSendType" SG_ 180 ActvnOfHndlDoorLiHndlDoorLiDrvr 0;
BA_ "GenSigSendType" SG_ 180 ActvnOfHndlDoorLiHndlDoorLiDrvrR 0;
BA_ "SystemSignalLongSymbol" SG_ 180 ActvnOfHndlDoorLiHndlDoorLiDrvrR "ActvnOfHndlDoorLiHndlDoorLiDrvrRe";
BA_ "GenSigSendType" SG_ 180 ActvnOfHndlDoorLiHndlDoorLiPass 0;
BA_ "GenSigSendType" SG_ 180 ActvnOfHndlDoorLiHndlDoorLiPassR 0;
BA_ "SystemSignalLongSymbol" SG_ 180 ActvnOfHndlDoorLiHndlDoorLiPassR "ActvnOfHndlDoorLiHndlDoorLiPassRe";
BA_ "GenSigSendType" SG_ 180 ActvnOfRoofSwtIllmn 0;
BA_ "GenSigSendType" SG_ 180 MobDevVentReq 0;
BA_ "GenSigSendType" SG_ 180 SceneModSeld 0;
BA_ "GenSigSendType" SG_ 1045 ResrvdSigForCCM1 0;
BA_ "GenSigSendType" SG_ 1045 ResrvdSigForCCM2 0;
BA_ "GenSigSendType" SG_ 1045 ResrvdSigForCCM3 0;
BA_ "GenSigSendType" SG_ 1045 ResrvdSigForCCM4 0;
BA_ "GenSigSendType" SG_ 468 ActiveZoneIinfoZone1ONOff 0;
BA_ "GenSigSendType" SG_ 468 ActiveZoneIinfoZone2ONOff 0;
BA_ "GenSigSendType" SG_ 468 ActiveZoneIinfoZone3ONOff 0;
BA_ "GenSigStartValue" SG_ 468 CrashStsSafeChks 255;
BA_ "GenSigSendType" SG_ 468 CrashStsSafeChks 1;
BA_ "GenSigFuncType" SG_ 468 CrashStsSafeChks 15;
BA_ "GenSigDataID" SG_ 468 CrashStsSafeChks "0x40B";
BA_ "GenSigSendType" SG_ 468 CrashStsSafeCntr 1;
BA_ "GenSigFuncType" SG_ 468 CrashStsSafeCntr 16;
BA_ "GenSigSendType" SG_ 468 CrashStsSafeSts 1;
BA_ "GenSigSendType" SG_ 468 DrvrSeatDispMassgFctMassgInten 0;
BA_ "GenSigSendType" SG_ 468 DrvrSeatDispMassgFctMassgProg 0;
BA_ "GenSigSendType" SG_ 468 DrvrSeatDispMassgFctOnOff 0;
BA_ "GenSigSendType" SG_ 468 DrvrSeatDispSpplFct 0;
BA_ "GenSigSendType" SG_ 468 PassSeatDispMassgFctMassgInten 0;
BA_ "GenSigSendType" SG_ 468 PassSeatDispMassgFctMassgProg 0;
BA_ "GenSigSendType" SG_ 468 PassSeatDispMassgFctOnOff 0;
BA_ "GenSigSendType" SG_ 468 PassSeatDispSpplFct 0;
BA_ "GenSigSendType" SG_ 468 RemStrtHvCtrlReqErsCmd 1;
BA_ "GenSigSendType" SG_ 468 RemStrtHvCtrlReqErsRunTime 1;
BA_ "GenSigSendType" SG_ 956 IntelliClimaResd1 1;
BA_ "GenSigSendType" SG_ 956 IntelliClimaResd2 1;
BA_ "GenSigSendType" SG_ 956 IntelliClimaResd3 1;
BA_ "GenSigSendType" SG_ 956 IntelliClimaResd4 1;
BA_ "GenSigSendType" SG_ 956 IntelliClimaResd5 1;
BA_ "GenSigSendType" SG_ 956 IntelliClimaResd6 1;
BA_ "GenSigSendType" SG_ 958 IntelliClimaResd7 1;
BA_ "GenSigSendType" SG_ 958 IntelliClimaResd8 1;
BA_ "GenSigSendType" SG_ 958 IntelliClimaResd9 1;
BA_ "GenSigSendType" SG_ 958 WinOpenClsGlbReqFromTelmWindowOp 1;
BA_ "SystemSignalLongSymbol" SG_ 958 WinOpenClsGlbReqFromTelmWindowOp "WinOpenClsGlbReqFromTelmWindowOpenValue";
BA_ "GenSigSendType" SG_ 958 WinOpenClsGlbReqFromTelmWinOpenC 1;
BA_ "SystemSignalLongSymbol" SG_ 958 WinOpenClsGlbReqFromTelmWinOpenC "WinOpenClsGlbReqFromTelmWinOpenClsGlbSts";
BA_ "GenSigSendType" SG_ 963 IntelliClimaResd10 1;
BA_ "GenSigSendType" SG_ 963 IntelliClimaResd11 1;
BA_ "GenSigStartValue" SG_ 967 IntelliClimaHvacEvaprTSp 50;
BA_ "GenSigSendType" SG_ 967 IntelliClimaHvacEvaprTSp 1;
BA_ "GenSigSendType" SG_ 967 IntelliClimaHvBattInCooltFlowReq 1;
BA_ "SystemSignalLongSymbol" SG_ 967 IntelliClimaHvBattInCooltFl_0000 "IntelliClimaHvBattInCooltFlowReq_UB";
BA_ "GenSigStartValue" SG_ 967 IntelliClimaHvBattInCooltTReq 50;
BA_ "GenSigSendType" SG_ 967 IntelliClimaHvBattInCooltTReq 1;
BA_ "GenSigSendType" SG_ 967 IntelliClimaResd12 1;
BA_ "GenSigStartValue" SG_ 971 IntelliClimaHvCooltHeatrTReq 40;
BA_ "GenSigSendType" SG_ 971 IntelliClimaHvCooltHeatrTReq 1;
BA_ "GenSigSendType" SG_ 971 IntelliClimaResd13 1;
BA_ "GenSigSendType" SG_ 971 IntelliClimaUsrFanPrefrnc 1;
BA_ "GenSigSendType" SG_ 971 IntelliClimaUsrHumPrefrnc 1;
BA_ "GenSigSendType" SG_ 975 IntelliClimaResd14 1;
BA_ "GenSigSendType" SG_ 975 IntelliClimaUsrFanPrefrncEn 1;
BA_ "GenSigSendType" SG_ 975 IntelliClimaUsrHumPrefrncEn 1;
BA_ "GenSigSendType" SG_ 975 IntelliClimaUsrTPrefrnc 1;
BA_ "GenSigSendType" SG_ 975 IntelliClimaUsrTPrefrncEn 1;
BA_ "GenSigSendType" SG_ 952 HmiHvacRecircLongPsdSts 1;
BA_ "GenSigSendType" SG_ 952 IntelliClimaResd15 1;
BA_ "GenSigSendType" SG_ 952 MirrOpenClsReq 1;
BA_ "GenSigSendType" SG_ 952 WinOpenAppReqWindowOpenValue 1;
BA_ "GenSigSendType" SG_ 952 WinOpenAppReqWinOpenClsGlbSts 1;
VAL_ 150 FirstRowLeDefdMassgProgCfgMassgB 0 "SelectNoSelect_Select" 1 "SelectNoSelect_NoSelect" ;
VAL_ 150 FirstRowLeDefdMassgProgCfgM_0000 0 "SelectNoSelect_Select" 1 "SelectNoSelect_NoSelect" ;
VAL_ 150 FirstRowLeDefdMassgProgCfgM_0001 0 "SelectNoSelect_Select" 1 "SelectNoSelect_NoSelect" ;
VAL_ 150 FirstRowLeDefdMassgProgCfgM_0002 0 "SelectNoSelect_Select" 1 "SelectNoSelect_NoSelect" ;
VAL_ 150 FirstRowLeDefdMassgProgCfgM_0003 0 "SelectNoSelect_Select" 1 "SelectNoSelect_NoSelect" ;
VAL_ 150 FirstRowLeDefdMassgProgCfgM_0004 0 "SelectNoSelect_Select" 1 "SelectNoSelect_NoSelect" ;
VAL_ 150 FirstRowLeDefdMassgProgCfgM_0005 0 "SelectNoSelect_Select" 1 "SelectNoSelect_NoSelect" ;
VAL_ 150 FirstRowLeDefdMassgProgCfgM_0006 0 "SelectNoSelect_Select" 1 "SelectNoSelect_NoSelect" ;
VAL_ 150 FirstRowLeDefdMassgProgCfgM_0007 0 "SelectNoSelect_Select" 1 "SelectNoSelect_NoSelect" ;
VAL_ 150 FirstRowLeDefdMassgProgCfgM_0008 0 "SelectNoSelect_Select" 1 "SelectNoSelect_NoSelect" ;
VAL_ 150 FirstRowLeDefdMassgProgCfgM_0009 0 "SelectNoSelect_Select" 1 "SelectNoSelect_NoSelect" ;
VAL_ 150 FirstRowLeDefdMassgProgCfgM_0010 0 "SelectNoSelect_Select" 1 "SelectNoSelect_NoSelect" ;
VAL_ 150 FirstRowLeDefdMassgProgCfgM_0011 0 "SelectNoSelect_Select" 1 "SelectNoSelect_NoSelect" ;
VAL_ 150 FirstRowLeDefdMassgProgCfgM_0012 0 "SelectNoSelect_Select" 1 "SelectNoSelect_NoSelect" ;
VAL_ 150 FirstRowLeDefdMassgProgCfgM_0013 0 "SelectNoSelect_Select" 1 "SelectNoSelect_NoSelect" ;
VAL_ 150 FirstRowLeDefdMassgProgCfgM_0014 0 "SelectNoSelect_Select" 1 "SelectNoSelect_NoSelect" ;
VAL_ 150 FirstRowLeDefdMassgProgCfgMassgF 0 "SelectLvl_Idle" 1 "SelectLvl_Level1" 2 "SelectLvl_Level2" 3 "SelectLvl_Level3" ;
VAL_ 150 FirstRowLeDefdMassgProgCfgMassgI 0 "SelectLvl_Idle" 1 "SelectLvl_Level1" 2 "SelectLvl_Level2" 3 "SelectLvl_Level3" ;
VAL_ 150 FirstRowLeDefdMassgProgCfgM_0015 0 "ProgEdit_Idle" 1 "ProgEdit_Edit" 2 "ProgEdit_Remove" 3 "ProgEdit_Save" ;
VAL_ 150 FirstRowRiDefdMassgProgCfgMassgB 0 "SelectNoSelect_Select" 1 "SelectNoSelect_NoSelect" ;
VAL_ 150 FirstRowRiDefdMassgProgCfgM_0000 0 "SelectNoSelect_Select" 1 "SelectNoSelect_NoSelect" ;
VAL_ 150 FirstRowRiDefdMassgProgCfgM_0001 0 "SelectNoSelect_Select" 1 "SelectNoSelect_NoSelect" ;
VAL_ 150 FirstRowRiDefdMassgProgCfgM_0002 0 "SelectNoSelect_Select" 1 "SelectNoSelect_NoSelect" ;
VAL_ 150 FirstRowRiDefdMassgProgCfgM_0003 0 "SelectNoSelect_Select" 1 "SelectNoSelect_NoSelect" ;
VAL_ 150 FirstRowRiDefdMassgProgCfgM_0004 0 "SelectNoSelect_Select" 1 "SelectNoSelect_NoSelect" ;
VAL_ 150 FirstRowRiDefdMassgProgCfgM_0005 0 "SelectNoSelect_Select" 1 "SelectNoSelect_NoSelect" ;
VAL_ 150 FirstRowRiDefdMassgProgCfgM_0006 0 "SelectNoSelect_Select" 1 "SelectNoSelect_NoSelect" ;
VAL_ 150 FirstRowRiDefdMassgProgCfgM_0007 0 "SelectNoSelect_Select" 1 "SelectNoSelect_NoSelect" ;
VAL_ 150 FirstRowRiDefdMassgProgCfgM_0008 0 "SelectNoSelect_Select" 1 "SelectNoSelect_NoSelect" ;
VAL_ 150 FirstRowRiDefdMassgProgCfgM_0009 0 "SelectNoSelect_Select" 1 "SelectNoSelect_NoSelect" ;
VAL_ 150 FirstRowRiDefdMassgProgCfgM_0010 0 "SelectNoSelect_Select" 1 "SelectNoSelect_NoSelect" ;
VAL_ 150 FirstRowRiDefdMassgProgCfgM_0011 0 "SelectNoSelect_Select" 1 "SelectNoSelect_NoSelect" ;
VAL_ 150 FirstRowRiDefdMassgProgCfgM_0012 0 "SelectNoSelect_Select" 1 "SelectNoSelect_NoSelect" ;
VAL_ 150 FirstRowRiDefdMassgProgCfgM_0013 0 "SelectNoSelect_Select" 1 "SelectNoSelect_NoSelect" ;
VAL_ 150 FirstRowRiDefdMassgProgCfgM_0014 0 "SelectNoSelect_Select" 1 "SelectNoSelect_NoSelect" ;
VAL_ 150 FirstRowRiDefdMassgProgCfgMassgF 0 "SelectLvl_Idle" 1 "SelectLvl_Level1" 2 "SelectLvl_Level2" 3 "SelectLvl_Level3" ;
VAL_ 150 FirstRowRiDefdMassgProgCfgMassgI 0 "SelectLvl_Idle" 1 "SelectLvl_Level1" 2 "SelectLvl_Level2" 3 "SelectLvl_Level3" ;
VAL_ 150 FirstRowRiDefdMassgProgCfgM_0015 0 "ProgEdit_Idle" 1 "ProgEdit_Edit" 2 "ProgEdit_Remove" 3 "ProgEdit_Save" ;
VAL_ 528 CoolgLoadGroupCoolgLimd 0 "Flg1_Rst" 1 "Flg1_Set" ;
VAL_ 528 EngTQf 0 "Qf1_DevOfDataUndefd" 1 "Qf1_DataTmpUndefdAndEvlnInProgs" 2 "Qf1_DevOfDataNotWithinRngAllwd" 3 "Qf1_DataCalcdWithDevDefd" ;
VAL_ 528 HvPwrEgyPrio 0 "HvPwrEgyPrio_Standby" 1 "HvPwrEgyPrio_Dischrgning" 2 "HvPwrEgyPrio_Chrgning" 3 "HvPwrEgyPrio_ClimaWithAc" 4 "HvPwrEgyPrio_ClimaWithoutAc" 5 "HvPwrEgyPrio_RemoteClimatisaiton" ;
VAL_ 528 MirrDefrstAtDrvrCmd 0 "OnOff1_Off" 1 "OnOff1_On" ;
VAL_ 528 MirrDefrstAtPassCmd 0 "OnOff1_Off" 1 "OnOff1_On" ;
VAL_ 528 PassSeatSts 0 "PassSeatSts1_Empty" 1 "PassSeatSts1_Fmale" 2 "PassSeatSts1_OccptLrg" 3 "PassSeatSts1_Ukwn" ;
VAL_ 528 SeatDispBtnPsdDrvrSeatDispBtnPsd 0 "Boolean_FALSE" 1 "Boolean_TRUE" ;
VAL_ 528 SeatDispBtnPsdPassSeatDispBtnPsd 0 "Boolean_FALSE" 1 "Boolean_TRUE" ;
VAL_ 528 SeatOccptAtRowSecLe 0 "PassSeatSts1_Empty" 1 "PassSeatSts1_Fmale" 2 "PassSeatSts1_OccptLrg" 3 "PassSeatSts1_Ukwn" ;
VAL_ 528 SeatOccptAtRowSecRi 0 "PassSeatSts1_Empty" 1 "PassSeatSts1_Fmale" 2 "PassSeatSts1_OccptLrg" 3 "PassSeatSts1_Ukwn" ;
VAL_ 298 DoorsOpenerReqDrvr 0 "DoorOpenerIdle" 1 "DoorOpenerOpen" 2 "DoorOpenerCls" 3 "DoorOpenerStop" ;
VAL_ 298 DoorsOpenerReqLeRe 0 "DoorOpenerIdle" 1 "DoorOpenerOpen" 2 "DoorOpenerCls" 3 "DoorOpenerStop" ;
VAL_ 298 DoorsOpenerReqPass 0 "DoorOpenerIdle" 1 "DoorOpenerOpen" 2 "DoorOpenerCls" 3 "DoorOpenerStop" ;
VAL_ 298 DoorsOpenerReqRiRe 0 "DoorOpenerIdle" 1 "DoorOpenerOpen" 2 "DoorOpenerCls" 3 "DoorOpenerStop" ;
VAL_ 298 DoorsOpenerReqTrigSrcDrvr 0 "NoTrigSrc" 1 "KeyRem" 2 "HMI" 3 "Telm" 4 "OutdSwt" 5 "InsdSwt" ;
VAL_ 298 DoorsOpenerReqTrigSrcLeRe 0 "NoTrigSrc" 1 "KeyRem" 2 "HMI" 3 "Telm" 4 "OutdSwt" 5 "InsdSwt" ;
VAL_ 298 DoorsOpenerReqTrigSrcPass 0 "NoTrigSrc" 1 "KeyRem" 2 "HMI" 3 "Telm" 4 "OutdSwt" 5 "InsdSwt" ;
VAL_ 298 DoorsOpenerReqTrigSrcRiRe 0 "NoTrigSrc" 1 "KeyRem" 2 "HMI" 3 "Telm" 4 "OutdSwt" 5 "InsdSwt" ;
VAL_ 298 DoorsOpenerReqVehMtnSts 0 "Boolean_FALSE" 1 "Boolean_TRUE" ;
VAL_ 298 SecRowRiDefdMassgProgCfgMassgBag 0 "SelectNoSelect_Select" 1 "SelectNoSelect_NoSelect" ;
VAL_ 298 SecRowRiDefdMassgProgCfgMas_0000 0 "SelectNoSelect_Select" 1 "SelectNoSelect_NoSelect" ;
VAL_ 298 SecRowRiDefdMassgProgCfgMas_0001 0 "SelectNoSelect_Select" 1 "SelectNoSelect_NoSelect" ;
VAL_ 298 SecRowRiDefdMassgProgCfgMas_0002 0 "SelectNoSelect_Select" 1 "SelectNoSelect_NoSelect" ;
VAL_ 298 SecRowRiDefdMassgProgCfgMas_0003 0 "SelectNoSelect_Select" 1 "SelectNoSelect_NoSelect" ;
VAL_ 298 SecRowRiDefdMassgProgCfgMas_0004 0 "SelectNoSelect_Select" 1 "SelectNoSelect_NoSelect" ;
VAL_ 298 SecRowRiDefdMassgProgCfgMas_0005 0 "SelectNoSelect_Select" 1 "SelectNoSelect_NoSelect" ;
VAL_ 298 SecRowRiDefdMassgProgCfgMas_0006 0 "SelectNoSelect_Select" 1 "SelectNoSelect_NoSelect" ;
VAL_ 298 SecRowRiDefdMassgProgCfgMas_0007 0 "SelectNoSelect_Select" 1 "SelectNoSelect_NoSelect" ;
VAL_ 298 SecRowRiDefdMassgProgCfgMas_0008 0 "SelectNoSelect_Select" 1 "SelectNoSelect_NoSelect" ;
VAL_ 298 SecRowRiDefdMassgProgCfgMas_0009 0 "SelectNoSelect_Select" 1 "SelectNoSelect_NoSelect" ;
VAL_ 298 SecRowRiDefdMassgProgCfgMas_0010 0 "SelectNoSelect_Select" 1 "SelectNoSelect_NoSelect" ;
VAL_ 298 SecRowRiDefdMassgProgCfgMas_0011 0 "SelectNoSelect_Select" 1 "SelectNoSelect_NoSelect" ;
VAL_ 298 SecRowRiDefdMassgProgCfgMas_0012 0 "SelectNoSelect_Select" 1 "SelectNoSelect_NoSelect" ;
VAL_ 298 SecRowRiDefdMassgProgCfgMas_0013 0 "SelectNoSelect_Select" 1 "SelectNoSelect_NoSelect" ;
VAL_ 298 SecRowRiDefdMassgProgCfgMas_0014 0 "SelectNoSelect_Select" 1 "SelectNoSelect_NoSelect" ;
VAL_ 298 SecRowRiDefdMassgProgCfgMassgFrq 0 "SelectLvl_Idle" 1 "SelectLvl_Level1" 2 "SelectLvl_Level2" 3 "SelectLvl_Level3" ;
VAL_ 298 SecRowRiDefdMassgProgCfgMassgInt 0 "SelectLvl_Idle" 1 "SelectLvl_Level1" 2 "SelectLvl_Level2" 3 "SelectLvl_Level3" ;
VAL_ 298 SecRowRiDefdMassgProgCfgMas_0015 0 "ProgEdit_Idle" 1 "ProgEdit_Edit" 2 "ProgEdit_Remove" 3 "ProgEdit_Save" ;
VAL_ 656 CnctSrvFragLvlReq 0 "LvlOff" 1 "Lvl1" 2 "Lvl2" 3 "Lvl3" ;
VAL_ 768 DrvModReq 0 "DrvModReqType1_Undefd" 1 "DrvModReqType1_ECO" 2 "DrvModReqType1_Comfort_Normal" 3 "DrvModReqType1_Dynamic_Sport" 4 "DrvModReqType1_Individual" 5 "DrvModReqType1_Offroad_CrossTerrain" 6 "DrvModReqType1_Adaptive" 7 "DrvModReqType1_Race" 8 "DrvModReqType1_Pure_EV" 9 "DrvModReqType1_Hybrid" 10 "DrvModReqType1_Power" 11 "DrvModReqType1_Snow" 12 "DrvModReqType1_Sand" 13 "DrvModReqType1_Mud" 14 "DrvModReqType1_Rock" 15 "DrvModReqType1_Err" ;
VAL_ 784 CamStsCamCamFrntCalNotCmpl 0 "NoYes1_No" 1 "NoYes1_Yes" ;
VAL_ 784 CamStsCamCamHeatrActv 0 "NoYes1_No" 1 "NoYes1_Yes" ;
VAL_ 784 CamStsCamFrntBlkd1 0 "NoYes1_No" 1 "NoYes1_Yes" ;
VAL_ 784 CamStsCamFrntBlkd2 0 "NoYes1_No" 1 "NoYes1_Yes" ;
VAL_ 784 CamStsCamFrntBlkd3 0 "NoYes1_No" 1 "NoYes1_Yes" ;
VAL_ 784 CamStsCamFrntBlkd4 0 "NoYes1_No" 1 "NoYes1_Yes" ;
VAL_ 784 CamStsCamFrntBlkd5 0 "NoYes1_No" 1 "NoYes1_Yes" ;
VAL_ 784 CamStsCamFrntBlkd6 0 "NoYes1_No" 1 "NoYes1_Yes" ;
VAL_ 784 CamStsCamFrntBlkd7 0 "NoYes1_No" 1 "NoYes1_Yes" ;
VAL_ 784 CamStsCamFrntBlkd8 0 "NoYes1_No" 1 "NoYes1_Yes" ;
VAL_ 784 CamStsCamFrntCalNotStrtd 0 "NoYes1_No" 1 "NoYes1_Yes" ;
VAL_ 784 CamStsCamFrontEna 0 "NoYes1_No" 1 "NoYes1_Yes" ;
VAL_ 784 CamStsCamMissCom 0 "NoYes1_No" 1 "NoYes1_Yes" ;
VAL_ 464 RoadInclnQly 0 "Qly2_Flt" 1 "Qly2_NoInfo" 2 "Qly2_Vld" ;
VAL_ 464 SeatOccptAtRowSecMid 0 "PassSeatSts1_Empty" 1 "PassSeatSts1_Fmale" 2 "PassSeatSts1_OccptLrg" 3 "PassSeatSts1_Ukwn" ;
VAL_ 464 SunCurtPosnSts 0 "WinAndRoofAndCurtPosnTyp_PosnUkwn" 1 "WinAndRoofAndCurtPosnTyp_ClsFull" 2 "WinAndRoofAndCurtPosnTyp_PercOpen4" 3 "WinAndRoofAndCurtPosnTyp_PercOpen8" 4 "WinAndRoofAndCurtPosnTyp_PercOpen12" 5 "WinAndRoofAndCurtPosnTyp_PercOpen16" 6 "WinAndRoofAndCurtPosnTyp_PercOpen20" 7 "WinAndRoofAndCurtPosnTyp_PercOpen24" 8 "WinAndRoofAndCurtPosnTyp_PercOpen28" 9 "WinAndRoofAndCurtPosnTyp_PercOpen32" 10 "WinAndRoofAndCurtPosnTyp_PercOpen36" 11 "WinAndRoofAndCurtPosnTyp_PercOpen40" 12 "WinAndRoofAndCurtPosnTyp_PercOpen44" 13 "WinAndRoofAndCurtPosnTyp_PercOpen48" 14 "WinAndRoofAndCurtPosnTyp_PercOpen52" 15 "WinAndRoofAndCurtPosnTyp_PercOpen56" 16 "WinAndRoofAndCurtPosnTyp_PercOpen60" 17 "WinAndRoofAndCurtPosnTyp_PercOpen64" 18 "WinAndRoofAndCurtPosnTyp_PercOpen68" 19 "WinAndRoofAndCurtPosnTyp_PercOpen72" 20 "WinAndRoofAndCurtPosnTyp_PercOpen76" 21 "WinAndRoofAndCurtPosnTyp_PercOpen80" 22 "WinAndRoofAndCurtPosnTyp_PercOpen84" 23 "WinAndRoofAndCurtPosnTyp_PercOpen88" 24 "WinAndRoofAndCurtPosnTyp_PercOpen92" 25 "WinAndRoofAndCurtPosnTyp_PercOpen96" 26 "WinAndRoofAndCurtPosnTyp_OpenFull" 27 "WinAndRoofAndCurtPosnTyp_Resd1" 28 "WinAndRoofAndCurtPosnTyp_Resd2" 29 "WinAndRoofAndCurtPosnTyp_Resd3" 30 "WinAndRoofAndCurtPosnTyp_Resd4" 31 "WinAndRoofAndCurtPosnTyp_Movg" ;
VAL_ 464 SunRoofPosnSts 0 "WinAndRoofAndCurtPosnTyp_PosnUkwn" 1 "WinAndRoofAndCurtPosnTyp_ClsFull" 2 "WinAndRoofAndCurtPosnTyp_PercOpen4" 3 "WinAndRoofAndCurtPosnTyp_PercOpen8" 4 "WinAndRoofAndCurtPosnTyp_PercOpen12" 5 "WinAndRoofAndCurtPosnTyp_PercOpen16" 6 "WinAndRoofAndCurtPosnTyp_PercOpen20" 7 "WinAndRoofAndCurtPosnTyp_PercOpen24" 8 "WinAndRoofAndCurtPosnTyp_PercOpen28" 9 "WinAndRoofAndCurtPosnTyp_PercOpen32" 10 "WinAndRoofAndCurtPosnTyp_PercOpen36" 11 "WinAndRoofAndCurtPosnTyp_PercOpen40" 12 "WinAndRoofAndCurtPosnTyp_PercOpen44" 13 "WinAndRoofAndCurtPosnTyp_PercOpen48" 14 "WinAndRoofAndCurtPosnTyp_PercOpen52" 15 "WinAndRoofAndCurtPosnTyp_PercOpen56" 16 "WinAndRoofAndCurtPosnTyp_PercOpen60" 17 "WinAndRoofAndCurtPosnTyp_PercOpen64" 18 "WinAndRoofAndCurtPosnTyp_PercOpen68" 19 "WinAndRoofAndCurtPosnTyp_PercOpen72" 20 "WinAndRoofAndCurtPosnTyp_PercOpen76" 21 "WinAndRoofAndCurtPosnTyp_PercOpen80" 22 "WinAndRoofAndCurtPosnTyp_PercOpen84" 23 "WinAndRoofAndCurtPosnTyp_PercOpen88" 24 "WinAndRoofAndCurtPosnTyp_PercOpen92" 25 "WinAndRoofAndCurtPosnTyp_PercOpen96" 26 "WinAndRoofAndCurtPosnTyp_OpenFull" 27 "WinAndRoofAndCurtPosnTyp_Resd1" 28 "WinAndRoofAndCurtPosnTyp_Resd2" 29 "WinAndRoofAndCurtPosnTyp_Resd3" 30 "WinAndRoofAndCurtPosnTyp_Resd4" 31 "WinAndRoofAndCurtPosnTyp_Movg" ;
VAL_ 464 WipgInfoWipgSpdInfo 0 "WipgSpdInfo_Off" 1 "WipgSpdInfo_IntlLo" 2 "WipgSpdInfo_IntlHi" 3 "WipgSpdInfo_WipgSpd4045" 4 "WipgSpdInfo_WipgSpd4650" 5 "WipgSpdInfo_WipgSpd5155" 6 "WipgSpdInfo_WipgSpd5660" 7 "WipgSpdInfo_WiprErr" ;
VAL_ 464 WipgInfoWiprActv 0 "OnOff1_Off" 1 "OnOff1_On" ;
VAL_ 464 WipgInfoWiprInWipgAr 0 "OnOff1_Off" 1 "OnOff1_On" ;
VAL_ 880 EngSt1WdStsEngSt1WdSts 0 "EngSt1_Ini" 1 "EngSt1_Awake" 2 "EngSt1_Rdy" 3 "EngSt1_PreStrtg" 4 "EngSt1_StrtgInProgs" 5 "EngSt1_RunngRunng" 6 "EngSt1_RunngStb" 7 "EngSt1_RunngStrtgInProgs" 8 "EngSt1_RunngRemStrtd" 9 "EngSt1_AftRun" ;
VAL_ 896 DoorLeReIntrSwtLedLockgCmd 0 "OnOff1_Off" 1 "OnOff1_On" ;
VAL_ 896 DoorRiReIntrSwtLedLockgCmd 0 "OnOff1_Off" 1 "OnOff1_On" ;
VAL_ 816 ProfPenSts1 0 "IdPen_ProfUkwn" 1 "IdPen_Prof1" 2 "IdPen_Prof2" 3 "IdPen_Prof3" 4 "IdPen_Prof4" 5 "IdPen_Prof5" 6 "IdPen_Prof6" 7 "IdPen_Prof7" 8 "IdPen_Prof8" 9 "IdPen_Prof9" 10 "IdPen_Prof10" 11 "IdPen_Prof11" 12 "IdPen_Prof12" 13 "IdPen_Prof13" 14 "IdPen_Resd14" 15 "IdPen_ProfAll" ;
VAL_ 816 SecRowLeDefdMassgProgSeln 0 "ProgSeln_Dft" 1 "ProgSeln_Defd" ;
VAL_ 816 SecRowRiDefdMassgProgSeln 0 "ProgSeln_Dft" 1 "ProgSeln_Defd" ;
VAL_ 816 VehBattUSysUQf 0 "GenQf1_UndefindDataAccur" 1 "GenQf1_TmpUndefdData" 2 "GenQf1_DataAccurNotWithinSpcn" 3 "GenQf1_AccurData" ;
VAL_ 849 HmiPopUpResp 0 "BookChargeSetResponse_Default" 1 "BookChargeSetResponse_Success" 2 "BookChargeSetResponse_Cancelled" 3 "BookChargeSetResponse_Fail" ;
VAL_ 849 VFCInfoEna 0 "EnableDisableCoding_Disabled" 1 "EnableDisableCoding_Enabled" ;
VAL_ 128 AmbLiMusicShowTypAmbLiShowTyp 0 "AmbLiShowTyp_Idle" 1 "AmbLiShowTyp_Passionate" 2 "AmbLiShowTyp_Normal" 3 "AmbLiShowTyp_Subdued" ;
VAL_ 128 AmbLiMusicShowTypIdPen 0 "IdPen_ProfUkwn" 1 "IdPen_Prof1" 2 "IdPen_Prof2" 3 "IdPen_Prof3" 4 "IdPen_Prof4" 5 "IdPen_Prof5" 6 "IdPen_Prof6" 7 "IdPen_Prof7" 8 "IdPen_Prof8" 9 "IdPen_Prof9" 10 "IdPen_Prof10" 11 "IdPen_Prof11" 12 "IdPen_Prof12" 13 "IdPen_Prof13" 14 "IdPen_Resd14" 15 "IdPen_ProfAll" ;
VAL_ 128 AmbLiWelcomeShowTypAmbLiShowTyp 0 "AmbLiShowTyp_Idle" 1 "AmbLiShowTyp_Passionate" 2 "AmbLiShowTyp_Normal" 3 "AmbLiShowTyp_Subdued" ;
VAL_ 128 AmbLiWelcomeShowTypIdPen 0 "IdPen_ProfUkwn" 1 "IdPen_Prof1" 2 "IdPen_Prof2" 3 "IdPen_Prof3" 4 "IdPen_Prof4" 5 "IdPen_Prof5" 6 "IdPen_Prof6" 7 "IdPen_Prof7" 8 "IdPen_Prof8" 9 "IdPen_Prof9" 10 "IdPen_Prof10" 11 "IdPen_Prof11" 12 "IdPen_Prof12" 13 "IdPen_Prof13" 14 "IdPen_Resd14" 15 "IdPen_ProfAll" ;
VAL_ 128 VehADModeActReq 0 "Primary" 1 "Secondary" ;
VAL_ 128 VehADModeReq 0 "ADReq_Init" 1 "ADReq_Mode1" 2 "ADReq_Mode2" 3 "ADReq_Mode3" 4 "ADReq_Reserved" ;
VAL_ 928 HmiAutDefrstEna 0 "OnOff1_Off" 1 "OnOff1_On" ;
VAL_ 928 HmiAutDefrstReq 0 "OnOff1_Off" 1 "OnOff1_On" ;
VAL_ 928 HmiClimaFrntAutReq 0 "OnOff1_Off" 1 "OnOff1_On" ;
VAL_ 928 HmiClimaReAutReq 0 "OnOff1_Off" 1 "OnOff1_On" ;
VAL_ 928 HmiCmptmtAirDistbnFrntLe 0 "HmiCmptmtAirDistbnFrnt_Flr" 1 "HmiCmptmtAirDistbnFrnt_Vent" 2 "HmiCmptmtAirDistbnFrnt_Defrst" 3 "HmiCmptmtAirDistbnFrnt_FlrDefrst" 4 "HmiCmptmtAirDistbnFrnt_FlrVent" 5 "HmiCmptmtAirDistbnFrnt_VentDefrst" 6 "HmiCmptmtAirDistbnFrnt_FlrVentDefrst" 7 "HmiCmptmtAirDistbnFrnt_Aut" ;
VAL_ 928 HmiCmptmtAirDistbnFrntRi 0 "HmiCmptmtAirDistbnFrnt_Flr" 1 "HmiCmptmtAirDistbnFrnt_Vent" 2 "HmiCmptmtAirDistbnFrnt_Defrst" 3 "HmiCmptmtAirDistbnFrnt_FlrDefrst" 4 "HmiCmptmtAirDistbnFrnt_FlrVent" 5 "HmiCmptmtAirDistbnFrnt_VentDefrst" 6 "HmiCmptmtAirDistbnFrnt_FlrVentDefrst" 7 "HmiCmptmtAirDistbnFrnt_Aut" ;
VAL_ 928 HmiCmptmtAirDistbnRe 0 "HmiCmptmtAirDistbnFrnt_Flr" 1 "HmiCmptmtAirDistbnFrnt_Vent" 2 "HmiCmptmtAirDistbnFrnt_Defrst" 3 "HmiCmptmtAirDistbnFrnt_FlrDefrst" 4 "HmiCmptmtAirDistbnFrnt_FlrVent" 5 "HmiCmptmtAirDistbnFrnt_VentDefrst" 6 "HmiCmptmtAirDistbnFrnt_FlrVentDefrst" 7 "HmiCmptmtAirDistbnFrnt_Aut" ;
VAL_ 928 HmiElecAirDirModReqDrvrMod 0 "AirDirModReq_Normal" 1 "AirDirModReq_Focus" 2 "AirDirModReq_Avoid" 3 "AirDirModReq_Customize" ;
VAL_ 928 HmiElecAirDirModReqPassMod 0 "AirDirModReq_Normal" 1 "AirDirModReq_Focus" 2 "AirDirModReq_Avoid" 3 "AirDirModReq_Customize" ;
VAL_ 928 HmiElecAirSwngReqDrvrLeRiSwng 0 "OnOff1_Off" 1 "OnOff1_On" ;
VAL_ 928 HmiElecAirSwngReqDrvrUpOnSwng 0 "OnOff1_Off" 1 "OnOff1_On" ;
VAL_ 928 HmiElecAirSwngReqPassLeRiSwng 0 "OnOff1_Off" 1 "OnOff1_On" ;
VAL_ 928 HmiElecAirSwngReqPassUpOnSwng 0 "OnOff1_Off" 1 "OnOff1_On" ;
VAL_ 928 HmiFragraLvlReq 0 "LvlOff" 1 "Lvl1" 2 "Lvl2" 3 "Lvl3" ;
VAL_ 928 HmiFragraModReq 0 "HmiFragraModReq_Single" 1 "HmiFragraModReq_Mix" 2 "HmiFragraModReq_Scene" 3 "HmiFragraModReq_Reserve" ;
VAL_ 928 HmiHumCtrlEna 0 "OnOff1_Off" 1 "OnOff1_On" ;
VAL_ 928 IncomingCO2CtrlFromHmi 0 "OnOff1_Off" 1 "OnOff1_On" ;
VAL_ 928 SecRowLeSeatDispMassgFctMassgInt 0 "MassgIntenLvl_IntenLo" 1 "MassgIntenLvl_IntenNorm" 2 "MassgIntenLvl_IntenHi" 3 "MassgIntenLvl_Off" ;
VAL_ 928 SecRowLeSeatDispMassgFctMassgPro 0 "MassgProgTyp_Prog1" 1 "MassgProgTyp_Prog2" 2 "MassgProgTyp_Prog3" 3 "MassgProgTyp_Prog4" 4 "MassgProgTyp_Prog5" 5 "MassgProgTyp_Prog6" 6 "MassgProgTyp_Prog7" 7 "MassgProgTyp_Prog8" ;
VAL_ 928 SecRowLeSeatDispMassgFctOnOff 0 "OnOff1_Off" 1 "OnOff1_On" ;
VAL_ 645 BookTrvlClimaActvReq 0 "OnOffNoReq_NoReq" 1 "OnOffNoReq_On" 2 "OnOffNoReq_Off" ;
VAL_ 645 ClimaTmrStsTelmRqrd 0 "OnOff1_Off" 1 "OnOff1_On" ;
VAL_ 645 IntelliClimaReq 0 "CmptSts_NoRequest" 1 "CmptSts_CoolingRequest" 2 "CmptSts_HeatingRequest" 3 "CmptSts_CoolingAndHeatingRequest" 4 "CmptSts_PostHeating" ;
VAL_ 645 RemVentReq 0 "OnOffNoReq_NoReq" 1 "OnOffNoReq_On" 2 "OnOffNoReq_Off" ;
VAL_ 645 SeatHeatDurgClimaEnadFromTelm 0 "SeatHeatDurgClimaEnad2_SeatHeatOff" 1 "SeatHeatDurgClimaEnad2_SeatDrvOn" 2 "SeatHeatDurgClimaEnad2_SeatPassOn" 3 "SeatHeatDurgClimaEnad2_SeatDrvrAndPass" 4 "SeatHeatDurgClimaEnad2_SeatLeftRearOn" 5 "SeatHeatDurgClimaEnad2_SeatRightRearOn" ;
VAL_ 645 SteerWhlHeatgDurgClimaEnadFromTe 0 "OnOff1_Off" 1 "OnOff1_On" ;
VAL_ 645 TelmClimaReq 0 "OnOffNoReq_NoReq" 1 "OnOffNoReq_On" 2 "OnOffNoReq_Off" ;
VAL_ 645 TelmClimaTSetHmiCmptmtTSpSpcl 0 "HmiCmptmtTSpSpcl_Norm" 1 "HmiCmptmtTSpSpcl_Lo" 2 "HmiCmptmtTSpSpcl_Hi" ;
VAL_ 645 TelmSeatPassVentnClimaLvl 0 "TelmSeatClimaLvl_off" 1 "TelmSeatClimaLvl_Lvl1" 2 "TelmSeatClimaLvl_Lvl2" 3 "TelmSeatClimaLvl_Lvl3" ;
VAL_ 645 TelmSeatSecLeHeatClimaLvl 0 "TelmSeatClimaLvl_off" 1 "TelmSeatClimaLvl_Lvl1" 2 "TelmSeatClimaLvl_Lvl2" 3 "TelmSeatClimaLvl_Lvl3" ;
VAL_ 645 TelmSeatSecLeVentnClimaLvl 0 "TelmSeatClimaLvl_off" 1 "TelmSeatClimaLvl_Lvl1" 2 "TelmSeatClimaLvl_Lvl2" 3 "TelmSeatClimaLvl_Lvl3" ;
VAL_ 645 TelmSeatSecRiHeatClimaLvl 0 "TelmSeatClimaLvl_off" 1 "TelmSeatClimaLvl_Lvl1" 2 "TelmSeatClimaLvl_Lvl2" 3 "TelmSeatClimaLvl_Lvl3" ;
VAL_ 645 TelmSeatSecRiVentnClimaLvl 0 "TelmSeatClimaLvl_off" 1 "TelmSeatClimaLvl_Lvl1" 2 "TelmSeatClimaLvl_Lvl2" 3 "TelmSeatClimaLvl_Lvl3" ;
VAL_ 855 ClimaRqrd1 0 "OnOffNoReq_NoReq" 1 "OnOffNoReq_On" 2 "OnOffNoReq_Off" ;
VAL_ 855 HMIClimaEgySaveReq 0 "VentnActr01BlckInd_Disabled" 1 "VentnActr01BlckInd_Enabled" 2 "VentnActr01BlckInd_Reserved" 3 "VentnActr01BlckInd_Signalinvalid" ;
VAL_ 855 HmiEcoClimaSetgIdPen 0 "IdPen_ProfUkwn" 1 "IdPen_Prof1" 2 "IdPen_Prof2" 3 "IdPen_Prof3" 4 "IdPen_Prof4" 5 "IdPen_Prof5" 6 "IdPen_Prof6" 7 "IdPen_Prof7" 8 "IdPen_Prof8" 9 "IdPen_Prof9" 10 "IdPen_Prof10" 11 "IdPen_Prof11" 12 "IdPen_Prof12" 13 "IdPen_Prof13" 14 "IdPen_Resd14" 15 "IdPen_ProfAll" ;
VAL_ 855 HmiEcoClimaSetgOnOff1 0 "OnOff1_Off" 1 "OnOff1_On" ;
VAL_ 855 ReqFragLvlTelm 0 "ReqFragLvl_OFF" 1 "ReqFragLvl_Level1" 2 "ReqFragLvl_Level2" 3 "ReqFragLvl_Level3" ;
VAL_ 855 TelmAirFragTasteReq 0 "TelmAirFragChReq_NoReq" 1 "TelmAirFragChReq_Ch1" 2 "TelmAirFragChReq_Ch2" 3 "TelmAirFragChReq_Ch3" 4 "TelmAirFragChReq_Ch4" 5 "TelmAirFragChReq_Ch5" ;
VAL_ 855 TelmPM25Req 0 "ReqSts1_NotReqd" 1 "ReqSts1_Reqd" ;
VAL_ 855 TelmSeatDrvHeatClimaLvl 0 "TelmSeatClimaLvl_off" 1 "TelmSeatClimaLvl_Lvl1" 2 "TelmSeatClimaLvl_Lvl2" 3 "TelmSeatClimaLvl_Lvl3" ;
VAL_ 855 TelmSeatDrvVentnClimaLvl 0 "TelmSeatClimaLvl_off" 1 "TelmSeatClimaLvl_Lvl1" 2 "TelmSeatClimaLvl_Lvl2" 3 "TelmSeatClimaLvl_Lvl3" ;
VAL_ 855 TelmSeatPassHeatClimaLvl 0 "TelmSeatClimaLvl_off" 1 "TelmSeatClimaLvl_Lvl1" 2 "TelmSeatClimaLvl_Lvl2" 3 "TelmSeatClimaLvl_Lvl3" ;
VAL_ 951 HmiMaxACReq 0 "OnOff1_Off" 1 "OnOff1_On" ;
VAL_ 951 HvBattClimReq 0 "Boolean_FALSE" 1 "Boolean_TRUE" ;
VAL_ 151 BackRestSideSpprtAdjmtRowFirstDr 0 "SwtHozlSts1_Idle" 1 "SwtHozlSts1_Fwd" 2 "SwtHozlSts1_Backw" ;
VAL_ 151 BackRestSideSpprtAdjmtRowFirstPa 0 "SwtHozlSts1_Idle" 1 "SwtHozlSts1_Fwd" 2 "SwtHozlSts1_Backw" ;
VAL_ 151 EasyInOutSecRowLeActv 0 "Boolean_FALSE" 1 "Boolean_TRUE" ;
VAL_ 151 EasyInOutSecRowLeReq 0 "OnOff1_Off" 1 "OnOff1_On" ;
VAL_ 151 EasyInOutSecRowRiActv 0 "Boolean_FALSE" 1 "Boolean_TRUE" ;
VAL_ 151 EasyInOutSecRowRiReq 0 "OnOff1_Off" 1 "OnOff1_On" ;
VAL_ 151 LumHeiAdjmtRowFirstDrvr 0 "SwtVertSts1_Idle" 1 "SwtVertSts1_Up" 2 "SwtVertSts1_Dwn" ;
VAL_ 151 LumHeiAdjmtRowFirstPass 0 "SwtVertSts1_Idle" 1 "SwtVertSts1_Up" 2 "SwtVertSts1_Dwn" ;
VAL_ 151 LumLenAdjmtRowFirstDrvr 0 "SwtHozlSts1_Idle" 1 "SwtHozlSts1_Fwd" 2 "SwtHozlSts1_Backw" ;
VAL_ 151 LumLenAdjmtRowFirstPass 0 "SwtHozlSts1_Idle" 1 "SwtHozlSts1_Fwd" 2 "SwtHozlSts1_Backw" ;
VAL_ 153 CushExtnFirstDrvr 0 "SwtHozlSts1_Idle" 1 "SwtHozlSts1_Fwd" 2 "SwtHozlSts1_Backw" ;
VAL_ 153 CushExtnFirstPass 0 "SwtHozlSts1_Idle" 1 "SwtHozlSts1_Fwd" 2 "SwtHozlSts1_Backw" ;
VAL_ 153 CushSideSpprtAdjmtRowFirstDrvr 0 "SwtVertSts1_Idle" 1 "SwtVertSts1_Up" 2 "SwtVertSts1_Dwn" ;
VAL_ 153 CushSideSpprtAdjmtRowFirstPass 0 "SwtVertSts1_Idle" 1 "SwtVertSts1_Up" 2 "SwtVertSts1_Dwn" ;
VAL_ 153 HdRestAdjmtRowFirstDrvr 0 "SwtHozlSts1_Idle" 1 "SwtHozlSts1_Fwd" 2 "SwtHozlSts1_Backw" ;
VAL_ 153 HdRestAdjmtRowFirstPass 0 "SwtHozlSts1_Idle" 1 "SwtHozlSts1_Fwd" 2 "SwtHozlSts1_Backw" ;
VAL_ 153 HdRestHeiAdjmtRowFirstDrvr 0 "SwtVertSts1_Idle" 1 "SwtVertSts1_Up" 2 "SwtVertSts1_Dwn" ;
VAL_ 153 HdRestHeiAdjmtRowFirstPass 0 "SwtVertSts1_Idle" 1 "SwtVertSts1_Up" 2 "SwtVertSts1_Dwn" ;
VAL_ 153 HvahFltIndcnReq 0 "Flg1_Rst" 1 "Flg1_Set" ;
VAL_ 153 LumHeiAdjmtSecRowLe 0 "SwtVertSts1_Idle" 1 "SwtVertSts1_Up" 2 "SwtVertSts1_Dwn" ;
VAL_ 153 LumHeiAdjmtSecRowRi 0 "SwtVertSts1_Idle" 1 "SwtVertSts1_Up" 2 "SwtVertSts1_Dwn" ;
VAL_ 153 LumLenAdjmtSecRowLe 0 "SwtHozlSts1_Idle" 1 "SwtHozlSts1_Fwd" 2 "SwtHozlSts1_Backw" ;
VAL_ 153 LumLenAdjmtSecRowRi 0 "SwtHozlSts1_Idle" 1 "SwtHozlSts1_Fwd" 2 "SwtHozlSts1_Backw" ;
VAL_ 153 PassAirbSts 0 "OnOff2_On" 1 "OnOff2_Off" ;
VAL_ 300 LeReDblPullHndlMotRstCmd 0 "OnOffSafe1_OnOffSafeInvld1" 1 "OnOffSafe1_OnOffSafeOn" 2 "OnOffSafe1_OnOffSafeOff" 3 "OnOffSafe1_OnOffSafeInvld2" ;
VAL_ 300 PwrDoorEnaHmiStsPSD 0 "EnableDisableCoding_Disabled" 1 "EnableDisableCoding_Enabled" ;
VAL_ 300 RiReDblPullHndlMotRstCmd 0 "OnOffSafe1_OnOffSafeInvld1" 1 "OnOffSafe1_OnOffSafeOn" 2 "OnOffSafe1_OnOffSafeOff" 3 "OnOffSafe1_OnOffSafeInvld2" ;
VAL_ 447 PostDrvgClimaReq 0 "OnOff1_Off" 1 "OnOff1_On" ;
VAL_ 447 StrtInProgs 0 "StrtInProgs1_StrtStsOff" 1 "StrtInProgs1_StrtStsImminent" 2 "StrtInProgs1_StrtStsStrtng" 3 "StrtInProgs1_StrtStsRunng" ;
VAL_ 570 DCChrgnHndlSts 0 "OnBdChrgrHndlSts_Disconnected" 1 "OnBdChrgrHndlSts_ConnectedWithoutPower" 2 "OnBdChrgrHndlSts_PowerAvailableButNotActivated" 3 "OnBdChrgrHndlSts_ConnectedWithPower" 4 "OnBdChrgrHndlSts_Init" 5 "OnBdChrgrHndlSts_Fault" ;
VAL_ 570 DefrstStsMirrDefrst 0 "ActrDefrstSts_Off" 1 "ActrDefrstSts_On" 2 "ActrDefrstSts_Limited" 3 "ActrDefrstSts_NotAvailable" 4 "ActrDefrstSts_TmrOff" 5 "ActrDefrstSts_AutoCdn" ;
VAL_ 570 DefrstStsWinDefrstFrnt 0 "ActrDefrstSts_Off" 1 "ActrDefrstSts_On" 2 "ActrDefrstSts_Limited" 3 "ActrDefrstSts_NotAvailable" 4 "ActrDefrstSts_TmrOff" 5 "ActrDefrstSts_AutoCdn" ;
VAL_ 570 DefrstStsWinDefrstRe 0 "ActrDefrstSts_Off" 1 "ActrDefrstSts_On" 2 "ActrDefrstSts_Limited" 3 "ActrDefrstSts_NotAvailable" 4 "ActrDefrstSts_TmrOff" 5 "ActrDefrstSts_AutoCdn" ;
VAL_ 570 ReEvapVlvReq 0 "OnOff1_Off" 1 "OnOff1_On" ;
VAL_ 570 WiprFrntSrvModReq 0 "NoActn" 1 "ActvtSrvPosn" 2 "DeActvtSrvPosn" ;
VAL_ 178 BootFoldSwtActv2 0 "Boolean_FALSE" 1 "Boolean_TRUE" ;
VAL_ 178 BootFoldSwtActv3 0 "Boolean_FALSE" 1 "Boolean_TRUE" ;
VAL_ 178 ClimaRqrdFromHmi 0 "OnOffNoReq_NoReq" 1 "OnOffNoReq_On" 2 "OnOffNoReq_Off" ;
VAL_ 178 LVPwrSplyErrSts 0 "PwrSplyErrSts_SysOk" 1 "PwrSplyErrSts_UhiDurgDrvg" 2 "PwrSplyErrSts_UloDurgdrvg" 3 "PwrSplyErrSts_BattRlyFlt" 4 "PwrSplyErrSts_BattSnsrComFlt" 5 "PwrSplyErrSts_BattSnsrHwFlt" 6 "PwrSplyErrSts_FltComDcDc" 7 "PwrSplyErrSts_FltElecDcDc" 8 "PwrSplyErrSts_FltDcDc" 9 "PwrSplyErrSts_SupCptrHwFlt" 10 "PwrSplyErrSts_AltFltMecl" 11 "PwrSplyErrSts_AltFltElec" 12 "PwrSplyErrSts_AltFltT" 13 "PwrSplyErrSts_AltFltCom" 14 "PwrSplyErrSts_SpprtBattFltChrgn" 15 "PwrSplyErrSts_Spare6" ;
VAL_ 178 SecRowLeCmftSet 0 "CmftSet_NoReq" 1 "CmftSet_ComfortReq" 2 "CmftSet_ReturnReq" ;
VAL_ 178 WinOpenDrvrReq 0 "WinAndRoofAndCurtPosnTyp_PosnUkwn" 1 "WinAndRoofAndCurtPosnTyp_ClsFull" 2 "WinAndRoofAndCurtPosnTyp_PercOpen4" 3 "WinAndRoofAndCurtPosnTyp_PercOpen8" 4 "WinAndRoofAndCurtPosnTyp_PercOpen12" 5 "WinAndRoofAndCurtPosnTyp_PercOpen16" 6 "WinAndRoofAndCurtPosnTyp_PercOpen20" 7 "WinAndRoofAndCurtPosnTyp_PercOpen24" 8 "WinAndRoofAndCurtPosnTyp_PercOpen28" 9 "WinAndRoofAndCurtPosnTyp_PercOpen32" 10 "WinAndRoofAndCurtPosnTyp_PercOpen36" 11 "WinAndRoofAndCurtPosnTyp_PercOpen40" 12 "WinAndRoofAndCurtPosnTyp_PercOpen44" 13 "WinAndRoofAndCurtPosnTyp_PercOpen48" 14 "WinAndRoofAndCurtPosnTyp_PercOpen52" 15 "WinAndRoofAndCurtPosnTyp_PercOpen56" 16 "WinAndRoofAndCurtPosnTyp_PercOpen60" 17 "WinAndRoofAndCurtPosnTyp_PercOpen64" 18 "WinAndRoofAndCurtPosnTyp_PercOpen68" 19 "WinAndRoofAndCurtPosnTyp_PercOpen72" 20 "WinAndRoofAndCurtPosnTyp_PercOpen76" 21 "WinAndRoofAndCurtPosnTyp_PercOpen80" 22 "WinAndRoofAndCurtPosnTyp_PercOpen84" 23 "WinAndRoofAndCurtPosnTyp_PercOpen88" 24 "WinAndRoofAndCurtPosnTyp_PercOpen92" 25 "WinAndRoofAndCurtPosnTyp_PercOpen96" 26 "WinAndRoofAndCurtPosnTyp_OpenFull" 27 "WinAndRoofAndCurtPosnTyp_Resd1" 28 "WinAndRoofAndCurtPosnTyp_Resd2" 29 "WinAndRoofAndCurtPosnTyp_Resd3" 30 "WinAndRoofAndCurtPosnTyp_Resd4" 31 "WinAndRoofAndCurtPosnTyp_Movg" ;
VAL_ 178 WinOpenPassReq 0 "WinAndRoofAndCurtPosnTyp_PosnUkwn" 1 "WinAndRoofAndCurtPosnTyp_ClsFull" 2 "WinAndRoofAndCurtPosnTyp_PercOpen4" 3 "WinAndRoofAndCurtPosnTyp_PercOpen8" 4 "WinAndRoofAndCurtPosnTyp_PercOpen12" 5 "WinAndRoofAndCurtPosnTyp_PercOpen16" 6 "WinAndRoofAndCurtPosnTyp_PercOpen20" 7 "WinAndRoofAndCurtPosnTyp_PercOpen24" 8 "WinAndRoofAndCurtPosnTyp_PercOpen28" 9 "WinAndRoofAndCurtPosnTyp_PercOpen32" 10 "WinAndRoofAndCurtPosnTyp_PercOpen36" 11 "WinAndRoofAndCurtPosnTyp_PercOpen40" 12 "WinAndRoofAndCurtPosnTyp_PercOpen44" 13 "WinAndRoofAndCurtPosnTyp_PercOpen48" 14 "WinAndRoofAndCurtPosnTyp_PercOpen52" 15 "WinAndRoofAndCurtPosnTyp_PercOpen56" 16 "WinAndRoofAndCurtPosnTyp_PercOpen60" 17 "WinAndRoofAndCurtPosnTyp_PercOpen64" 18 "WinAndRoofAndCurtPosnTyp_PercOpen68" 19 "WinAndRoofAndCurtPosnTyp_PercOpen72" 20 "WinAndRoofAndCurtPosnTyp_PercOpen76" 21 "WinAndRoofAndCurtPosnTyp_PercOpen80" 22 "WinAndRoofAndCurtPosnTyp_PercOpen84" 23 "WinAndRoofAndCurtPosnTyp_PercOpen88" 24 "WinAndRoofAndCurtPosnTyp_PercOpen92" 25 "WinAndRoofAndCurtPosnTyp_PercOpen96" 26 "WinAndRoofAndCurtPosnTyp_OpenFull" 27 "WinAndRoofAndCurtPosnTyp_Resd1" 28 "WinAndRoofAndCurtPosnTyp_Resd2" 29 "WinAndRoofAndCurtPosnTyp_Resd3" 30 "WinAndRoofAndCurtPosnTyp_Resd4" 31 "WinAndRoofAndCurtPosnTyp_Movg" ;
VAL_ 178 WinOpenReLeReq 0 "WinAndRoofAndCurtPosnTyp_PosnUkwn" 1 "WinAndRoofAndCurtPosnTyp_ClsFull" 2 "WinAndRoofAndCurtPosnTyp_PercOpen4" 3 "WinAndRoofAndCurtPosnTyp_PercOpen8" 4 "WinAndRoofAndCurtPosnTyp_PercOpen12" 5 "WinAndRoofAndCurtPosnTyp_PercOpen16" 6 "WinAndRoofAndCurtPosnTyp_PercOpen20" 7 "WinAndRoofAndCurtPosnTyp_PercOpen24" 8 "WinAndRoofAndCurtPosnTyp_PercOpen28" 9 "WinAndRoofAndCurtPosnTyp_PercOpen32" 10 "WinAndRoofAndCurtPosnTyp_PercOpen36" 11 "WinAndRoofAndCurtPosnTyp_PercOpen40" 12 "WinAndRoofAndCurtPosnTyp_PercOpen44" 13 "WinAndRoofAndCurtPosnTyp_PercOpen48" 14 "WinAndRoofAndCurtPosnTyp_PercOpen52" 15 "WinAndRoofAndCurtPosnTyp_PercOpen56" 16 "WinAndRoofAndCurtPosnTyp_PercOpen60" 17 "WinAndRoofAndCurtPosnTyp_PercOpen64" 18 "WinAndRoofAndCurtPosnTyp_PercOpen68" 19 "WinAndRoofAndCurtPosnTyp_PercOpen72" 20 "WinAndRoofAndCurtPosnTyp_PercOpen76" 21 "WinAndRoofAndCurtPosnTyp_PercOpen80" 22 "WinAndRoofAndCurtPosnTyp_PercOpen84" 23 "WinAndRoofAndCurtPosnTyp_PercOpen88" 24 "WinAndRoofAndCurtPosnTyp_PercOpen92" 25 "WinAndRoofAndCurtPosnTyp_PercOpen96" 26 "WinAndRoofAndCurtPosnTyp_OpenFull" 27 "WinAndRoofAndCurtPosnTyp_Resd1" 28 "WinAndRoofAndCurtPosnTyp_Resd2" 29 "WinAndRoofAndCurtPosnTyp_Resd3" 30 "WinAndRoofAndCurtPosnTyp_Resd4" 31 "WinAndRoofAndCurtPosnTyp_Movg" ;
VAL_ 178 WinOpenReRiReq 0 "WinAndRoofAndCurtPosnTyp_PosnUkwn" 1 "WinAndRoofAndCurtPosnTyp_ClsFull" 2 "WinAndRoofAndCurtPosnTyp_PercOpen4" 3 "WinAndRoofAndCurtPosnTyp_PercOpen8" 4 "WinAndRoofAndCurtPosnTyp_PercOpen12" 5 "WinAndRoofAndCurtPosnTyp_PercOpen16" 6 "WinAndRoofAndCurtPosnTyp_PercOpen20" 7 "WinAndRoofAndCurtPosnTyp_PercOpen24" 8 "WinAndRoofAndCurtPosnTyp_PercOpen28" 9 "WinAndRoofAndCurtPosnTyp_PercOpen32" 10 "WinAndRoofAndCurtPosnTyp_PercOpen36" 11 "WinAndRoofAndCurtPosnTyp_PercOpen40" 12 "WinAndRoofAndCurtPosnTyp_PercOpen44" 13 "WinAndRoofAndCurtPosnTyp_PercOpen48" 14 "WinAndRoofAndCurtPosnTyp_PercOpen52" 15 "WinAndRoofAndCurtPosnTyp_PercOpen56" 16 "WinAndRoofAndCurtPosnTyp_PercOpen60" 17 "WinAndRoofAndCurtPosnTyp_PercOpen64" 18 "WinAndRoofAndCurtPosnTyp_PercOpen68" 19 "WinAndRoofAndCurtPosnTyp_PercOpen72" 20 "WinAndRoofAndCurtPosnTyp_PercOpen76" 21 "WinAndRoofAndCurtPosnTyp_PercOpen80" 22 "WinAndRoofAndCurtPosnTyp_PercOpen84" 23 "WinAndRoofAndCurtPosnTyp_PercOpen88" 24 "WinAndRoofAndCurtPosnTyp_PercOpen92" 25 "WinAndRoofAndCurtPosnTyp_PercOpen96" 26 "WinAndRoofAndCurtPosnTyp_OpenFull" 27 "WinAndRoofAndCurtPosnTyp_Resd1" 28 "WinAndRoofAndCurtPosnTyp_Resd2" 29 "WinAndRoofAndCurtPosnTyp_Resd3" 30 "WinAndRoofAndCurtPosnTyp_Resd4" 31 "WinAndRoofAndCurtPosnTyp_Movg" ;
VAL_ 178 WinVentnOpenReq 0 "OnOff1_Off" 1 "OnOff1_On" ;
VAL_ 196 DoorOpenwarnLeIndcn 0 "LcmaIndcn_NoLcmaWarn" 1 "LcmaIndcn_LcmaWarnLvl1" 2 "LcmaIndcn_NotUsed" 3 "LcmaIndcn_LcmaWarnLvl2" ;
VAL_ 196 DoorOpenwarnRiIndcn 0 "LcmaIndcn_NoLcmaWarn" 1 "LcmaIndcn_LcmaWarnLvl1" 2 "LcmaIndcn_NotUsed" 3 "LcmaIndcn_LcmaWarnLvl2" ;
VAL_ 196 LoadAndStoreReqErgoPosn 0 "MemPosn_ProfPosn" 1 "MemPosn_MemBnk1" 2 "MemPosn_MemBnk2" 3 "MemPosn_MemBnk3" ;
VAL_ 196 LoadAndStoreReqErgoSetgEve 0 "EveMemPosn_Idle" 1 "EveMemPosn_Store" 2 "EveMemPosn_Load" 3 "EveMemPosn_Stop" 4 "EveMemPosn_AutMovmt" 5 "EveMemPosn_Upload" 6 "EveMemPosn_Download" 7 "EveMemPosn_Clear" ;
VAL_ 196 LoadAndStoreReqIdPen 0 "IdPen_ProfUkwn" 1 "IdPen_Prof1" 2 "IdPen_Prof2" 3 "IdPen_Prof3" 4 "IdPen_Prof4" 5 "IdPen_Prof5" 6 "IdPen_Prof6" 7 "IdPen_Prof7" 8 "IdPen_Prof8" 9 "IdPen_Prof9" 10 "IdPen_Prof10" 11 "IdPen_Prof11" 12 "IdPen_Prof12" 13 "IdPen_Prof13" 14 "IdPen_Resd14" 15 "IdPen_ProfAll" ;
VAL_ 196 LoadAndStoreReqInOutEasy 0 "OnOff1_Off" 1 "OnOff1_On" ;
VAL_ 196 RctaIndcnLe 0 "LcmaIndcn_NoLcmaWarn" 1 "LcmaIndcn_LcmaWarnLvl1" 2 "LcmaIndcn_NotUsed" 3 "LcmaIndcn_LcmaWarnLvl2" ;
VAL_ 196 RctaIndcnRi 0 "LcmaIndcn_NoLcmaWarn" 1 "LcmaIndcn_LcmaWarnLvl1" 2 "LcmaIndcn_NotUsed" 3 "LcmaIndcn_LcmaWarnLvl2" ;
VAL_ 196 VehWinSunRoofClsReq 0 "OpenCls3_NoRequest" 1 "OpenCls3_Close" 2 "OpenCls3_Reserved1" 3 "OpenCls3_Reserved2" ;
VAL_ 257 TrlrLampChkAutReqPen 0 "IdPen_ProfUkwn" 1 "IdPen_Prof1" 2 "IdPen_Prof2" 3 "IdPen_Prof3" 4 "IdPen_Prof4" 5 "IdPen_Prof5" 6 "IdPen_Prof6" 7 "IdPen_Prof7" 8 "IdPen_Prof8" 9 "IdPen_Prof9" 10 "IdPen_Prof10" 11 "IdPen_Prof11" 12 "IdPen_Prof12" 13 "IdPen_Prof13" 14 "IdPen_Resd14" 15 "IdPen_ProfAll" ;
VAL_ 257 TrlrLampChkAutReqSts 0 "OnOff1_Off" 1 "OnOff1_On" ;
VAL_ 853 ActvnOfWshrFrntSafe 0 "OnOffCrit1_NotVld1" 1 "OnOffCrit1_Off" 2 "OnOffCrit1_On" 3 "OnOffCrit1_NotVld2" ;
VAL_ 853 StrtRemSts1WdStrtRemSts 0 "StrtRemSts1_Idle" 1 "StrtRemSts1_Strtg" 2 "StrtRemSts1_Actv" ;
VAL_ 152 CbnOverHeatProtnEnaFromTelm 0 "OnOff1_Off" 1 "OnOff1_On" ;
VAL_ 152 DrvrDesDirDrvrDesDir 0 "DrvrDesDir1_Undefd" 1 "DrvrDesDir1_Fwd" 2 "DrvrDesDir1_Rvs" 3 "DrvrDesDir1_Neut" 4 "DrvrDesDir1_Resd0" 5 "DrvrDesDir1_Resd1" 6 "DrvrDesDir1_Resd2" 7 "DrvrDesDir1_Resd3" ;
VAL_ 152 OnBdChrgrSt 0 "ChrgrSts1_Idle" 1 "ChrgrSts1_PreStrt" 2 "ChrgrSts1_Chrgn" 3 "ChrgrSts1_Alrm" 4 "ChrgrSts1_Srv" 5 "ChrgrSts1_Diagc" 6 "ChrgrSts1_Boot" 7 "ChrgrSts1_Rstrt" 8 "ChrgrSts1_DisChrgn" 9 "ChrgrSts1_BookChrgn" 10 "ChrgrSts1_Shutdown" 11 "ChrgrSts1_Heating" 12 "ChrgrSts1_Cooling" ;
VAL_ 152 PassSceneModSeld 0 "PatSeld_NoSeld" 1 "PatSeld_RefrshPatSeld" 2 "PatSeld_ParentchildPatSeld" 3 "PatSeld_Restpatseld" 4 "PatSeld_RomanticPatseld" 5 "PatSeld_StrangerPatseld" 6 "PatSeld_TheaterPatseld" 7 "PatSeld_PetPatseld" 8 "PatSeld_BiochalPatseld" 9 "PatSeld_CarWashPatseld" 10 "PatSeld_EcoPatseld" ;
VAL_ 152 SecRowLeSceneModSeld 0 "PatSeld_NoSeld" 1 "PatSeld_RefrshPatSeld" 2 "PatSeld_ParentchildPatSeld" 3 "PatSeld_Restpatseld" 4 "PatSeld_RomanticPatseld" 5 "PatSeld_StrangerPatseld" 6 "PatSeld_TheaterPatseld" 7 "PatSeld_PetPatseld" 8 "PatSeld_BiochalPatseld" 9 "PatSeld_CarWashPatseld" 10 "PatSeld_EcoPatseld" ;
VAL_ 152 SecRowRiSceneModSeld 0 "PatSeld_NoSeld" 1 "PatSeld_RefrshPatSeld" 2 "PatSeld_ParentchildPatSeld" 3 "PatSeld_Restpatseld" 4 "PatSeld_RomanticPatseld" 5 "PatSeld_StrangerPatseld" 6 "PatSeld_TheaterPatseld" 7 "PatSeld_PetPatseld" 8 "PatSeld_BiochalPatseld" 9 "PatSeld_CarWashPatseld" 10 "PatSeld_EcoPatseld" ;
VAL_ 152 SpeechSts 0 "SpSts1_BeforeWakeUp" 1 "SpSts1_AfterWakeUpLeftRecognizing" 2 "SpSts1_AfterWakeUpRightRecognizing" 3 "SpSts1_AfterWakeUpSpeaking" ;
VAL_ 152 TrRelsReq 0 "OnOffSafe1_OnOffSafeInvld1" 1 "OnOffSafe1_OnOffSafeOn" 2 "OnOffSafe1_OnOffSafeOff" 3 "OnOffSafe1_OnOffSafeInvld2" ;
VAL_ 309 BackRestAdjmtRowFirstDrvr 0 "SwtHozlSts1_Idle" 1 "SwtHozlSts1_Fwd" 2 "SwtHozlSts1_Backw" ;
VAL_ 309 BackRestAdjmtRowFirstPass 0 "SwtHozlSts1_Idle" 1 "SwtHozlSts1_Fwd" 2 "SwtHozlSts1_Backw" ;
VAL_ 309 ClimaBoostAutSetColdAutoOnOff 0 "OnOff1_Off" 1 "OnOff1_On" ;
VAL_ 309 ClimaBoostAutSetHotAutoOnOff 0 "OnOff1_Off" 1 "OnOff1_On" ;
VAL_ 309 ClimaRefreshAutSetActvtOnExit 0 "OnOff1_Off" 1 "OnOff1_On" ;
VAL_ 309 ClimaRefreshAutSetAutoOnOff 0 "AutoOnOff_AutoOff" 1 "AutoOnOff_Approach" 2 "AutoOnOff_DoorOpen" 3 "AutoOnOff_KeyfobActivation" ;
VAL_ 309 ClimaRefreshCmd 0 "ActvnAvl3_Idle" 1 "ActvnAvl3_Actvn" 2 "ActvnAvl3_Deactvn" ;
VAL_ 309 ClimateBoostCmd 0 "ActvnAvl3_Idle" 1 "ActvnAvl3_Actvn" 2 "ActvnAvl3_Deactvn" ;
VAL_ 309 EmgyBrkLiIndcrTurn 0 "OnOffCrit1_NotVld1" 1 "OnOffCrit1_Off" 2 "OnOffCrit1_On" 3 "OnOffCrit1_NotVld2" ;
VAL_ 309 SeatCushTiltAdjmtRowFirstDrvr 0 "SwtVertSts1_Idle" 1 "SwtVertSts1_Up" 2 "SwtVertSts1_Dwn" ;
VAL_ 309 SeatCushTiltAdjmtRowFirstPass 0 "SwtVertSts1_Idle" 1 "SwtVertSts1_Up" 2 "SwtVertSts1_Dwn" ;
VAL_ 309 SeatHeiAdjmtRowFirstDrvr 0 "SwtVertSts1_Idle" 1 "SwtVertSts1_Up" 2 "SwtVertSts1_Dwn" ;
VAL_ 309 SeatHeiAdjmtRowFirstPass 0 "SwtVertSts1_Idle" 1 "SwtVertSts1_Up" 2 "SwtVertSts1_Dwn" ;
VAL_ 309 SeatLenAdjmtRowFirstDrvr 0 "SwtHozlSts1_Idle" 1 "SwtHozlSts1_Fwd" 2 "SwtHozlSts1_Backw" ;
VAL_ 309 SeatLenAdjmtRowFirstPass 0 "SwtHozlSts1_Idle" 1 "SwtHozlSts1_Fwd" 2 "SwtHozlSts1_Backw" ;
VAL_ 180 ActvnOfHndlDoorLiHndlDoorLiDrvr 0 "ApproachLiSetReq_Off" 1 "ApproachLiSetReq_ONStatic" 2 "ApproachLiSetReq_ONDynamic" ;
VAL_ 180 ActvnOfHndlDoorLiHndlDoorLiDrvrR 0 "ApproachLiSetReq_Off" 1 "ApproachLiSetReq_ONStatic" 2 "ApproachLiSetReq_ONDynamic" ;
VAL_ 180 ActvnOfHndlDoorLiHndlDoorLiPass 0 "ApproachLiSetReq_Off" 1 "ApproachLiSetReq_ONStatic" 2 "ApproachLiSetReq_ONDynamic" ;
VAL_ 180 ActvnOfHndlDoorLiHndlDoorLiPassR 0 "ApproachLiSetReq_Off" 1 "ApproachLiSetReq_ONStatic" 2 "ApproachLiSetReq_ONDynamic" ;
VAL_ 180 ActvnOfRoofSwtIllmn 0 "Boolean_FALSE" 1 "Boolean_TRUE" ;
VAL_ 180 MobDevVentReq 0 "PsdNotPsd1_NotPsd" 1 "PsdNotPsd1_Psd" ;
VAL_ 180 SceneModSeld 0 "PatSeld_NoSeld" 1 "PatSeld_RefrshPatSeld" 2 "PatSeld_ParentchildPatSeld" 3 "PatSeld_Restpatseld" 4 "PatSeld_RomanticPatseld" 5 "PatSeld_StrangerPatseld" 6 "PatSeld_TheaterPatseld" 7 "PatSeld_PetPatseld" 8 "PatSeld_BiochalPatseld" 9 "PatSeld_CarWashPatseld" 10 "PatSeld_EcoPatseld" ;
VAL_ 468 ActiveZoneIinfoZone1ONOff 0 "OnOff1_Off" 1 "OnOff1_On" ;
VAL_ 468 ActiveZoneIinfoZone2ONOff 0 "OnOff1_Off" 1 "OnOff1_On" ;
VAL_ 468 ActiveZoneIinfoZone3ONOff 0 "OnOff1_Off" 1 "OnOff1_On" ;
VAL_ 468 CrashStsSafeSts 0 "CrashSts2_NoCrash" 1 "CrashSts2_Crash" ;
VAL_ 468 DrvrSeatDispMassgFctMassgInten 0 "MassgIntenLvl_IntenLo" 1 "MassgIntenLvl_IntenNorm" 2 "MassgIntenLvl_IntenHi" 3 "MassgIntenLvl_Off" ;
VAL_ 468 DrvrSeatDispMassgFctMassgProg 0 "MassgProgTyp_Prog1" 1 "MassgProgTyp_Prog2" 2 "MassgProgTyp_Prog3" 3 "MassgProgTyp_Prog4" 4 "MassgProgTyp_Prog5" 5 "MassgProgTyp_Prog6" 6 "MassgProgTyp_Prog7" 7 "MassgProgTyp_Prog8" ;
VAL_ 468 DrvrSeatDispMassgFctOnOff 0 "OnOff1_Off" 1 "OnOff1_On" ;
VAL_ 468 DrvrSeatDispSpplFct 0 "SeatActvSpplFct1_NotAvl" 1 "SeatActvSpplFct1_LumExtnAndLumHei" 2 "SeatActvSpplFct1_BackBlster" 3 "SeatActvSpplFct1_CushExtn" 4 "SeatActvSpplFct1_HdrestHeiAndHdrestTilt" 5 "SeatActvSpplFct1_MassgFct" 6 "SeatActvSpplFct1_ShoulderFct" 7 "SeatActvSpplFct1_LegrestFct" ;
VAL_ 468 PassSeatDispMassgFctMassgInten 0 "MassgIntenLvl_IntenLo" 1 "MassgIntenLvl_IntenNorm" 2 "MassgIntenLvl_IntenHi" 3 "MassgIntenLvl_Off" ;
VAL_ 468 PassSeatDispMassgFctMassgProg 0 "MassgProgTyp_Prog1" 1 "MassgProgTyp_Prog2" 2 "MassgProgTyp_Prog3" 3 "MassgProgTyp_Prog4" 4 "MassgProgTyp_Prog5" 5 "MassgProgTyp_Prog6" 6 "MassgProgTyp_Prog7" 7 "MassgProgTyp_Prog8" ;
VAL_ 468 PassSeatDispMassgFctOnOff 0 "OnOff1_Off" 1 "OnOff1_On" ;
VAL_ 468 PassSeatDispSpplFct 0 "SeatActvSpplFct1_NotAvl" 1 "SeatActvSpplFct1_LumExtnAndLumHei" 2 "SeatActvSpplFct1_BackBlster" 3 "SeatActvSpplFct1_CushExtn" 4 "SeatActvSpplFct1_HdrestHeiAndHdrestTilt" 5 "SeatActvSpplFct1_MassgFct" 6 "SeatActvSpplFct1_ShoulderFct" 7 "SeatActvSpplFct1_LegrestFct" ;
VAL_ 468 RemStrtHvCtrlReqErsCmd 0 "ErsCmd_ErsCmdNotSet" 1 "ErsCmd_ErsCmdOn" 2 "ErsCmd_ErsCmdOff" ;
VAL_ 958 WinOpenClsGlbReqFromTelmWinOpenC 0 "WinOpenClsGlbReqFromTelm_Idle" 1 "WinOpenClsGlbReqFromTelm_Open" 2 "WinOpenClsGlbReqFromTelm_Close" ;
VAL_ 975 IntelliClimaUsrFanPrefrncEn 0 "VentnActr01BlckInd_Disabled" 1 "VentnActr01BlckInd_Enabled" 2 "VentnActr01BlckInd_Reserved" 3 "VentnActr01BlckInd_Signalinvalid" ;
VAL_ 975 IntelliClimaUsrHumPrefrncEn 0 "VentnActr01BlckInd_Disabled" 1 "VentnActr01BlckInd_Enabled" 2 "VentnActr01BlckInd_Reserved" 3 "VentnActr01BlckInd_Signalinvalid" ;
VAL_ 975 IntelliClimaUsrTPrefrncEn 0 "VentnActr01BlckInd_Disabled" 1 "VentnActr01BlckInd_Enabled" 2 "VentnActr01BlckInd_Reserved" 3 "VentnActr01BlckInd_Signalinvalid" ;
VAL_ 952 HmiHvacRecircLongPsdSts 0 "OnOff1_Off" 1 "OnOff1_On" ;
VAL_ 952 MirrOpenClsReq 0 "MirrFoldCmdTyp_Idle" 1 "MirrFoldCmdTyp_FoldIn" 2 "MirrFoldCmdTyp_FoldOut" ;
VAL_ 952 WinOpenAppReqWinOpenClsGlbSts 0 "WinOpenClsGlbReqFromTelm_Idle" 1 "WinOpenClsGlbReqFromTelm_Open" 2 "WinOpenClsGlbReqFromTelm_Close" ;
SIG_GROUP_ 150 FirstRowLeDefdMassgProgCfg 1 : FirstRowLeDefdMassgProgCfgMassgB FirstRowLeDefdMassgProgCfgM_0000 FirstRowLeDefdMassgProgCfgM_0001 FirstRowLeDefdMassgProgCfgM_0002 FirstRowLeDefdMassgProgCfgM_0003 FirstRowLeDefdMassgProgCfgM_0004 FirstRowLeDefdMassgProgCfgM_0005 FirstRowLeDefdMassgProgCfgM_0006 FirstRowLeDefdMassgProgCfgM_0007 FirstRowLeDefdMassgProgCfgM_0008 FirstRowLeDefdMassgProgCfgM_0009 FirstRowLeDefdMassgProgCfgM_0010 FirstRowLeDefdMassgProgCfgM_0011 FirstRowLeDefdMassgProgCfgM_0012 FirstRowLeDefdMassgProgCfgM_0013 FirstRowLeDefdMassgProgCfgM_0014 FirstRowLeDefdMassgProgCfgMassgF FirstRowLeDefdMassgProgCfgMassgI FirstRowLeDefdMassgProgCfgMassPr FirstRowLeDefdMassgProgCfgM_0015 FirstRowLeDefdMassgProgCfgMassSe;
SIG_GROUP_ 150 FirstRowRiDefdMassgProgCfg 1 : FirstRowRiDefdMassgProgCfgMassgB FirstRowRiDefdMassgProgCfgM_0000 FirstRowRiDefdMassgProgCfgM_0001 FirstRowRiDefdMassgProgCfgM_0002 FirstRowRiDefdMassgProgCfgM_0003 FirstRowRiDefdMassgProgCfgM_0004 FirstRowRiDefdMassgProgCfgM_0005 FirstRowRiDefdMassgProgCfgM_0006 FirstRowRiDefdMassgProgCfgM_0007 FirstRowRiDefdMassgProgCfgM_0008 FirstRowRiDefdMassgProgCfgM_0009 FirstRowRiDefdMassgProgCfgM_0010 FirstRowRiDefdMassgProgCfgM_0011 FirstRowRiDefdMassgProgCfgM_0012 FirstRowRiDefdMassgProgCfgM_0013 FirstRowRiDefdMassgProgCfgM_0014 FirstRowRiDefdMassgProgCfgMassgF FirstRowRiDefdMassgProgCfgMassgI FirstRowRiDefdMassgProgCfgMassPr FirstRowRiDefdMassgProgCfgM_0015 FirstRowRiDefdMassgProgCfgMassSe;
SIG_GROUP_ 528 CoolgLoadGroup 1 : CoolgLoadGroupCoolgLimd CoolgLoadGroupCoolgLoad2;
SIG_GROUP_ 528 EngT 1 : EngTEngT EngTQf;
SIG_GROUP_ 528 SeatDispBtnPsd 1 : SeatDispBtnPsdDrvrSeatDispBtnPsd SeatDispBtnPsdPassSeatDispBtnPsd;
SIG_GROUP_ 298 DoorsOpenerReq 1 : DoorsOpenerReqChks DoorsOpenerReqCntr DoorsOpenerReqDrvr DoorsOpenerReqLeRe DoorsOpenerReqPass DoorsOpenerReqRiRe DoorsOpenerReqTrigSrcDrvr DoorsOpenerReqTrigSrcLeRe DoorsOpenerReqTrigSrcPass DoorsOpenerReqTrigSrcRiRe DoorsOpenerReqVehMtnSts;
SIG_GROUP_ 298 SecRowRiDefdMassgProgCfg 1 : SecRowRiDefdMassgProgCfgMassgBag SecRowRiDefdMassgProgCfgMas_0000 SecRowRiDefdMassgProgCfgMas_0001 SecRowRiDefdMassgProgCfgMas_0002 SecRowRiDefdMassgProgCfgMas_0003 SecRowRiDefdMassgProgCfgMas_0004 SecRowRiDefdMassgProgCfgMas_0005 SecRowRiDefdMassgProgCfgMas_0006 SecRowRiDefdMassgProgCfgMas_0007 SecRowRiDefdMassgProgCfgMas_0008 SecRowRiDefdMassgProgCfgMas_0009 SecRowRiDefdMassgProgCfgMas_0010 SecRowRiDefdMassgProgCfgMas_0011 SecRowRiDefdMassgProgCfgMas_0012 SecRowRiDefdMassgProgCfgMas_0013 SecRowRiDefdMassgProgCfgMas_0014 SecRowRiDefdMassgProgCfgMassgFrq SecRowRiDefdMassgProgCfgMassgInt SecRowRiDefdMassgProgCfgMassProg SecRowRiDefdMassgProgCfgMas_0015 SecRowRiDefdMassgProgCfgMassSeqC;
SIG_GROUP_ 656 CnctSrvFragChRatReq 1 : CnctSrvFragChRatReqFragRatForCh1 CnctSrvFragChRatReqFragRatForCh2 CnctSrvFragChRatReqFragRatForCh3 CnctSrvFragChRatReqFragRatForCh4 CnctSrvFragChRatReqFragRatForCh5;
SIG_GROUP_ 768 EngNSafe 1 : EngNSafeEngN EngNSafeEngNChks EngNSafeEngNCntr EngNSafeEngNGrdt;
SIG_GROUP_ 784 CamSts 1 : CamStsCamCamFrntCalNotCmpl CamStsCamCamHeatrActv CamStsCamFrntBlkd1 CamStsCamFrntBlkd2 CamStsCamFrntBlkd3 CamStsCamFrntBlkd4 CamStsCamFrntBlkd5 CamStsCamFrntBlkd6 CamStsCamFrntBlkd7 CamStsCamFrntBlkd8 CamStsCamFrntCalNotStrtd CamStsCamFrntFaulty CamStsCamFrontEna CamStsCamMissCom CamStsChks CamStsCntr;
SIG_GROUP_ 464 RoadIncln 1 : RoadInclnQly RoadInclnRoadIncln;
SIG_GROUP_ 464 WipgInfo 1 : WipgInfoWipgSpdInfo WipgInfoWiprActv WipgInfoWiprInWipgAr;
SIG_GROUP_ 880 EngSt1WdSts 1 : EngSt1WdStsChks EngSt1WdStsCntr EngSt1WdStsEngSt1WdSts;
SIG_GROUP_ 896 IndcrPat 1 : IndcrPatCmd1WdTiOff IndcrPatCmd1WdTiOn;
SIG_GROUP_ 816 VehBattU 1 : VehBattUSysU VehBattUSysUQf;
SIG_GROUP_ 832 VehCfgPrm 1 : VehCfgPrmBlkIDBytePosn1 VehCfgPrmCCPBytePosn2 VehCfgPrmCCPBytePosn3 VehCfgPrmCCPBytePosn4 VehCfgPrmCCPBytePosn5 VehCfgPrmCCPBytePosn6 VehCfgPrmCCPBytePosn7 VehCfgPrmCCPBytePosn8;
SIG_GROUP_ 306 VehCfgPrmExt 1 : VehCfgPrmExtBlkIDBytePosn1 VehCfgPrmExtCCPBytePosn2 VehCfgPrmExtCCPBytePosn3 VehCfgPrmExtCCPBytePosn4 VehCfgPrmExtCCPBytePosn5 VehCfgPrmExtCCPBytePosn6 VehCfgPrmExtCCPBytePosn7 VehCfgPrmExtCCPBytePosn8;
SIG_GROUP_ 849 DrvrSeatHallPosExtDownLd 1 : DrvrSeatHallPosExtDownLdSeatCush DrvrSeatHallPosExtDownLdSeatHead DrvrSeatHallPosExtDownLdSea_0000;
SIG_GROUP_ 128 AmbLiMusicShowTyp 1 : AmbLiMusicShowTypAmbLiShowTyp AmbLiMusicShowTypIdPen;
SIG_GROUP_ 128 AmbLiWelcomeShowTyp 1 : AmbLiWelcomeShowTypAmbLiShowTyp AmbLiWelcomeShowTypIdPen;
SIG_GROUP_ 128 VehADMode 1 : VehADModeActReq VehADModeChks VehADModeCntr VehADModeReq;
SIG_GROUP_ 937 PosnBrief 1 : PosnBriefPosnLat PosnBriefPosnLgt;
SIG_GROUP_ 928 HmiElecAirDirModReq 1 : HmiElecAirDirModReqDrvrMod HmiElecAirDirModReqPassMod;
SIG_GROUP_ 928 HmiElecAirSwngReq 1 : HmiElecAirSwngReqDrvrLeRiSwng HmiElecAirSwngReqDrvrUpOnSwng HmiElecAirSwngReqPassLeRiSwng HmiElecAirSwngReqPassUpOnSwng;
SIG_GROUP_ 928 SecRowLeSeatDispMassgFct 1 : SecRowLeSeatDispMassgFctMassgInt SecRowLeSeatDispMassgFctMassgPro SecRowLeSeatDispMassgFctOnOff;
SIG_GROUP_ 645 TelmClimaTSet 1 : TelmClimaTSetHmiCmptmtTSpSpcl TelmClimaTSetTempRange;
SIG_GROUP_ 855 HmiEcoClimaSetg 1 : HmiEcoClimaSetgIdPen HmiEcoClimaSetgOnOff1;
SIG_GROUP_ 855 MirrPosnFromCldAtDrvr 1 : MirrPosnFromCldAtDrvrMirrPosnAdj MirrPosnFromCldAtDrvrMirrPo_0000;
SIG_GROUP_ 855 MirrPosnFromCldAtPass 1 : MirrPosnFromCldAtPassMirrPosnAdj MirrPosnFromCldAtPassMirrPo_0000;
SIG_GROUP_ 944 HmiElecAirDirCrtlReq 1 : HmiElecAirDirCrtlReqDrvrLePosX HmiElecAirDirCrtlReqDrvrLePosY HmiElecAirDirCrtlReqDrvrRiPosX HmiElecAirDirCrtlReqDrvrRiPosY HmiElecAirDirCrtlReqPassLePosX HmiElecAirDirCrtlReqPassLePosY HmiElecAirDirCrtlReqPassRiPosX HmiElecAirDirCrtlReqPassRiPosY;
SIG_GROUP_ 951 HmiFragraChRatReq 1 : HmiFragraChRatReqFragRatForCh1 HmiFragraChRatReqFragRatForCh2 HmiFragraChRatReqFragRatForCh3 HmiFragraChRatReqFragRatForCh4 HmiFragraChRatReqFragRatForCh5;
SIG_GROUP_ 570 DefrstSts 1 : DefrstStsMirrDefrst DefrstStsWinDefrstFrnt DefrstStsWinDefrstRe;
SIG_GROUP_ 196 LoadAndStoreReq 1 : LoadAndStoreReqErgoPosn LoadAndStoreReqErgoSetgEve LoadAndStoreReqIdPen LoadAndStoreReqInOutEasy;
SIG_GROUP_ 257 TrlrLampChkAutReq 1 : TrlrLampChkAutReqPen TrlrLampChkAutReqSts;
SIG_GROUP_ 152 DrvrDesDir 1 : DrvrDesDirChks DrvrDesDirCntr DrvrDesDirDrvrDesDir;
SIG_GROUP_ 309 ClimaBoostAutSet 1 : ClimaBoostAutSetColdAutoOnOff ClimaBoostAutSetColdDeltaTemp ClimaBoostAutSetDurOfFunction ClimaBoostAutSetHotAutoOnOff ClimaBoostAutSetHotDeltaTemp;
SIG_GROUP_ 309 ClimaRefreshAutSet 1 : ClimaRefreshAutSetActvtOnExit ClimaRefreshAutSetAutoOnOff ClimaRefreshAutSetDurOfFunction;
SIG_GROUP_ 180 ActvnOfHndlDoorLi 1 : ActvnOfHndlDoorLiHndlDoorLiDrvr ActvnOfHndlDoorLiHndlDoorLiDrvrR ActvnOfHndlDoorLiHndlDoorLiPass ActvnOfHndlDoorLiHndlDoorLiPassR;
SIG_GROUP_ 468 ActiveZoneIinfo 1 : ActiveZoneIinfoZone1ONOff ActiveZoneIinfoZone2ONOff ActiveZoneIinfoZone3ONOff;
SIG_GROUP_ 468 CrashStsSafe 1 : CrashStsSafeChks CrashStsSafeCntr CrashStsSafeSts;
SIG_GROUP_ 468 DrvrSeatDispMassgFct 1 : DrvrSeatDispMassgFctMassgInten DrvrSeatDispMassgFctMassgProg DrvrSeatDispMassgFctOnOff;
SIG_GROUP_ 468 PassSeatDispMassgFct 1 : PassSeatDispMassgFctMassgInten PassSeatDispMassgFctMassgProg PassSeatDispMassgFctOnOff;
SIG_GROUP_ 468 RemStrtHvCtrlReq 1 : RemStrtHvCtrlReqErsCmd RemStrtHvCtrlReqErsRunTime;
SIG_GROUP_ 958 WinOpenClsGlbReqFromTelm 1 : WinOpenClsGlbReqFromTelmWindowOp WinOpenClsGlbReqFromTelmWinOpenC;
SIG_GROUP_ 952 WinOpenAppReq 1 : WinOpenAppReqWindowOpenValue WinOpenAppReqWinOpenClsGlbSts;
